VERSION "10.7.5"

NS_ :

BS_:

BU_: ADAS_Info AMP CPD DUMMY_DEBUG DUMMY_ECU EASC HUD MHU XGW_Info

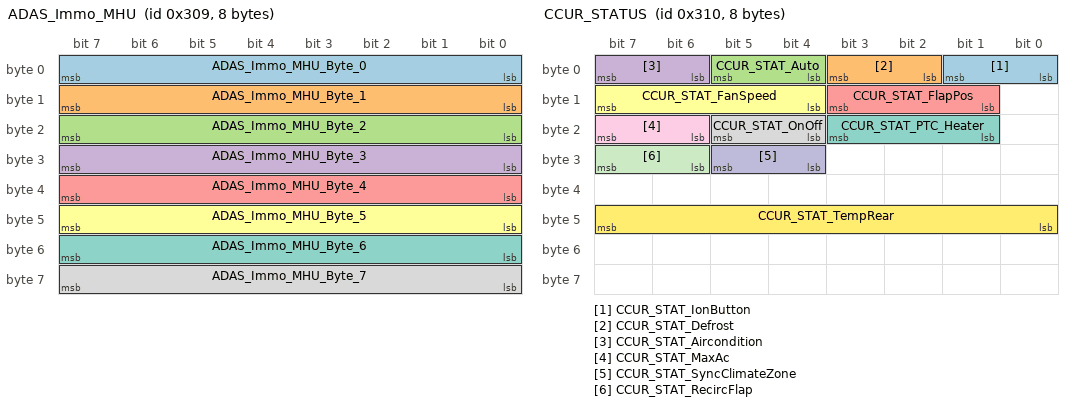
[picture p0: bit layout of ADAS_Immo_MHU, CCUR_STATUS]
BO_ 777 ADAS_Immo_MHU: 8 ADAS_Info
  SG_ ADAS_Immo_MHU_Byte_0 : 7|8@0+ (1,0) [0|255] "-" MHU
  SG_ ADAS_Immo_MHU_Byte_1 : 15|8@0+ (1,0) [0|255] "-" MHU
  SG_ ADAS_Immo_MHU_Byte_2 : 23|8@0+ (1,0) [0|255] "-" MHU
  SG_ ADAS_Immo_MHU_Byte_3 : 31|8@0+ (1,0) [0|255] "-" MHU
  SG_ ADAS_Immo_MHU_Byte_4 : 39|8@0+ (1,0) [0|255] "-" MHU
  SG_ ADAS_Immo_MHU_Byte_5 : 47|8@0+ (1,0) [0|255] "-" MHU
  SG_ ADAS_Immo_MHU_Byte_6 : 55|8@0+ (1,0) [0|255] "-" MHU
  SG_ ADAS_Immo_MHU_Byte_7 : 63|8@0+ (1,0) [0|255] "-" MHU

BO_ 784 CCUR_STATUS: 8 XGW_Info
  SG_ CCUR_STAT_IonButton : 1|2@0+ (1,0) [0|3] "-" MHU
  SG_ CCUR_STAT_Defrost : 3|2@0+ (1,0) [0|3] "" MHU
  SG_ CCUR_STAT_Auto : 5|2@0+ (1,0) [0|3] "" MHU
  SG_ CCUR_STAT_Aircondition : 7|2@0+ (1,0) [0|3] "-" MHU
  SG_ CCUR_STAT_FlapPos : 11|3@0+ (1,0) [0|7] "-" MHU
  SG_ CCUR_STAT_FanSpeed : 15|4@0+ (1,0) [0|15] "-" MHU
  SG_ CCUR_STAT_PTC_Heater : 19|3@0+ (1,0) [0|7] "" MHU
  SG_ CCUR_STAT_OnOff : 21|2@0+ (1,0) [0|3] "Bit" MHU
  SG_ CCUR_STAT_MaxAc : 23|2@0+ (1,0) [0|3] "" MHU
  SG_ CCUR_STAT_SyncClimateZone : 29|2@0+ (1,0) [0|3] "-" MHU
  SG_ CCUR_STAT_RecircFlap : 31|2@0+ (1,0) [0|3] "-" MHU
  SG_ CCUR_STAT_TempRear : 47|8@0+ (0.5,0) [16|32] "Degree C" MHU

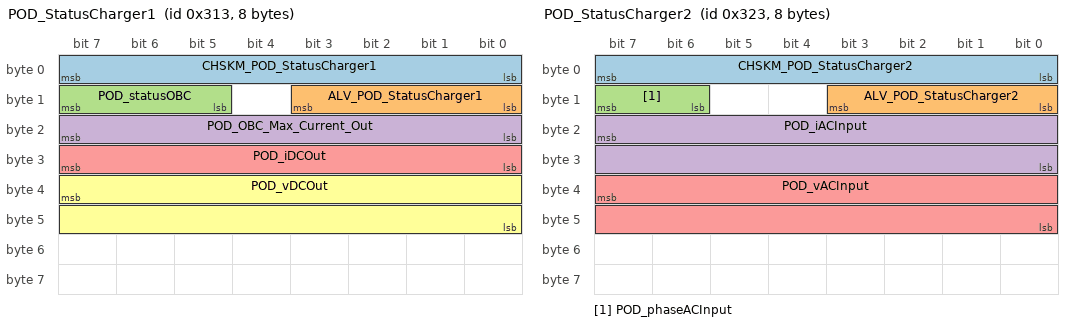
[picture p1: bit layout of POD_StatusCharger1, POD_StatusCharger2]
BO_ 787 POD_StatusCharger1: 8 XGW_Info
  SG_ CHSKM_POD_StatusCharger1 : 7|8@0+ (1,0) [0|255] "" MHU
  SG_ ALV_POD_StatusCharger1 : 11|4@0+ (1,0) [0|14] "" MHU
  SG_ POD_statusOBC : 15|3@0+ (1,0) [0|7] "" MHU
  SG_ POD_OBC_Max_Current_Out : 23|8@0+ (1,0) [0|64] "A" MHU
  SG_ POD_iDCOut : 31|8@0+ (1,0) [0|64] "A" MHU
  SG_ POD_vDCOut : 39|16@0+ (0.0625,0) [0|512] "V" MHU

BO_ 803 POD_StatusCharger2: 8 XGW_Info
  SG_ CHSKM_POD_StatusCharger2 : 7|8@0+ (1,0) [0|255] "" MHU
  SG_ ALV_POD_StatusCharger2 : 11|4@0+ (1,0) [0|14] "" MHU
  SG_ POD_phaseACInput : 15|2@0+ (1,0) [0|3] "" MHU
  SG_ POD_iACInput : 23|16@0+ (0.0625,0) [0|60] "A" MHU
  SG_ POD_vACInput : 39|16@0+ (0.0625,0) [0|512] "V" MHU

BO_ 804 HOD_Heating: 2 MHU
  SG_ Steering_HeatingControl : 7|2@0+ (1,0) [0|3] "" XGW_Info

BO_ 805 STWH_Feedback: 2 XGW_Info
  SG_ Steering_HeatingControlFdbk : 7|2@0+ (1,0) [0|3] "-" MHU

BO_ 806 POD_StatusDCDC1: 8 XGW_Info
  SG_ CHSKM_POD_StatusDCDC1 : 7|8@0+ (1,0) [0|255] "" MHU
  SG_ ALV_POD_StatusDCDC1 : 11|4@0+ (1,0) [0|14] "" MHU
  SG_ POD_statusDCDC : 14|3@0+ (1,0) [0|7] "" MHU
  SG_ POD_DCDC_Max_Current_Out : 23|8@0+ (1,0) [0|250] "A" MHU

BO_ 808 IC_RELATIVIME: 6 MHU
  SG_ T_SEC_COU_REL : 7|32@0+ (1,0) [0|4294967294] "s" XGW_Info
  SG_ T_DAY_COU_ABSL : 39|16@0+ (1,0) [0|65534] "Day" XGW_Info

BO_ 809 BCM_ODO: 8 XGW_Info
  SG_ CRC_BCM_ODO : 7|8@0+ (1,0) [0|255] "" MHU
  SG_ ALIV_BCM_ODO : 11|4@0+ (1,0) [0|14] "" MHU
  SG_ Odometer_BCM : 23|20@0+ (1,0) [0|999999] "km" MHU
  SG_ SECCAN_BCM_ODO : 63|8@0+ (1,0) [0|255] "" MHU

BO_ 816 IC_MILEAGE: 8 XGW_Info
  SG_ MILE_KM : 7|24@0+ (1,0) [0|999999] "km" ADAS_Info,AMP,CPD,EASC,HUD,MHU
  SG_ FLLV_FUTA : 31|8@0+ (1,0) [0|254] "l" ADAS_Info,AMP,CPD,EASC,HUD,MHU
  SG_ RNG : 51|12@0+ (1,0) [0|4094] "km" ADAS_Info,AMP,CPD,EASC,HUD,MHU
  SG_ ST_FLLV_FUTA_SPAR : 55|2@0+ (1,0) [0|3] "" ADAS_Info,AMP,CPD,EASC,HUD,MHU

BO_ 818 BMS_PackInfo: 8 XGW_Info
 SG_ Checksum_0x332 : 7|8@0+ (1,0) [0|255] "" MHU
 SG_ Rolling_Counter_0x332 : 11|4@0+ (1,0) [0|14] "" MHU
 SG_ BMS_PackCNom : 23|16@0+ (0.1,0) [0|6553.5] "kWh" MHU
 SG_ BMS_PackTemp_0x332 : 39|8@0+ (1,-40) [-40|215] "Degree C" MHU

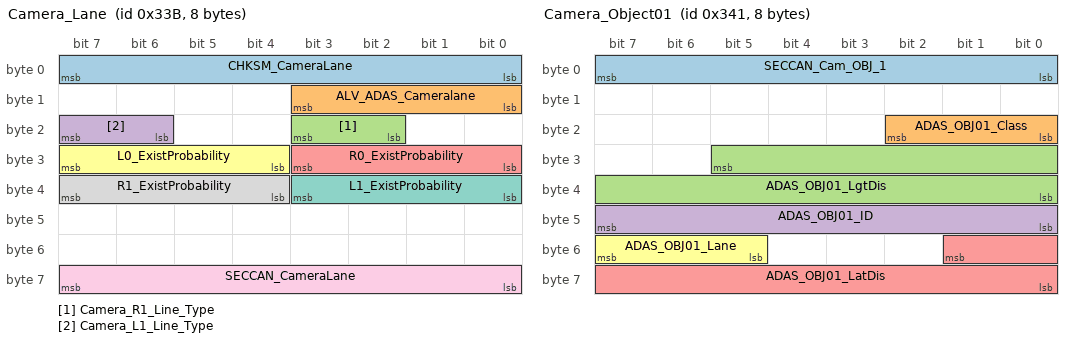
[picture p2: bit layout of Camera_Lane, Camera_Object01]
BO_ 827 Camera_Lane: 8 ADAS_Info
  SG_ CHKSM_CameraLane : 7|8@0+ (1,0) [0|255] "" MHU
  SG_ ALV_ADAS_Cameralane : 11|4@0+ (1,0) [0|14] "" MHU
  SG_ Camera_R1_Line_Type : 19|2@0+ (1,0) [0|3] "-" MHU
  SG_ Camera_L1_Line_Type : 23|2@0+ (1,0) [0|3] "-" MHU
  SG_ R0_ExistProbability : 27|4@0+ (0.1,0) [0|1] "-" MHU
  SG_ L0_ExistProbability : 31|4@0+ (0.1,0) [0|1] "-" MHU
  SG_ L1_ExistProbability : 35|4@0+ (0.1,0) [0|1] "-" MHU
  SG_ R1_ExistProbability : 39|4@0+ (0.1,0) [0|1] "-" MHU
  SG_ SECCAN_CameraLane : 63|8@0+ (1,0) [0|255] "" MHU

BO_ 833 Camera_Object01: 8 ADAS_Info
  SG_ SECCAN_Cam_OBJ_1 : 7|8@0+ (1,0) [0|255] "" MHU
  SG_ ADAS_OBJ01_Class : 18|3@0+ (1,0) [0|7] "-" MHU
  SG_ ADAS_OBJ01_LgtDis : 29|14@0+ (0.025,-10) [-10|399.575] "-" MHU
  SG_ ADAS_OBJ01_ID : 47|8@0+ (1,0) [0|255] "-" MHU
  SG_ ADAS_OBJ01_LatDis : 49|10@0+ (0.0293,-15.0146) [-15.0146|14.9593] "-" MHU
  SG_ ADAS_OBJ01_Lane : 55|3@0+ (1,0) [0|7] "-" MHU

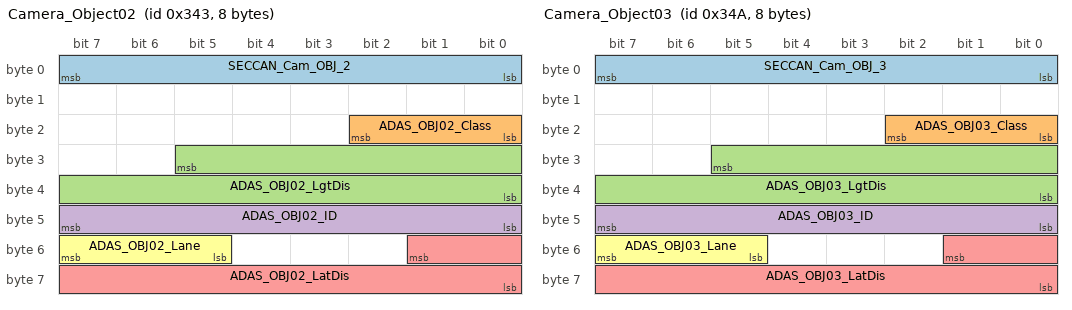
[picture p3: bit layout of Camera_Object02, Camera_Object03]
BO_ 835 Camera_Object02: 8 ADAS_Info
  SG_ SECCAN_Cam_OBJ_2 : 7|8@0+ (1,0) [0|255] "" MHU
  SG_ ADAS_OBJ02_Class : 18|3@0+ (1,0) [0|7] "-" MHU
  SG_ ADAS_OBJ02_LgtDis : 29|14@0+ (0.025,-10) [-10|399.575] "-" MHU
  SG_ ADAS_OBJ02_ID : 47|8@0+ (1,0) [0|255] "-" MHU
  SG_ ADAS_OBJ02_LatDis : 49|10@0+ (0.0293,-15.0146) [-15.0146|14.985] "-" MHU
  SG_ ADAS_OBJ02_Lane : 55|3@0+ (1,0) [0|7] "-" MHU

BO_ 838 POD_StatusDCDC2: 8 XGW_Info
  SG_ CHSKM_POD_StatusDCDC2 : 7|8@0+ (1,0) [0|255] "" MHU
  SG_ ALV_POD_StatusDCDC2 : 11|4@0+ (1,0) [0|14] "" MHU
  SG_ POD_vDCInput : 23|16@0+ (0.0625,0) [0|512] "V" MHU
  SG_ POD_iDCDCOutput : 39|16@0+ (0.0625,0) [0|300] "A" MHU
  SG_ POD_vDCDCOutput : 55|16@0+ (0.0625,0) [0|18] "V" MHU

BO_ 842 Camera_Object03: 8 ADAS_Info
  SG_ SECCAN_Cam_OBJ_3 : 7|8@0+ (1,0) [0|255] "" MHU
  SG_ ADAS_OBJ03_Class : 18|3@0+ (1,0) [0|7] "-" MHU
  SG_ ADAS_OBJ03_LgtDis : 29|14@0+ (0.025,-10) [-10|399.575] "-" MHU
  SG_ ADAS_OBJ03_ID : 47|8@0+ (1,0) [0|255] "-" MHU
  SG_ ADAS_OBJ03_LatDis : 49|10@0+ (0.0293,-15.0146) [-15.0146|14.985] "-" MHU
  SG_ ADAS_OBJ03_Lane : 55|3@0+ (1,0) [0|7] "-" MHU

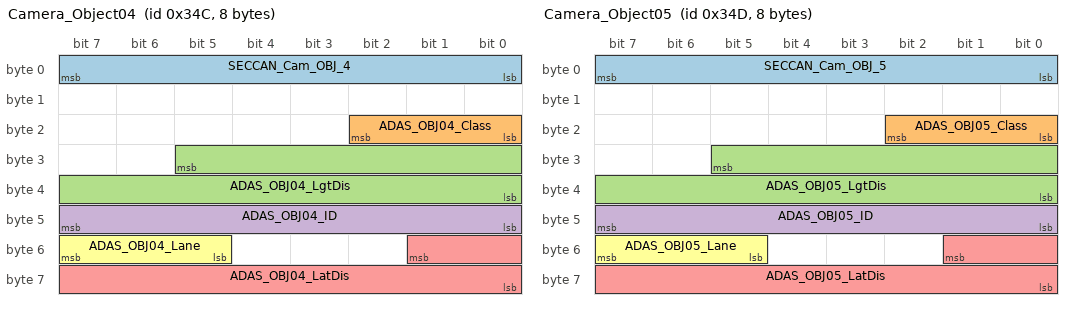
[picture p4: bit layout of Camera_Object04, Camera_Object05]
BO_ 844 Camera_Object04: 8 ADAS_Info
  SG_ SECCAN_Cam_OBJ_4 : 7|8@0+ (1,0) [0|255] "" MHU
  SG_ ADAS_OBJ04_Class : 18|3@0+ (1,0) [0|7] "-" MHU
  SG_ ADAS_OBJ04_LgtDis : 29|14@0+ (0.025,-10) [-10|399.575] "-" MHU
  SG_ ADAS_OBJ04_ID : 47|8@0+ (1,0) [0|255] "-" MHU
  SG_ ADAS_OBJ04_LatDis : 49|10@0+ (0.0293,-15.0146) [-15.0146|14.985] "-" MHU
  SG_ ADAS_OBJ04_Lane : 55|3@0+ (1,0) [0|7] "-" MHU

BO_ 845 Camera_Object05: 8 ADAS_Info
  SG_ SECCAN_Cam_OBJ_5 : 7|8@0+ (1,0) [0|255] "" MHU
  SG_ ADAS_OBJ05_Class : 18|3@0+ (1,0) [0|7] "-" MHU
  SG_ ADAS_OBJ05_LgtDis : 29|14@0+ (0.025,-10) [-10|399.575] "-" MHU
  SG_ ADAS_OBJ05_ID : 47|8@0+ (1,0) [0|255] "-" MHU
  SG_ ADAS_OBJ05_LatDis : 49|10@0+ (0.0293,-15.0146) [-15.0146|14.985] "-" MHU
  SG_ ADAS_OBJ05_Lane : 55|3@0+ (1,0) [0|7] "-" MHU

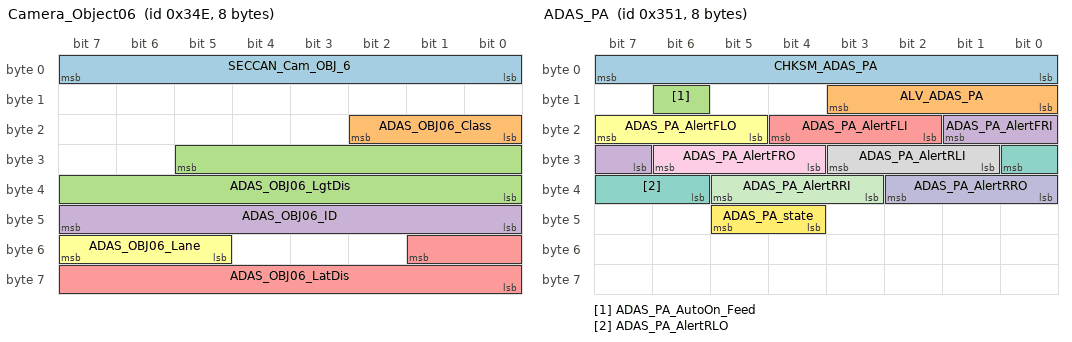
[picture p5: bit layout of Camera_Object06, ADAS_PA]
BO_ 846 Camera_Object06: 8 ADAS_Info
  SG_ SECCAN_Cam_OBJ_6 : 7|8@0+ (1,0) [0|255] "" MHU
  SG_ ADAS_OBJ06_Class : 18|3@0+ (1,0) [0|7] "-" MHU
  SG_ ADAS_OBJ06_LgtDis : 29|14@0+ (0.025,-10) [-10|399.575] "-" MHU
  SG_ ADAS_OBJ06_ID : 47|8@0+ (1,0) [0|255] "-" MHU
  SG_ ADAS_OBJ06_LatDis : 49|10@0+ (0.0293,-15.0146) [-15.0146|14.985] "-" MHU
  SG_ ADAS_OBJ06_Lane : 55|3@0+ (1,0) [0|7] "-" MHU

BO_ 849 ADAS_PA: 8 ADAS_Info
  SG_ CHKSM_ADAS_PA : 7|8@0+ (1,0) [0|255] "" HUD,MHU
  SG_ ALV_ADAS_PA : 11|4@0+ (1,0) [0|14] "" HUD,MHU
  SG_ ADAS_PA_AutoOn_Feed : 14|1@0+ (1,0) [0|1] "-" HUD,MHU
  SG_ ADAS_PA_AlertFRI : 17|3@0+ (1,0) [0|7] "-" HUD,MHU
  SG_ ADAS_PA_AlertFLI : 20|3@0+ (1,0) [0|7] "-" HUD,MHU
  SG_ ADAS_PA_AlertFLO : 23|3@0+ (1,0) [0|7] "-" HUD,MHU
  SG_ ADAS_PA_AlertRLO : 24|3@0+ (1,0) [0|7] "-" HUD,MHU
  SG_ ADAS_PA_AlertRLI : 27|3@0+ (1,0) [0|7] "-" HUD,MHU
  SG_ ADAS_PA_AlertFRO : 30|3@0+ (1,0) [0|7] "-" HUD,MHU
  SG_ ADAS_PA_AlertRRO : 34|3@0+ (1,0) [0|7] "-" HUD,MHU
  SG_ ADAS_PA_AlertRRI : 37|3@0+ (1,0) [0|7] "-" HUD,MHU
  SG_ ADAS_PA_state : 45|2@0+ (1,0) [0|3] "-" HUD,MHU

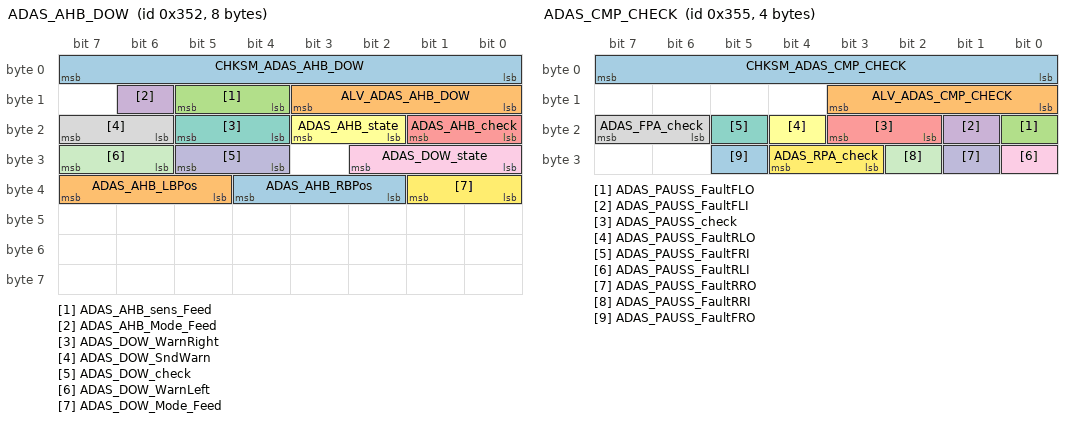
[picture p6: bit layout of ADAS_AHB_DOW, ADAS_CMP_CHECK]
BO_ 850 ADAS_AHB_DOW: 8 ADAS_Info
  SG_ CHKSM_ADAS_AHB_DOW : 7|8@0+ (1,0) [0|255] "" HUD,MHU
  SG_ ALV_ADAS_AHB_DOW : 11|4@0+ (1,0) [0|14] "" HUD,MHU
  SG_ ADAS_AHB_sens_Feed : 13|2@0+ (1,0) [0|3] "-" MHU
  SG_ ADAS_AHB_Mode_Feed : 14|1@0+ (1,0) [0|1] "-" MHU
  SG_ ADAS_AHB_check : 17|2@0+ (1,0) [0|3] "-" MHU
  SG_ ADAS_AHB_state : 19|2@0+ (1,0) [0|3] "-" MHU
  SG_ ADAS_DOW_WarnRight : 21|2@0+ (1,0) [0|3] "-" MHU
  SG_ ADAS_DOW_SndWarn : 23|2@0+ (1,0) [0|3] "-" MHU
  SG_ ADAS_DOW_state : 26|3@0+ (1,0) [0|7] "-" MHU
  SG_ ADAS_DOW_check : 29|2@0+ (1,0) [0|3] "-" MHU
  SG_ ADAS_DOW_WarnLeft : 31|2@0+ (1,0) [0|3] "-" MHU
  SG_ ADAS_DOW_Mode_Feed : 33|2@0+ (1,0) [0|3] "-" MHU
  SG_ ADAS_AHB_RBPos : 36|3@0+ (1,0) [0|7] "" MHU
  SG_ ADAS_AHB_LBPos : 39|3@0+ (1,0) [0|7] "-" MHU

BO_ 851 ADAS_CMP_ACC: 8 ADAS_Info
  SG_ CHKSM_ADAS_ACC : 7|8@0+ (1,0) [0|255] "" HUD,MHU
  SG_ ALV_ADAS_ACC : 11|4@0+ (1,0) [0|14] "" HUD,MHU
  SG_ ADAS_ACC_ObjDetec : 12|1@0+ (1,0) [0|1] "-" HUD,MHU
  SG_ ADAS_ISA_check : 14|2@0+ (1,0) [0|3] "-" HUD,MHU
  SG_ ADAS_ISA_Mode_SW_Feed : 15|1@0+ (1,0) [0|1] "-" HUD,MHU
  SG_ ADAS_TagSpeed_ICON_Feed : 18|3@0+ (1,0) [0|7] "-" HUD,MHU
  SG_ ADAS_ISA_PopUp_Feed : 23|4@0+ (1,0) [0|15] "-" HUD,MHU
  SG_ ADAS_ISA_Btn_Feed : 24|1@0+ (1,0) [0|1] "-" HUD,MHU
  SG_ ADAS_ACC_DistSet_upper_Feed : 25|1@0+ (1,0) [0|1] "-" HUD,MHU
  SG_ ADAS_ACC_TimeGapSet : 28|3@0+ (1,0) [0|7] "-" HUD,MHU
  SG_ ADAS_ACC_State : 31|3@0+ (1,0) [0|7] "-" HUD,MHU
  SG_ ADAS_ACC_TagSpeed : 39|8@0+ (1,0) [0|255] "km/h" HUD,MHU
  SG_ ADAS_ACC_PopUp_Feed : 43|4@0+ (1,0) [0|15] "-" HUD,MHU
  SG_ ADAS_ACC_check : 47|2@0+ (1,0) [0|3] "-" HUD,MHU
  SG_ ADAS_ISA_ICON_Feed : 50|3@0+ (1,0) [0|7] "-" HUD,MHU
  SG_ ADAS_ACC_DistSet_lower_Feed : 51|1@0+ (1,0) [0|1] "-" HUD,MHU
  SG_ ADAS_ACC_SpdSet_upper_Feed : 52|1@0+ (1,0) [0|1] "-" HUD,MHU
  SG_ ADAS_ACC_SpdSet_lower_Feed : 53|1@0+ (1,0) [0|1] "-" HUD,MHU
  SG_ ADAS_ACC_On_Feed : 54|1@0+ (1,0) [0|1] "-" HUD,MHU
  SG_ ADAS_ACC_Set_Feed : 55|1@0+ (1,0) [0|1] "-" HUD,MHU
  SG_ ADAS_ACC_CnlBtn_Feed : 56|1@0+ (1,0) [0|1] "-" HUD,MHU
  SG_ ADAS_ACC_Res_Feed : 57|1@0+ (1,0) [0|1] "-" HUD,MHU
  SG_ ADAS_ACC_ICON_Feed : 60|3@0+ (1,0) [0|7] "-" HUD,MHU
  SG_ ADAS_ISA_Status : 63|3@0+ (1,0) [0|7] "-" HUD,MHU

BO_ 852 MHU_ADAS_req: 8 MHU
  SG_ MHU_FCW_Mode : 1|2@0+ (1,0) [0|3] "-" ADAS_Info
  SG_ MHU_FCW_sens : 3|2@0+ (1,0) [0|3] "-" ADAS_Info
  SG_ MHU_AEB_Mode : 7|2@0+ (1,0) [0|3] "-" ADAS_Info
  SG_ MHU_RAEB_Mode : 9|2@0+ (1,0) [0|3] "-" ADAS_Info
  SG_ MHU_LA_sens : 11|2@0+ (1,0) [0|3] "-" ADAS_Info
  SG_ MHU_LA_AudWarning : 15|2@0+ (1,0) [0|3] "-" ADAS_Info
  SG_ MHU_BSD_On : 17|2@0+ (1,0) [0|3] "-" ADAS_Info
  SG_ MHU_ALC_ON : 19|2@0+ (1,0) [0|3] "-" ADAS_Info
  SG_ MHU_BSD_AudWarning : 21|2@0+ (1,0) [0|3] "-" ADAS_Info
  SG_ MHU_RCTA_On : 23|2@0+ (1,0) [0|3] "-" ADAS_Info
  SG_ MHU_RCTA_sens : 25|2@0+ (1,0) [0|3] "-" ADAS_Info
  SG_ MHU_PA_On : 27|2@0+ (1,0) [0|3] "-" ADAS_Info
  SG_ MHU_AHB_On : 29|2@0+ (1,0) [0|3] "-" ADAS_Info
  SG_ MHU_IA_Mode : 31|2@0+ (1,0) [0|3] "-" ADAS_Info
  SG_ MHU_TSR_Mode : 33|2@0+ (1,0) [0|3] "-" ADAS_Info
  SG_ MHU_DOW_Mode : 35|2@0+ (1,0) [0|3] "-" ADAS_Info
  SG_ MHU_AHB_sens : 37|2@0+ (1,0) [0|3] "-" ADAS_Info
  SG_ MHU_LA_Mode : 41|3@0+ (1,0) [0|7] "-" ADAS_Info
  SG_ MHU_SET_TSR_AudWarn : 45|2@0+ (1,0) [0|3] "-" ADAS_Info
  SG_ MHU_SET_TSR_SLAert : 47|2@0+ (1,0) [0|3] "-" ADAS_Info

BO_ 853 ADAS_CMP_CHECK: 4 ADAS_Info
  SG_ CHKSM_ADAS_CMP_CHECK : 7|8@0+ (1,0) [0|255] "" MHU
  SG_ ALV_ADAS_CMP_CHECK : 11|4@0+ (1,0) [0|14] "" MHU
  SG_ ADAS_PAUSS_FaultFLO : 16|1@0+ (1,0) [0|1] "-" MHU
  SG_ ADAS_PAUSS_FaultFLI : 17|1@0+ (1,0) [0|1] "-" MHU
  SG_ ADAS_PAUSS_check : 19|2@0+ (1,0) [0|3] "-" MHU
  SG_ ADAS_PAUSS_FaultRLO : 20|1@0+ (1,0) [0|1] "-" MHU
  SG_ ADAS_PAUSS_FaultFRI : 21|1@0+ (1,0) [0|1] "-" MHU
  SG_ ADAS_FPA_check : 23|2@0+ (1,0) [0|3] "-" MHU
  SG_ ADAS_PAUSS_FaultRLI : 24|1@0+ (1,0) [0|1] "-" MHU
  SG_ ADAS_PAUSS_FaultRRO : 25|1@0+ (1,0) [0|1] "-" MHU
  SG_ ADAS_PAUSS_FaultRRI : 26|1@0+ (1,0) [0|1] "-" MHU
  SG_ ADAS_RPA_check : 28|2@0+ (1,0) [0|3] "-" MHU
  SG_ ADAS_PAUSS_FaultFRO : 29|1@0+ (1,0) [0|1] "-" MHU

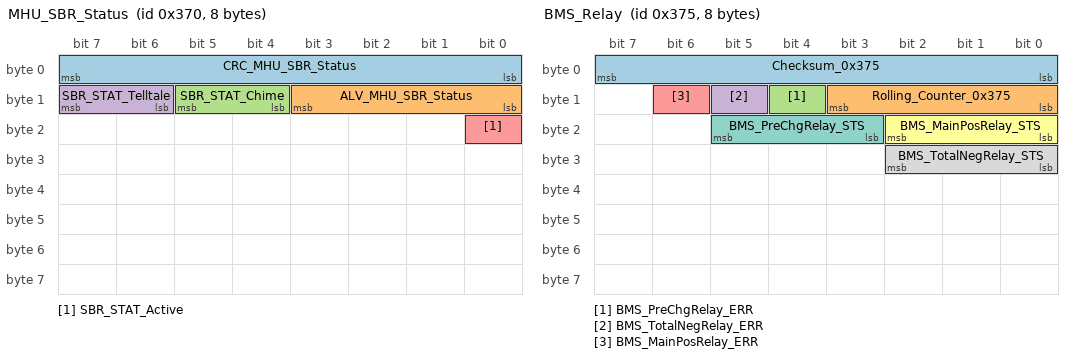
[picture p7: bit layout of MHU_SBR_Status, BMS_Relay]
BO_ 880 MHU_SBR_Status: 8 MHU
  SG_ CRC_MHU_SBR_Status : 7|8@0+ (1,0) [0|255] "" XGW_Info
  SG_ ALV_MHU_SBR_Status : 11|4@0+ (1,0) [0|14] "" XGW_Info
  SG_ SBR_STAT_Chime : 13|2@0+ (1,0) [0|3] "" XGW_Info
  SG_ SBR_STAT_Telltale : 15|2@0+ (1,0) [0|3] "" XGW_Info
  SG_ SBR_STAT_Active : 16|1@0+ (1,0) [0|1] "" XGW_Info

BO_ 885 BMS_Relay: 8 XGW_Info
  SG_ Checksum_0x375 : 7|8@0+ (1,0) [0|255] "" MHU
  SG_ Rolling_Counter_0x375 : 11|4@0+ (1,0) [0|14] "" MHU
  SG_ BMS_PreChgRelay_ERR : 12|1@0+ (1,0) [0|1] "" MHU
  SG_ BMS_TotalNegRelay_ERR : 13|1@0+ (1,0) [0|1] "" MHU
  SG_ BMS_MainPosRelay_ERR : 14|1@0+ (1,0) [0|1] "" MHU
  SG_ BMS_MainPosRelay_STS : 18|3@0+ (1,0) [0|7] "" MHU
  SG_ BMS_PreChgRelay_STS : 21|3@0+ (1,0) [0|7] "" MHU
  SG_ BMS_TotalNegRelay_STS : 26|3@0+ (1,0) [0|7] "" MHU

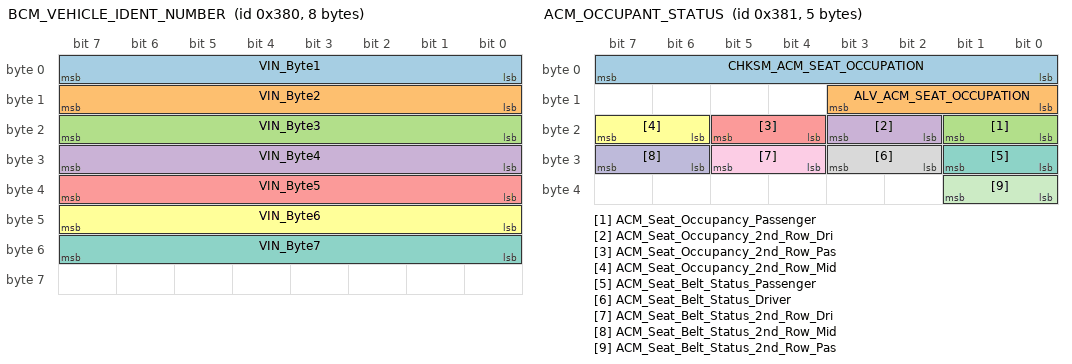
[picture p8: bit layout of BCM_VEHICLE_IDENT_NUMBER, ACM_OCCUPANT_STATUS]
BO_ 896 BCM_VEHICLE_IDENT_NUMBER: 8 XGW_Info
  SG_ VIN_Byte1 : 7|8@0+ (1,0) [0|255] "" ADAS_Info,AMP,CPD,EASC,HUD,MHU
  SG_ VIN_Byte2 : 15|8@0+ (1,0) [0|255] "" ADAS_Info,AMP,CPD,EASC,HUD,MHU
  SG_ VIN_Byte3 : 23|8@0+ (1,0) [0|255] "" ADAS_Info,AMP,CPD,EASC,HUD,MHU
  SG_ VIN_Byte4 : 31|8@0+ (1,0) [0|255] "" ADAS_Info,AMP,CPD,EASC,HUD,MHU
  SG_ VIN_Byte5 : 39|8@0+ (1,0) [0|255] "" ADAS_Info,AMP,CPD,EASC,HUD,MHU
  SG_ VIN_Byte6 : 47|8@0+ (1,0) [0|255] "" ADAS_Info,AMP,CPD,EASC,HUD,MHU
  SG_ VIN_Byte7 : 55|8@0+ (1,0) [0|255] "" ADAS_Info,AMP,CPD,EASC,HUD,MHU

BO_ 897 ACM_OCCUPANT_STATUS: 5 XGW_Info
  SG_ CHKSM_ACM_SEAT_OCCUPATION : 7|8@0+ (1,0) [0|255] "" MHU
  SG_ ALV_ACM_SEAT_OCCUPATION : 11|4@0+ (1,0) [0|14] "" MHU
  SG_ ACM_Seat_Occupancy_Passenger : 17|2@0+ (1,0) [0|3] "" MHU
  SG_ ACM_Seat_Occupancy_2nd_Row_Dri : 19|2@0+ (1,0) [0|3] "" MHU
  SG_ ACM_Seat_Occupancy_2nd_Row_Pas : 21|2@0+ (1,0) [0|3] "-" MHU
  SG_ ACM_Seat_Occupancy_2nd_Row_Mid : 23|2@0+ (1,0) [0|3] "-" MHU
  SG_ ACM_Seat_Belt_Status_Passenger : 25|2@0+ (1,0) [0|3] "" MHU
  SG_ ACM_Seat_Belt_Status_Driver : 27|2@0+ (1,0) [0|3] "" MHU
  SG_ ACM_Seat_Belt_Status_2nd_Row_Dri : 29|2@0+ (1,0) [0|3] "-" MHU
  SG_ ACM_Seat_Belt_Status_2nd_Row_Mid : 31|2@0+ (1,0) [0|3] "" MHU
  SG_ ACM_Seat_Belt_Status_2nd_Row_Pas : 33|2@0+ (1,0) [0|3] "-" MHU

BO_ 905 VCU_Sts3: 8 XGW_Info
  SG_ VCU_IMMO_Sts : 35|2@0+ (1,0) [0|3] "" MHU
  SG_ SECCAN_VCU_IMMO_Sts : 63|8@0+ (1,0) [0|255] "" Vector__XXX

BO_ 915 MHU_HudPositionSetting: 3 MHU
  SG_ MHU_SET_HudRotateLvl : 7|4@0+ (1,0) [0|15] "-" HUD
  SG_ MHU_SET_HudHeightLvl : 15|5@0+ (1,0) [0|31] "-" HUD

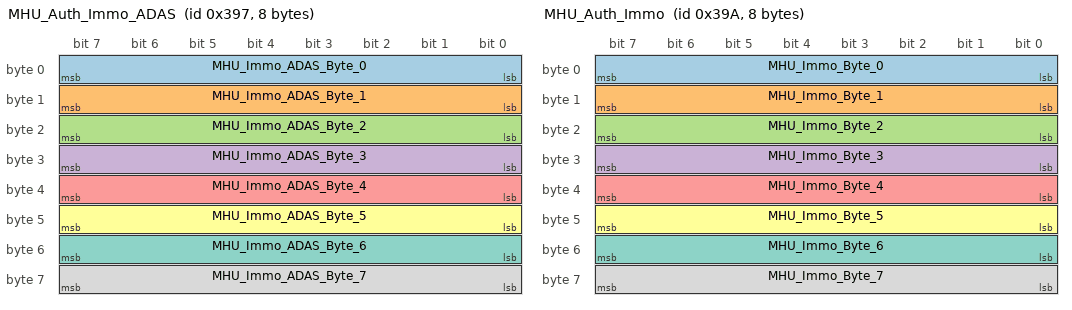
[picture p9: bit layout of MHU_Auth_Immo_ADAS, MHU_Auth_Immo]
BO_ 919 MHU_Auth_Immo_ADAS: 8 MHU
  SG_ MHU_Immo_ADAS_Byte_0 : 7|8@0+ (1,0) [0|255] "-" ADAS_Info
  SG_ MHU_Immo_ADAS_Byte_1 : 15|8@0+ (1,0) [0|255] "-" ADAS_Info
  SG_ MHU_Immo_ADAS_Byte_2 : 23|8@0+ (1,0) [0|255] "-" ADAS_Info
  SG_ MHU_Immo_ADAS_Byte_3 : 31|8@0+ (1,0) [0|255] "-" ADAS_Info
  SG_ MHU_Immo_ADAS_Byte_4 : 39|8@0+ (1,0) [0|255] "-" ADAS_Info
  SG_ MHU_Immo_ADAS_Byte_5 : 47|8@0+ (1,0) [0|255] "-" ADAS_Info
  SG_ MHU_Immo_ADAS_Byte_6 : 55|8@0+ (1,0) [0|255] "-" ADAS_Info
  SG_ MHU_Immo_ADAS_Byte_7 : 63|8@0+ (1,0) [0|255] "-" ADAS_Info

BO_ 922 MHU_Auth_Immo: 8 MHU
  SG_ MHU_Immo_Byte_0 : 7|8@0+ (1,0) [0|255] "-" XGW_Info
  SG_ MHU_Immo_Byte_1 : 15|8@0+ (1,0) [0|255] "-" XGW_Info
  SG_ MHU_Immo_Byte_2 : 23|8@0+ (1,0) [0|255] "" XGW_Info
  SG_ MHU_Immo_Byte_3 : 31|8@0+ (1,0) [0|255] "" XGW_Info
  SG_ MHU_Immo_Byte_4 : 39|8@0+ (1,0) [0|255] "" XGW_Info
  SG_ MHU_Immo_Byte_5 : 47|8@0+ (1,0) [0|255] "" XGW_Info
  SG_ MHU_Immo_Byte_6 : 55|8@0+ (1,0) [0|255] "" XGW_Info
  SG_ MHU_Immo_Byte_7 : 63|8@0+ (1,0) [0|255] "-" XGW_Info

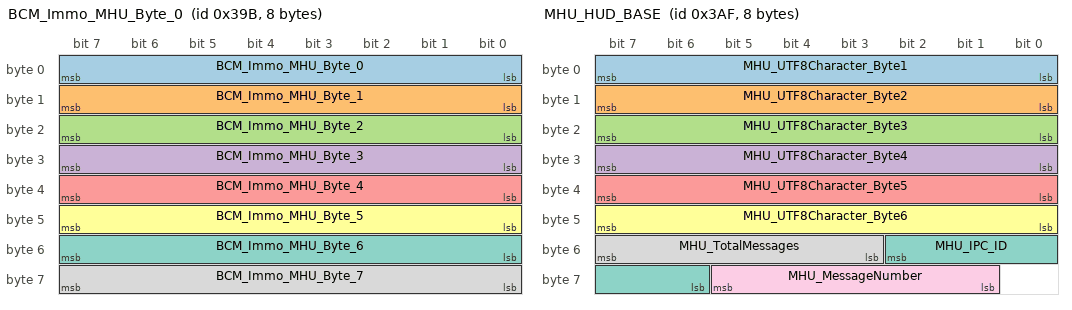
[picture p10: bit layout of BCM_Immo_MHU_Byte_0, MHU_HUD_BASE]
BO_ 923 BCM_Immo_MHU_Byte_0: 8 XGW_Info
  SG_ BCM_Immo_MHU_Byte_0 : 7|8@0+ (1,0) [0|255] "-" MHU
  SG_ BCM_Immo_MHU_Byte_1 : 15|8@0+ (1,0) [0|255] "-" MHU
  SG_ BCM_Immo_MHU_Byte_2 : 23|8@0+ (1,0) [0|255] "-" MHU
  SG_ BCM_Immo_MHU_Byte_3 : 31|8@0+ (1,0) [0|255] "-" MHU
  SG_ BCM_Immo_MHU_Byte_4 : 39|8@0+ (1,0) [0|255] "-" MHU
  SG_ BCM_Immo_MHU_Byte_5 : 47|8@0+ (1,0) [0|255] "" MHU
  SG_ BCM_Immo_MHU_Byte_6 : 55|8@0+ (1,0) [0|255] "-" MHU
  SG_ BCM_Immo_MHU_Byte_7 : 63|8@0+ (1,0) [0|255] "-" MHU

BO_ 925 BCM_HighBeam_PosReq: 4 XGW_Info
  SG_ BCM_AHB_Override : 17|2@0+ (1,0) [0|3] "" MHU

BO_ 943 MHU_HUD_BASE: 8 MHU
  SG_ MHU_UTF8Character_Byte1 : 7|8@0+ (1,0) [0|255] "-" HUD
  SG_ MHU_UTF8Character_Byte2 : 15|8@0+ (1,0) [0|255] "-" HUD
  SG_ MHU_UTF8Character_Byte3 : 23|8@0+ (1,0) [0|255] "-" HUD
  SG_ MHU_UTF8Character_Byte4 : 31|8@0+ (1,0) [0|255] "-" HUD
  SG_ MHU_UTF8Character_Byte5 : 39|8@0+ (1,0) [0|255] "-" HUD
  SG_ MHU_UTF8Character_Byte6 : 47|8@0+ (1,0) [0|255] "-" HUD
  SG_ MHU_IPC_ID : 50|5@0+ (1,0) [0|15] "Bit" HUD
  SG_ MHU_TotalMessages : 55|5@0+ (1,0) [0|31] "-" HUD
  SG_ MHU_MessageNumber : 61|5@0+ (1,0) [0|31] "-" HUD

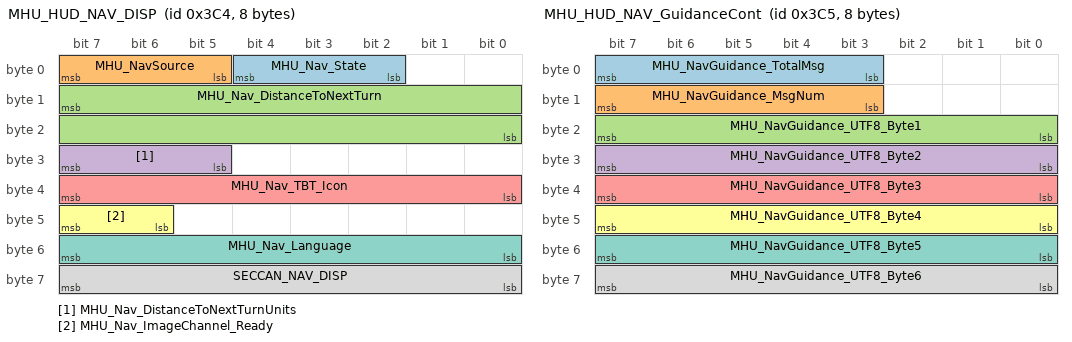
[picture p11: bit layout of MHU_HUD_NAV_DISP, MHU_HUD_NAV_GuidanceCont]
BO_ 964 MHU_HUD_NAV_DISP: 8 MHU
  SG_ MHU_Nav_State : 4|3@0+ (1,0) [0|7] "-" HUD
  SG_ MHU_NavSource : 7|3@0+ (1,0) [0|7] "-" HUD
  SG_ MHU_Nav_DistanceToNextTurn : 15|16@0+ (1,0) [0|65535] "-" HUD
  SG_ MHU_Nav_DistanceToNextTurnUnits : 31|3@0+ (1,0) [0|7] "-" HUD
  SG_ MHU_Nav_TBT_Icon : 39|8@0+ (1,0) [0|255] "-" HUD
  SG_ MHU_Nav_ImageChannel_Ready : 47|2@0+ (1,0) [0|3] "-" HUD
  SG_ MHU_Nav_Language : 55|8@0+ (1,0) [0|255] "" HUD
  SG_ SECCAN_NAV_DISP : 63|8@0+ (1,0) [0|255] "" HUD

BO_ 965 MHU_HUD_NAV_GuidanceCont: 8 MHU
  SG_ MHU_NavGuidance_TotalMsg : 7|5@0+ (1,0) [0|31] "-" HUD
  SG_ MHU_NavGuidance_MsgNum : 15|5@0+ (1,0) [0|31] "-" HUD
  SG_ MHU_NavGuidance_UTF8_Byte1 : 23|8@0+ (1,0) [0|255] "" HUD
  SG_ MHU_NavGuidance_UTF8_Byte2 : 31|8@0+ (1,0) [0|255] "" HUD
  SG_ MHU_NavGuidance_UTF8_Byte3 : 39|8@0+ (1,0) [0|255] "" HUD
  SG_ MHU_NavGuidance_UTF8_Byte4 : 47|8@0+ (1,0) [0|255] "" HUD
  SG_ MHU_NavGuidance_UTF8_Byte5 : 55|8@0+ (1,0) [0|255] "" HUD
  SG_ MHU_NavGuidance_UTF8_Byte6 : 63|8@0+ (1,0) [0|255] "" HUD

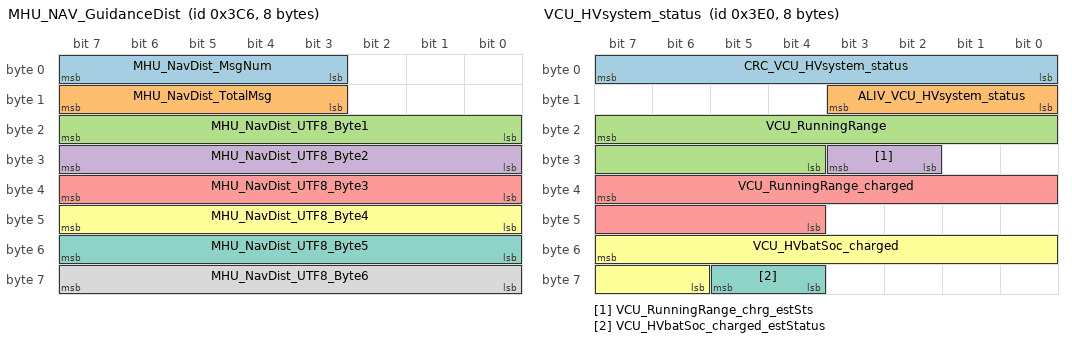
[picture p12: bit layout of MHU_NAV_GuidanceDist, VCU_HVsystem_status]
BO_ 966 MHU_NAV_GuidanceDist: 8 MHU
  SG_ MHU_NavDist_MsgNum : 7|5@0+ (1,0) [0|31] "" HUD
  SG_ MHU_NavDist_TotalMsg : 15|5@0+ (1,0) [0|31] "" HUD
  SG_ MHU_NavDist_UTF8_Byte1 : 23|8@0+ (1,0) [0|255] "" HUD
  SG_ MHU_NavDist_UTF8_Byte2 : 31|8@0+ (1,0) [0|255] "" HUD
  SG_ MHU_NavDist_UTF8_Byte3 : 39|8@0+ (1,0) [0|255] "" HUD
  SG_ MHU_NavDist_UTF8_Byte4 : 47|8@0+ (1,0) [0|255] "" HUD
  SG_ MHU_NavDist_UTF8_Byte5 : 55|8@0+ (1,0) [0|255] "" HUD
  SG_ MHU_NavDist_UTF8_Byte6 : 63|8@0+ (1,0) [0|255] "" HUD

BO_ 992 VCU_HVsystem_status: 8 XGW_Info
  SG_ CRC_VCU_HVsystem_status : 7|8@0+ (1,0) [0|255] "" HUD,MHU
  SG_ ALIV_VCU_HVsystem_status : 11|4@0+ (1,0) [0|14] "" HUD,MHU
  SG_ VCU_RunningRange : 23|12@0+ (0.5,0) [0|2047] "km" HUD,MHU
  SG_ VCU_RunningRange_chrg_estSts : 27|2@0+ (1,0) [0|3] "-" HUD,MHU
  SG_ VCU_RunningRange_charged : 39|12@0+ (0.5,0) [0|2047] "km" HUD,MHU
  SG_ VCU_HVbatSoc_charged : 55|10@0+ (0.1,0) [0|100] "%" HUD,MHU
  SG_ VCU_HVbatSoc_charged_estStatus : 61|2@0+ (1,0) [0|3] "-" HUD,MHU

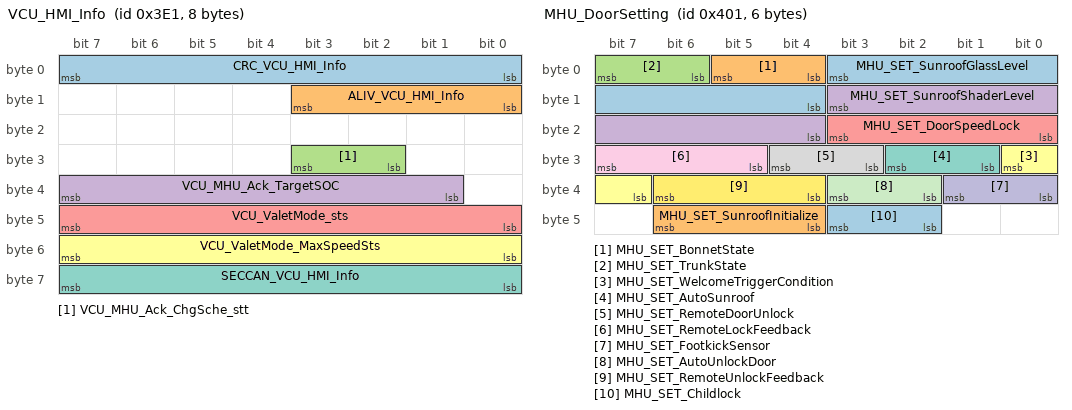
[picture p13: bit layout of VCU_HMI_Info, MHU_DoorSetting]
BO_ 993 VCU_HMI_Info: 8 XGW_Info
  SG_ CRC_VCU_HMI_Info : 7|8@0+ (1,0) [0|255] "" MHU
  SG_ ALIV_VCU_HMI_Info : 11|4@0+ (1,0) [0|14] "" MHU
  SG_ VCU_MHU_Ack_ChgSche_stt : 27|2@0+ (1,0) [0|3] "" MHU
  SG_ VCU_MHU_Ack_TargetSOC : 39|7@0+ (1,0) [10|100] "%" MHU
  SG_ VCU_ValetMode_sts : 47|8@0+ (1,0) [0|255] "" MHU
  SG_ VCU_ValetMode_MaxSpeedSts : 55|8@0+ (1,0) [0|255] "km/h" MHU
  SG_ SECCAN_VCU_HMI_Info : 63|8@0+ (1,0) [0|255] "" MHU

BO_ 1015 MFS_Control_Button: 8 XGW_Info
  SG_ CHSKM_MFS_Control_Button : 7|8@0+ (1,0) [0|255] "" ADAS_Info,HUD,MHU
  SG_ ALV_MFS_Control_Button : 11|4@0+ (1,0) [0|14] "" ADAS_Info,HUD,MHU
  SG_ MFS_VoiceRecognitionOn_Off : 15|3@0+ (1,0) [0|4] "Bit" HUD,MHU
  SG_ MFS_ISAControl : 17|2@0+ (1,0) [0|3] "Bit" ADAS_Info,HUD,MHU
  SG_ MFS_CruiseSpeedIncrease : 20|3@0+ (1,0) [0|4] "Bit" ADAS_Info,HUD,MHU
  SG_ MFS_TelephoneCall_EndCall : 23|3@0+ (1,0) [0|4] "Bit" HUD,MHU
  SG_ MFS_LKAControl : 25|2@0+ (1,0) [0|3] "Bit" ADAS_Info,HUD,MHU
  SG_ MFS_CruiseGapIncrease : 28|3@0+ (1,0) [0|4] "Bit" ADAS_Info,HUD,MHU
  SG_ MFS_CruiseOn_Off : 31|3@0+ (1,0) [0|4] "Bit" ADAS_Info,HUD,MHU
  SG_ MFS_CruiseGapDecrease : 34|3@0+ (1,0) [0|4] "Bit" ADAS_Info,HUD,MHU
  SG_ MFS_CAN_RESControl : 36|2@0+ (1,0) [0|3] "-" ADAS_Info,HUD
  SG_ MFS_CruiseSpeedDecrease : 39|3@0+ (1,0) [0|4] "Bit" ADAS_Info,HUD,MHU
  SG_ MFS_M2Control : 41|2@0+ (1,0) [0|3] "Bit" ADAS_Info,HUD
  SG_ MFS_SourseControl : 44|3@0+ (1,0) [0|4] "Bit" HUD,MHU
  SG_ MFS_UpControl : 47|3@0+ (1,0) [0|4] "Bit" EASC,HUD,MHU
  SG_ MFS_DownControl : 52|3@0+ (1,0) [0|4] "Bit" EASC,HUD,MHU
  SG_ MFS_LeftControl : 55|3@0+ (1,0) [0|4] "Bit" EASC,HUD,MHU
  SG_ MFS_Failure : 57|1@0+ (1,0) [0|1] "Bit" ADAS_Info,HUD,MHU
  SG_ MFS_RightControl : 60|3@0+ (1,0) [0|4] "Bit" EASC,HUD,MHU
  SG_ MFS_OK_Control : 63|3@0+ (1,0) [0|4] "Bit" HUD,MHU

BO_ 1020 XGW_FOTA_StsConfirm: 4 XGW_Info
  SG_ CRC_XGW_FOTA_StsConfirm : 7|8@0+ (1,0) [0|255] "" MHU
  SG_ ALIV_XGW_FOTA_StsConfirm : 11|4@0+ (1,0) [0|14] "" MHU
  SG_ XGW_FOTA_StateConfirm : 15|4@0+ (1,0) [0|14] "-" MHU
  SG_ XGW_FOTA_Error_Code : 23|8@0+ (1,0) [0|255] "-" MHU

BO_ 1025 MHU_DoorSetting: 6 MHU
  SG_ MHU_SET_SunroofGlassLevel : 3|8@0+ (1,0) [0|255] "%" XGW_Info
  SG_ MHU_SET_BonnetState : 5|2@0+ (1,0) [0|3] "-" XGW_Info
  SG_ MHU_SET_TrunkState : 7|2@0+ (1,0) [0|3] "-" XGW_Info
  SG_ MHU_SET_SunroofShaderLevel : 11|8@0+ (1,0) [0|255] "%" XGW_Info
  SG_ MHU_SET_DoorSpeedLock : 19|4@0+ (1,0) [0|7] "" XGW_Info
  SG_ MHU_SET_WelcomeTriggerCondition : 24|2@0+ (1,0) [0|3] "" XGW_Info
  SG_ MHU_SET_AutoSunroof : 26|2@0+ (1,0) [0|3] "" XGW_Info
  SG_ MHU_SET_RemoteDoorUnlock : 28|2@0+ (1,0) [0|3] "-" XGW_Info
  SG_ MHU_SET_RemoteLockFeedback : 31|3@0+ (1,0) [0|7] "-" XGW_Info
  SG_ MHU_SET_FootkickSensor : 33|2@0+ (1,0) [0|3] "-" XGW_Info
  SG_ MHU_SET_AutoUnlockDoor : 35|2@0+ (1,0) [0|3] "" XGW_Info
  SG_ MHU_SET_RemoteUnlockFeedback : 38|3@0+ (1,0) [0|7] "" XGW_Info
  SG_ MHU_SET_Childlock : 43|2@0+ (1,0) [0|3] "" XGW_Info
  SG_ MHU_SET_SunroofInitialize : 46|3@0+ (1,0) [0|7] "" XGW_Info

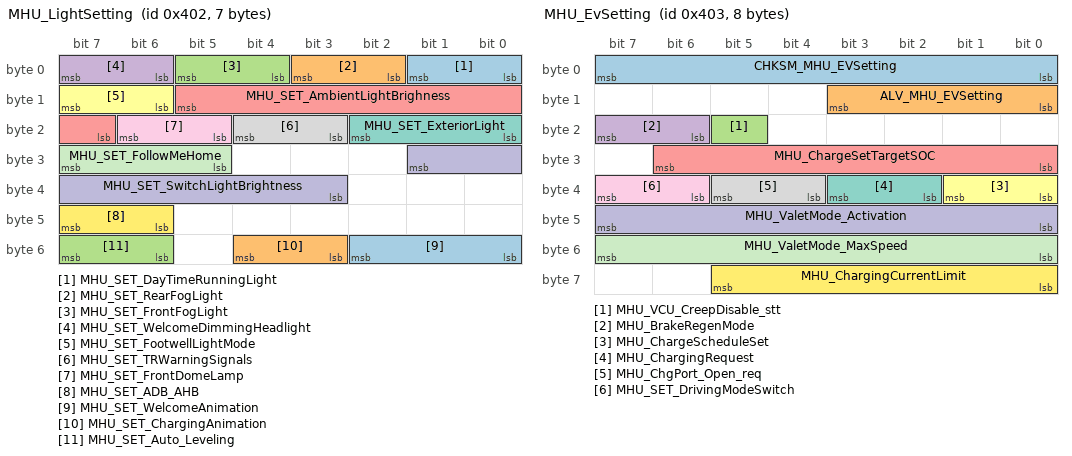
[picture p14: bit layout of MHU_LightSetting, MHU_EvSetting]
BO_ 1026 MHU_LightSetting: 7 MHU
  SG_ MHU_SET_DayTimeRunningLight : 1|2@0+ (1,0) [0|3] "-" XGW_Info
  SG_ MHU_SET_RearFogLight : 3|2@0+ (1,0) [0|3] "" XGW_Info
  SG_ MHU_SET_FrontFogLight : 5|2@0+ (1,0) [0|3] "" XGW_Info
  SG_ MHU_SET_WelcomeDimmingHeadlight : 7|2@0+ (1,0) [0|3] "" XGW_Info
  SG_ MHU_SET_AmbientLightBrighness : 13|7@0+ (1,0) [0|100] "%" XGW_Info
  SG_ MHU_SET_FootwellLightMode : 15|2@0+ (1,0) [0|3] "-" XGW_Info
  SG_ MHU_SET_ExteriorLight : 18|3@0+ (1,0) [0|7] "" XGW_Info
  SG_ MHU_SET_TRWarningSignals : 20|2@0+ (1,0) [0|3] "" XGW_Info
  SG_ MHU_SET_FrontDomeLamp : 22|2@0+ (1,0) [0|3] "" XGW_Info
  SG_ MHU_SET_SwitchLightBrightness : 25|7@0+ (1,0) [0|100] "%" XGW_Info
  SG_ MHU_SET_FollowMeHome : 31|3@0+ (1,0) [0|7] "" XGW_Info
  SG_ MHU_SET_ADB_AHB : 47|2@0+ (1,0) [0|3] "" XGW_Info
  SG_ MHU_SET_WelcomeAnimation : 50|3@0+ (1,0) [0|5] "" XGW_Info
  SG_ MHU_SET_ChargingAnimation : 52|2@0+ (1,0) [0|3] "" XGW_Info
  SG_ MHU_SET_Auto_Leveling : 55|2@0+ (1,0) [0|3] "-" XGW_Info

BO_ 1027 MHU_EvSetting: 8 MHU
  SG_ CHKSM_MHU_EVSetting : 7|8@0+ (1,0) [0|255] "" XGW_Info
  SG_ ALV_MHU_EVSetting : 11|4@0+ (1,0) [0|14] "" XGW_Info
  SG_ MHU_VCU_CreepDisable_stt : 21|1@0+ (1,0) [0|1] "" XGW_Info
  SG_ MHU_BrakeRegenMode : 23|2@0+ (1,0) [0|3] "" XGW_Info
  SG_ MHU_ChargeSetTargetSOC : 30|7@0+ (1,0) [10|100] "%" XGW_Info
  SG_ MHU_ChargeScheduleSet : 33|2@0+ (1,0) [0|3] "" XGW_Info
  SG_ MHU_ChargingRequest : 35|2@0+ (1,0) [0|3] "-" XGW_Info
  SG_ MHU_ChgPort_Open_req : 37|2@0+ (1,0) [0|3] "-" XGW_Info
  SG_ MHU_SET_DrivingModeSwitch : 39|2@0+ (1,0) [0|3] "-" XGW_Info
  SG_ MHU_ValetMode_Activation : 47|8@0+ (1,0) [0|255] "" ADAS_Info,XGW_Info
  SG_ MHU_ValetMode_MaxSpeed : 55|8@0+ (1,0) [0|255] "km/h" XGW_Info
  SG_ MHU_ChargingCurrentLimit : 61|6@0+ (1,0) [0|62] "A" XGW_Info

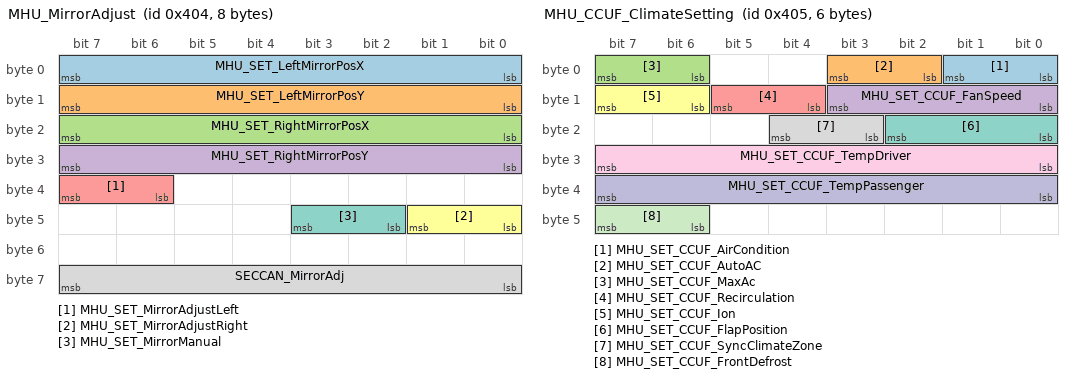
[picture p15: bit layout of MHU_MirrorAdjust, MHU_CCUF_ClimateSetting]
BO_ 1028 MHU_MirrorAdjust: 8 MHU
  SG_ MHU_SET_LeftMirrorPosX : 7|8@0+ (1,-15) [-15|15] "deg" XGW_Info
  SG_ MHU_SET_LeftMirrorPosY : 15|8@0+ (1,-15) [-15|15] "deg" XGW_Info
  SG_ MHU_SET_RightMirrorPosX : 23|8@0+ (1,-15) [-15|15] "deg" XGW_Info
  SG_ MHU_SET_RightMirrorPosY : 31|8@0+ (1,-15) [-15|15] "deg" XGW_Info
  SG_ MHU_SET_MirrorAdjustLeft : 39|2@0+ (1,0) [0|3] "-" XGW_Info
  SG_ MHU_SET_MirrorAdjustRight : 41|2@0+ (1,0) [0|3] "-" XGW_Info
  SG_ MHU_SET_MirrorManual : 43|2@0+ (1,0) [0|3] "" XGW_Info
  SG_ SECCAN_MirrorAdj : 63|8@0+ (1,0) [0|255] "" XGW_Info

BO_ 1029 MHU_CCUF_ClimateSetting: 6 MHU
  SG_ MHU_SET_CCUF_AirCondition : 1|2@0+ (1,0) [0|3] "" XGW_Info
  SG_ MHU_SET_CCUF_AutoAC : 3|2@0+ (1,0) [0|3] "" XGW_Info
  SG_ MHU_SET_CCUF_MaxAc : 7|2@0+ (1,0) [0|3] "" XGW_Info
  SG_ MHU_SET_CCUF_FanSpeed : 11|4@0+ (1,0) [0|7] "-" XGW_Info
  SG_ MHU_SET_CCUF_Recirculation : 13|2@0+ (1,0) [0|3] "" XGW_Info
  SG_ MHU_SET_CCUF_Ion : 15|2@0+ (1,0) [0|3] "-" XGW_Info
  SG_ MHU_SET_CCUF_FlapPosition : 18|3@0+ (1,0) [0|7] "-" XGW_Info
  SG_ MHU_SET_CCUF_SyncClimateZone : 20|2@0+ (1,0) [0|3] "-" XGW_Info
  SG_ MHU_SET_CCUF_TempDriver : 31|8@0+ (0.5,0) [16|32] "Degree C" XGW_Info
  SG_ MHU_SET_CCUF_TempPassenger : 39|8@0+ (0.5,0) [16|32] "Degree C" XGW_Info
  SG_ MHU_SET_CCUF_FrontDefrost : 47|2@0+ (1,0) [0|3] "" XGW_Info

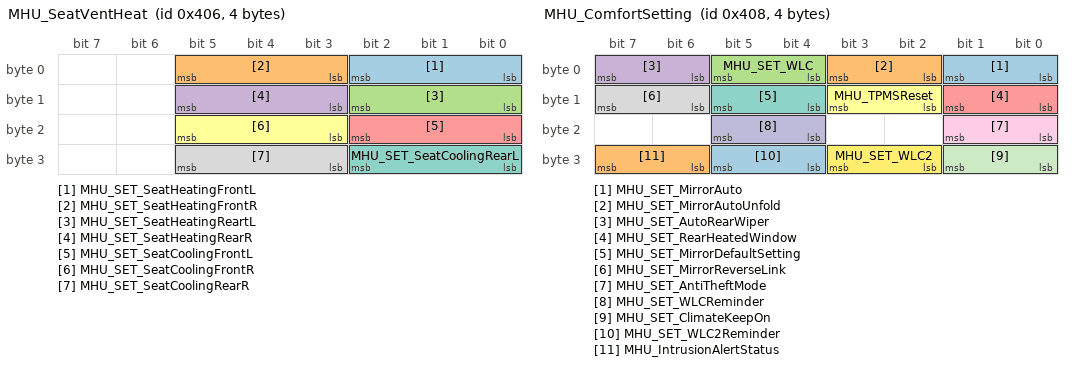
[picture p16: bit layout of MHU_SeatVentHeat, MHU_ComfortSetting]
BO_ 1030 MHU_SeatVentHeat: 4 MHU
  SG_ MHU_SET_SeatHeatingFrontL : 2|3@0+ (1,0) [0|7] "-" XGW_Info
  SG_ MHU_SET_SeatHeatingFrontR : 5|3@0+ (1,0) [0|7] "-" XGW_Info
  SG_ MHU_SET_SeatHeatingReartL : 10|3@0+ (1,0) [0|7] "-" XGW_Info
  SG_ MHU_SET_SeatHeatingRearR : 13|3@0+ (1,0) [0|7] "-" XGW_Info
  SG_ MHU_SET_SeatCoolingFrontL : 18|3@0+ (1,0) [0|7] "-" XGW_Info
  SG_ MHU_SET_SeatCoolingFrontR : 21|3@0+ (1,0) [0|7] "" XGW_Info
  SG_ MHU_SET_SeatCoolingRearL : 26|3@0+ (1,0) [0|7] "" XGW_Info
  SG_ MHU_SET_SeatCoolingRearR : 29|3@0+ (1,0) [0|7] "-" XGW_Info

BO_ 1032 MHU_ComfortSetting: 4 MHU
  SG_ MHU_SET_MirrorAuto : 1|2@0+ (1,0) [0|3] "" XGW_Info
  SG_ MHU_SET_MirrorAutoUnfold : 3|2@0+ (1,0) [0|3] "" XGW_Info
  SG_ MHU_SET_WLC : 5|2@0+ (1,0) [0|3] "-" XGW_Info
  SG_ MHU_SET_AutoRearWiper : 7|2@0+ (1,0) [0|3] "-" XGW_Info
  SG_ MHU_SET_RearHeatedWindow : 9|2@0+ (1,0) [0|3] "" XGW_Info
  SG_ MHU_TPMSReset : 11|2@0+ (1,0) [0|3] "" XGW_Info
  SG_ MHU_SET_MirrorDefaultSetting : 13|2@0+ (1,0) [0|3] "" XGW_Info
  SG_ MHU_SET_MirrorReverseLink : 15|2@0+ (1,0) [0|3] "-" XGW_Info
  SG_ MHU_SET_AntiTheftMode : 17|2@0+ (1,0) [0|3] "" XGW_Info
  SG_ MHU_SET_WLCReminder : 21|2@0+ (1,0) [0|3] "" XGW_Info
  SG_ MHU_SET_ClimateKeepOn : 25|2@0+ (1,0) [0|3] "" XGW_Info
  SG_ MHU_SET_WLC2 : 27|2@0+ (1,0) [0|3] "-" XGW_Info
  SG_ MHU_SET_WLC2Reminder : 29|2@0+ (1,0) [0|3] "-" XGW_Info
  SG_ MHU_IntrusionAlertStatus : 31|2@0+ (1,0) [0|3] "-" XGW_Info

BO_ 1033 ADAS_WarnMsg: 8 ADAS_Info
  SG_ CHSKM_ADAS_WarnMsg : 7|8@0+ (1,0) [0|255] "" MHU
  SG_ ALV_ADAS_WarnMsg : 11|4@0+ (1,0) [0|14] "" MHU
  SG_ ADAS_Warning_Flag_1 : 12|1@0+ (1,0) [0|1] "" MHU
  SG_ ADAS_Warning_Flag_2 : 13|1@0+ (1,0) [0|1] "" MHU
  SG_ ADAS_Warning_Flag_3 : 14|1@0+ (1,0) [0|1] "" MHU
  SG_ ADAS_Warning_Flag_4 : 15|1@0+ (1,0) [0|1] "" MHU
  SG_ ADAS_Warning_Flag_5 : 16|1@0+ (1,0) [0|1] "" MHU
  SG_ ADAS_Warning_Flag_6 : 17|1@0+ (1,0) [0|1] "" MHU
  SG_ ADAS_Warning_Flag_7 : 18|1@0+ (1,0) [0|1] "" MHU
  SG_ ADAS_Warning_Flag_8 : 19|1@0+ (1,0) [0|1] "" MHU
  SG_ ADAS_Warning_Flag_9 : 20|1@0+ (1,0) [0|1] "" MHU
  SG_ ADAS_Warning_Flag_10 : 21|1@0+ (1,0) [0|1] "" MHU
  SG_ ADAS_Warning_Flag_11 : 22|1@0+ (1,0) [0|1] "" MHU
  SG_ ADAS_Warning_Flag_12 : 23|1@0+ (1,0) [0|1] "" MHU
  SG_ ADAS_Warning_Flag_13 : 24|1@0+ (1,0) [0|1] "" MHU
  SG_ ADAS_Warning_Flag_14 : 25|1@0+ (1,0) [0|1] "" MHU
  SG_ ADAS_Warning_Flag_15 : 26|1@0+ (1,0) [0|1] "" MHU
  SG_ ADAS_Warning_Flag_16 : 27|1@0+ (1,0) [0|1] "" MHU
  SG_ ADAS_Warning_Flag_17 : 28|1@0+ (1,0) [0|1] "" MHU
  SG_ ADAS_Warning_Flag_18 : 29|1@0+ (1,0) [0|1] "" MHU
  SG_ ADAS_Warning_Flag_19 : 30|1@0+ (1,0) [0|1] "" MHU
  SG_ ADAS_Warning_Flag_20 : 31|1@0+ (1,0) [0|1] "" MHU
  SG_ ADAS_Warning_Flag_21 : 32|1@0+ (1,0) [0|1] "" MHU
  SG_ ADAS_Warning_Flag_22 : 33|1@0+ (1,0) [0|1] "" MHU
  SG_ ADAS_Warning_Flag_23 : 34|1@0+ (1,0) [0|1] "" MHU
  SG_ ADAS_Warning_Flag_24 : 35|1@0+ (1,0) [0|1] "" MHU
  SG_ ADAS_Warning_Flag_25 : 36|1@0+ (1,0) [0|1] "" MHU
  SG_ ADAS_Warning_Flag_26 : 37|1@0+ (1,0) [0|1] "" MHU
  SG_ ADAS_Warning_Flag_27 : 38|1@0+ (1,0) [0|1] "" MHU
  SG_ ADAS_Warning_Flag_28 : 39|1@0+ (1,0) [0|1] "" MHU
  SG_ ADAS_Warning_Flag_29 : 40|1@0+ (1,0) [0|1] "" MHU
  SG_ ADAS_Warning_Flag_30 : 41|1@0+ (1,0) [0|1] "" MHU
  SG_ ADAS_Warning_Flag_31 : 42|1@0+ (1,0) [0|1] "" MHU
  SG_ ADAS_Warning_Flag_32 : 43|1@0+ (1,0) [0|1] "" MHU
  SG_ ADAS_Warning_Flag_33 : 44|1@0+ (1,0) [0|1] "" MHU
  SG_ ADAS_Warning_Flag_34 : 45|1@0+ (1,0) [0|1] "" MHU
  SG_ ADAS_Warning_Flag_35 : 46|1@0+ (1,0) [0|1] "" MHU
  SG_ ADAS_Warning_Flag_36 : 47|1@0+ (1,0) [0|1] "" MHU
  SG_ ADAS_Warning_Flag_37 : 48|1@0+ (1,0) [0|1] "" MHU
  SG_ ADAS_Warning_Flag_38 : 49|1@0+ (1,0) [0|1] "" MHU
  SG_ ADAS_Warning_Flag_39 : 50|1@0+ (1,0) [0|1] "" MHU
  SG_ ADAS_Warning_Flag_40 : 51|1@0+ (1,0) [0|1] "" MHU
  SG_ ADAS_Warning_Flag_41 : 52|1@0+ (1,0) [0|1] "" MHU
  SG_ ADAS_Warning_Flag_42 : 53|1@0+ (1,0) [0|1] "" MHU
  SG_ ADAS_Warning_Flag_43 : 54|1@0+ (1,0) [0|1] "" MHU
  SG_ ADAS_Warning_Flag_44 : 55|1@0+ (1,0) [0|1] "" MHU
  SG_ ADAS_Warning_Flag_45 : 56|1@0+ (1,0) [0|1] "" MHU
  SG_ ADAS_Warning_Flag_46 : 57|1@0+ (1,0) [0|1] "" MHU
  SG_ ADAS_Warning_Flag_47 : 58|1@0+ (1,0) [0|1] "" MHU
  SG_ ADAS_Warning_Flag_48 : 59|1@0+ (1,0) [0|1] "" MHU
  SG_ ADAS_Warning_Flag_49 : 60|1@0+ (1,0) [0|1] "" MHU
  SG_ ADAS_Warning_Flag_50 : 61|1@0+ (1,0) [0|1] "" MHU
  SG_ ADAS_Warning_Flag_51 : 62|1@0+ (1,0) [0|1] "" MHU
  SG_ ADAS_Warning_Flag_52 : 63|1@0+ (1,0) [0|1] "" MHU

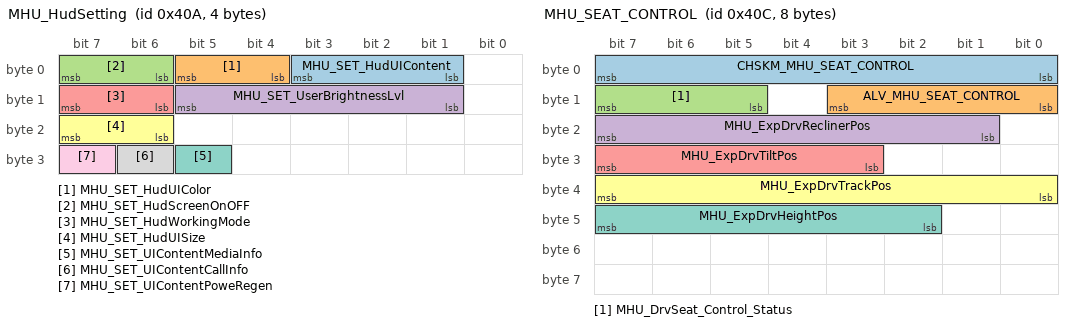
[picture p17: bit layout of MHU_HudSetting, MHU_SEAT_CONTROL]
BO_ 1034 MHU_HudSetting: 4 MHU
  SG_ MHU_SET_HudUIContent : 3|3@0+ (1,0) [0|7] "-" HUD
  SG_ MHU_SET_HudUIColor : 5|2@0+ (1,0) [0|3] "-" HUD
  SG_ MHU_SET_HudScreenOnOFF : 7|2@0+ (1,0) [0|3] "-" HUD
  SG_ MHU_SET_UserBrightnessLvl : 13|5@0+ (1,0) [0|31] "-" HUD
  SG_ MHU_SET_HudWorkingMode : 15|2@0+ (1,0) [0|3] "-" HUD
  SG_ MHU_SET_HudUISize : 23|2@0+ (1,0) [0|3] "-" HUD
  SG_ MHU_SET_UIContentMediaInfo : 29|1@0+ (1,0) [0|1] "" HUD
  SG_ MHU_SET_UIContentCallInfo : 30|1@0+ (1,0) [0|1] "" HUD
  SG_ MHU_SET_UIContentPoweRegen : 31|1@0+ (1,0) [0|1] "" HUD

BO_ 1035 MHU_Avas_Setting: 1 MHU
  SG_ MHU_SET_AvasSound : 1|2@0+ (1,0) [0|3] "-" XGW_Info

BO_ 1036 MHU_SEAT_CONTROL: 8 MHU
  SG_ CHSKM_MHU_SEAT_CONTROL : 7|8@0+ (1,0) [0|255] "" XGW_Info
  SG_ ALV_MHU_SEAT_CONTROL : 11|4@0+ (1,0) [0|14] "" XGW_Info
  SG_ MHU_DrvSeat_Control_Status : 15|3@0+ (1,0) [0|7] "-" XGW_Info
  SG_ MHU_ExpDrvReclinerPos : 23|7@0+ (1,0) [0|127] "degree" XGW_Info
  SG_ MHU_ExpDrvTiltPos : 31|5@0+ (1,0) [0|31] "mm" XGW_Info
  SG_ MHU_ExpDrvTrackPos : 39|8@0+ (1,0) [0|255] "mm" XGW_Info
  SG_ MHU_ExpDrvHeightPos : 47|6@0+ (1,0) [0|63] "mm" XGW_Info

BO_ 1037 MHU_DIGIT_SPEED: 5 MHU
  SG_ CHKSM_MHU_DIGIT_SPEED : 7|8@0+ (1,0) [0|255] "" ADAS_Info,HUD,XGW_Info
  SG_ ALV_MHU_DIGIT_SPEED : 11|4@0+ (1,0) [0|14] "" ADAS_Info,HUD,XGW_Info
  SG_ MHU_DigitSpeed : 23|9@0+ (1,0) [0|300] "km/h" ADAS_Info,HUD,XGW_Info

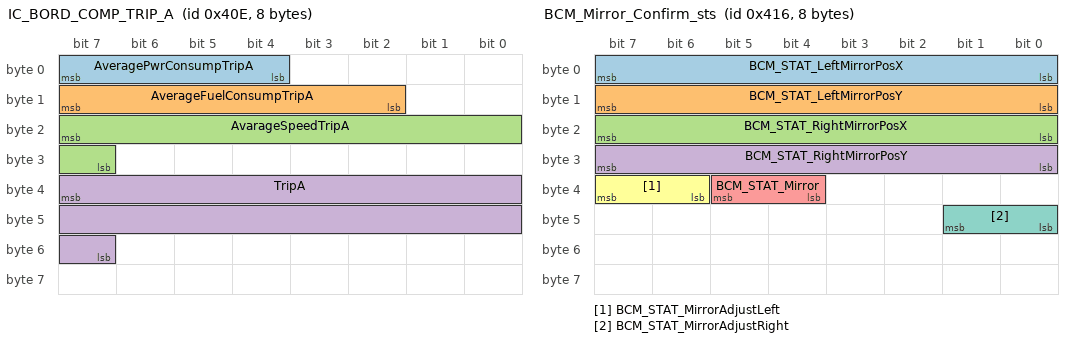
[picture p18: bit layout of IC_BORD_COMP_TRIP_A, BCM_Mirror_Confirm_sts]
BO_ 1038 IC_BORD_COMP_TRIP_A: 8 MHU
  SG_ AveragePwrConsumpTripA : 7|4@0+ (1,0) [0|10] "km/kWh" DUMMY_DEBUG,XGW_Info
  SG_ AverageFuelConsumpTripA : 15|6@0+ (1,0) [0|51] "l/100Km" DUMMY_DEBUG,XGW_Info
  SG_ AvarageSpeedTripA : 23|9@0+ (1,0) [0|300] "kmh" DUMMY_DEBUG,XGW_Info
  SG_ TripA : 39|17@0+ (0.1,0) [0|9999.9] "km" DUMMY_DEBUG,XGW_Info

BO_ 1039 IC_BORD_COMP_TRIP_B: 8 MHU
  SG_ AveragePwrConsumpTripB : 7|4@0+ (1,0) [0|10] "km/kWh" DUMMY_DEBUG,XGW_Info
  SG_ AverageFuelConsumpTripB : 15|6@0+ (1,0) [0|51] "l/100Km" DUMMY_DEBUG,XGW_Info
  SG_ AvarageSpeedTripB : 23|9@0+ (1,0) [0|300] "kmh" DUMMY_DEBUG,XGW_Info
  SG_ TripB : 39|17@0+ (0.1,0) [0|9999.9] "km" DUMMY_DEBUG,XGW_Info

BO_ 1040 IC_BORD_COMP_TRIP_Auto: 8 MHU
  SG_ AveragePwrConsumpTripAuto : 7|4@0+ (1,0) [0|10] "km/kWh" DUMMY_DEBUG,XGW_Info
  SG_ AverageFuelConsumpTripAuto : 15|6@0+ (1,0) [0|51] "l/100Km" DUMMY_DEBUG,XGW_Info
  SG_ AvarageSpeedTripAuto : 23|9@0+ (1,0) [0|300] "kmh" DUMMY_DEBUG,XGW_Info
  SG_ TripAuto : 39|17@0+ (0.1,0) [0|9999.9] "km" DUMMY_DEBUG,XGW_Info

BO_ 1046 BCM_Mirror_Confirm_sts: 8 XGW_Info
  SG_ BCM_STAT_LeftMirrorPosX : 7|8@0+ (1,-15) [-15|15] "deg" MHU
  SG_ BCM_STAT_LeftMirrorPosY : 15|8@0+ (1,-15) [-15|15] "deg" MHU
  SG_ BCM_STAT_RightMirrorPosX : 23|8@0+ (1,-15) [-15|15] "deg" MHU
  SG_ BCM_STAT_RightMirrorPosY : 31|8@0+ (1,-15) [-15|15] "deg" MHU
  SG_ BCM_STAT_Mirror : 37|2@0+ (1,0) [0|3] "" MHU
  SG_ BCM_STAT_MirrorAdjustLeft : 39|2@0+ (1,0) [0|3] "-" MHU
  SG_ BCM_STAT_MirrorAdjustRight : 41|2@0+ (1,0) [0|3] "" MHU

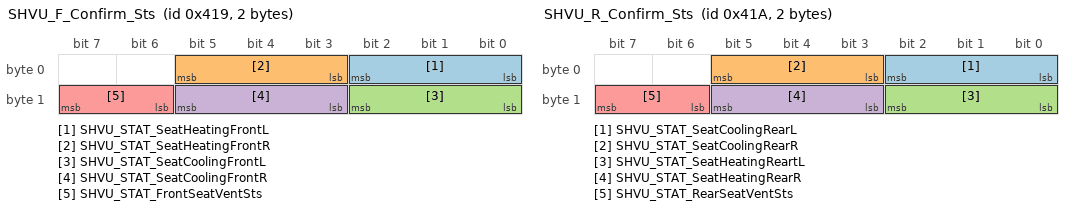
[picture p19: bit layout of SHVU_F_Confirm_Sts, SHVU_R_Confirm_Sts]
BO_ 1049 SHVU_F_Confirm_Sts: 2 XGW_Info
  SG_ SHVU_STAT_SeatHeatingFrontL : 2|3@0+ (1,0) [0|7] "-" MHU
  SG_ SHVU_STAT_SeatHeatingFrontR : 5|3@0+ (1,0) [0|7] "-" MHU
  SG_ SHVU_STAT_SeatCoolingFrontL : 10|3@0+ (1,0) [0|7] "-" MHU
  SG_ SHVU_STAT_SeatCoolingFrontR : 13|3@0+ (1,0) [0|7] "" MHU
  SG_ SHVU_STAT_FrontSeatVentSts : 15|2@0+ (1,0) [0|3] "" MHU

BO_ 1050 SHVU_R_Confirm_Sts: 2 XGW_Info
  SG_ SHVU_STAT_SeatCoolingRearL : 2|3@0+ (1,0) [0|7] "-" MHU
  SG_ SHVU_STAT_SeatCoolingRearR : 5|3@0+ (1,0) [0|7] "" MHU
  SG_ SHVU_STAT_SeatHeatingReartL : 10|3@0+ (1,0) [0|7] "" MHU
  SG_ SHVU_STAT_SeatHeatingRearR : 13|3@0+ (1,0) [0|7] "" MHU
  SG_ SHVU_STAT_RearSeatVentSts : 15|2@0+ (1,0) [0|3] "" MHU

BO_ 1052 PSM_SEAT_POSITION: 3 XGW_Info
  SG_ CHKSM_PSM_SEAT_POSITION : 7|8@0+ (1,0) [0|255] "" MHU
  SG_ AVL_PSM_SEAT_POSITION : 11|4@0+ (1,0) [0|14] "-" MHU
  SG_ PSM_Seat_track_pos_Dri : 19|2@0+ (1,0) [0|3] "" MHU
  SG_ PSM_Seat_track_posPas : 21|2@0+ (1,0) [0|3] "" MHU

BO_ 1053 BCM_Comfort_Confirm_sts: 8 XGW_Info
  SG_ BCM_STAT_AutoRearWiper : 1|2@0+ (1,0) [0|3] "-" MHU
  SG_ BCM_STAT_MirrorFoldSetting : 3|2@0+ (1,0) [0|3] "" MHU
  SG_ BCM_STAT_IMMO_KeyfobID2 : 7|3@0+ (1,0) [0|7] "" MHU
  SG_ BCM_STAT_MirrorAutoUnfold : 9|2@0+ (1,0) [0|3] "-" MHU
  SG_ BCM_STAT_MirrorReverseLink : 11|2@0+ (1,0) [0|3] "" MHU
  SG_ BCM_STAT_MirrorDefaultSTATting : 13|2@0+ (1,0) [0|3] "-" MHU
  SG_ BCM_STAT_WelcomeTriggerCondition : 15|2@0+ (1,0) [0|3] "" MHU
  SG_ BCM_STAT_FrontDomeLamp : 17|2@0+ (1,0) [0|3] "-" MHU
  SG_ BCM_STAT_FollowMeHome : 20|3@0+ (1,0) [0|7] "-" MHU
  SG_ BCM_STAT_ExteriorLight : 23|3@0+ (1,0) [0|7] "-" MHU
  SG_ BCM_STAT_RemoteLockFeedback : 26|3@0+ (1,0) [0|7] "-" MHU
  SG_ BCM_STAT_RemoteDoorUnlock : 28|2@0+ (1,0) [0|3] "" MHU
  SG_ BCM_STAT_AutoDoorUnlock : 30|2@0+ (1,0) [0|3] "" MHU
  SG_ BCM_STAT_AmbientLightBrighness : 39|7@0+ (1,0) [0|100] "%" MHU
  SG_ BCM_STAT_WiperServiceMode : 42|2@0+ (1,0) [0|3] "" MHU
  SG_ BCM_STAT_IMMO_KeyfobID : 45|2@0+ (1,0) [0|3] "" MHU
  SG_ BCM_STAT_RearHeatedWindowMirror : 47|2@0+ (1,0) [0|3] "" MHU
  SG_ BCM_STAT_AntiTheftMode : 50|3@0+ (1,0) [0|7] "-" MHU
  SG_ BCM_STAT_ClimateKeepOnSts : 53|2@0+ (1,0) [0|3] "" MHU
  SG_ BCM_STAT_FKSfeedback : 55|2@0+ (1,0) [0|3] "" MHU
  SG_ SECCAN_CmftCnfrm : 63|8@0+ (1,0) [0|255] "" MHU

CM_ BO_ 777 "ADAS IMMO Data to MHU";
CM_ BO_ 784 "CCU_R_Status";
CM_ BO_ 787 "POD StatusCharger1";
CM_ BO_ 803 "POD StatusCharger2";
CM_ BO_ 804 "HOD Heating Control";
CM_ BO_ 805 "Heating Control- Feedback";
CM_ BO_ 806 "POD StatusDCDC1";
CM_ BO_ 808 "IC RELATIVIME";
CM_ BO_ 809 "BCM_ODO";
CM_ BO_ 816 "IC_MILEAGE
";
CM_ BO_ 818  "BMS Pack information ";
CM_ SG_ 818 Checksum_0x332 "Checksum";
CM_ SG_ 818 Rolling_Counter_0x332 "Rolling Counter";
CM_ SG_ 818 BMS_PackCNom "Nominal capacity of the battery pack";
CM_ SG_ 818 BMS_PackTemp_0x332 "Pack Temperature ";
CM_ BO_ 827 "Camera Left/right lane type signals";
CM_ BO_ 833 "Camera Object 1 signals";
CM_ BO_ 835 "Camera Object 2 signals";
CM_ BO_ 838 "POD Status2";
CM_ BO_ 842 "Camera Object 3 signals";
CM_ BO_ 844 "Camera Object 4 signals";
CM_ BO_ 845 "Camera Object 5 signals";
CM_ BO_ 846 "Camera Object 6 signals";
CM_ BO_ 849 "ADAS Parking Assist";
CM_ BO_ 850 "ADAS Auto headlight high beam control and Door Open Warning";
CM_ BO_ 851 "ADAS Adaptive Cruise Control";
CM_ BO_ 852 "MHU ADAS request";
CM_ BO_ 853 "ADAS component check";
CM_ BO_ 885 "BMS Relay";
CM_ BO_ 896 "BCM vehicle identifier number";
CM_ BO_ 897 "ACM seatbelt and buckle status for seatbelt reminder";
CM_ BO_ 905 "VCU_status";
CM_ BO_ 915 "MHU_HudPositionSetting";
CM_ BO_ 919 "MHU Authentication signal";
CM_ BO_ 922 "MHU_Authentication information";
CM_ BO_ 923 "GW_BCM_Immo_MHU_Byte";
CM_ BO_ 925 "BCM hight beam position request";
CM_ BO_ 943 "MHU_HUD_BASE";
CM_ BO_ 964 "MHU HUD NAV DISP";
CM_ BO_ 965 "MHU_HUD_NAV_GuidanceCont";
CM_ BO_ 966 "MHU NAV GuidanceDist";
CM_ BO_ 992 "VCU High Voltage System Status";
CM_ BO_ 993 "VCU_HMI_Info.";
CM_ BO_ 1015 "MFS Control Button";
CM_ BO_ 1020 "XGW FOTA confirm status";
CM_ BO_ 1025 "MHU Door Setting";
CM_ BO_ 1026 "MHU Light Setting";
CM_ BO_ 1027 "MHU Driving Mode Setting";
CM_ BO_ 1028 "MHU Mirror Adjust";
CM_ BO_ 1029 "MHU Climate Setting";
CM_ BO_ 1030 "MHU Seat Vent Heat";
CM_ BO_ 1032 "MHU Comfort Setting";
CM_ BO_ 1033 "ADAS WarnMsg";
CM_ BO_ 1034 "MHU HudSetting";
CM_ BO_ 1035 "MHU Avas Setting";
CM_ BO_ 1036 "MHU_SEAT_CONTROL";
CM_ BO_ 1037 "Display Vehicle speed CAN Signal sent by MHU";
CM_ BO_ 1038 "IC BORD COMP TRIP B";
CM_ BO_ 1039 "IC BORD COMP TRIP B";
CM_ BO_ 1040 "IC_BORD_COMP_TRIP_Auto";
CM_ BO_ 1046 "BCM Mirror Confirm Sts";
CM_ BO_ 1049 "SHVU F Confirm Sts";
CM_ BO_ 1050 "SHVU R Confirm Sts";
CM_ BO_ 1052 "PSM seat position";
CM_ BO_ 1053 "BCM Comfortable Confirm status";
CM_ SG_ 777 ADAS_Immo_MHU_Byte_0 "ADAS Authentication signal byte 0 with MHU";
CM_ SG_ 777 ADAS_Immo_MHU_Byte_1 "ADAS Authentication signal byte 1 with MHU";
CM_ SG_ 777 ADAS_Immo_MHU_Byte_2 "ADAS Authentication signal byte 2 with MHU";
CM_ SG_ 777 ADAS_Immo_MHU_Byte_3 "ADAS Authentication signal byte 3 with MHU";
CM_ SG_ 777 ADAS_Immo_MHU_Byte_4 "ADAS Authentication signal byte 4 with MHU";
CM_ SG_ 777 ADAS_Immo_MHU_Byte_5 "ADAS Authentication signal byte 5 with MHU";
CM_ SG_ 777 ADAS_Immo_MHU_Byte_6 "ADAS Authentication signal byte 6 with MHU";
CM_ SG_ 777 ADAS_Immo_MHU_Byte_7 "ADAS Authentication signal byte 7 with MHU";
CM_ SG_ 784 CCUR_STAT_IonButton "Status if the ionisator is active";
CM_ SG_ 784 CCUR_STAT_Defrost "Status activation of Defrost mode";
CM_ SG_ 784 CCUR_STAT_Auto "Status activation of auto mode";
CM_ SG_ 784 CCUR_STAT_Aircondition "Aircondition status";
CM_ SG_ 784 CCUR_STAT_FlapPos "Request for flap position";
CM_ SG_ 784 CCUR_STAT_FanSpeed "Blower settings Fan Speed for climate system";
CM_ SG_ 784 CCUR_STAT_PTC_Heater "CCU status for PTC heater";
CM_ SG_ 784 CCUR_STAT_OnOff "Status On  Off button for clima";
CM_ SG_ 784 CCUR_STAT_MaxAc "Status activation of MAX AC mode";
CM_ SG_ 784 CCUR_STAT_SyncClimateZone "Status dual clima automatic";
CM_ SG_ 784 CCUR_STAT_RecircFlap "Recirculation flap status, 100% fresh air, 0% recirculation mode";
CM_ SG_ 784 CCUR_STAT_TempRear "
CCU status for temperature regulationr driver (Display Temperature)";
CM_ SG_ 787 CHSKM_POD_StatusCharger1 "Check sum";
CM_ SG_ 787 ALV_POD_StatusCharger1 "Alive counter";
CM_ SG_ 787 POD_statusOBC "OBC status";
CM_ SG_ 787 POD_OBC_Max_Current_Out "Max DC current OBC able to output";
CM_ SG_ 787 POD_iDCOut "POD measured output current on OBC output";
CM_ SG_ 787 POD_vDCOut "POD measured bus voltage at OBC output";
CM_ SG_ 803 CHSKM_POD_StatusCharger2 "Check sum";
CM_ SG_ 803 ALV_POD_StatusCharger2 "Alive counter";
CM_ SG_ 803 POD_iACInput "POD measured current on AC input";
CM_ SG_ 803 POD_vACInput "POD measured voltage on AC input";
CM_ SG_ 804 Steering_HeatingControl "Steering Heating Control";
CM_ SG_ 805 Steering_HeatingControlFdbk "Steering Heating Control Feedback";
CM_ SG_ 806 CHSKM_POD_StatusDCDC1 "Check sum";
CM_ SG_ 806 ALV_POD_StatusDCDC1 "Alive counter";
CM_ SG_ 806 POD_statusDCDC "DCDC status";
CM_ SG_ 806 POD_DCDC_Max_Current_Out "Max LV current DCDC able to output";
CM_ SG_ 808 T_SEC_COU_REL "This counter counts the seconds synchronously to the system clock.";
CM_ SG_ 808 T_DAY_COU_ABSL "Relative time
";
CM_ SG_ 809 CRC_BCM_ODO "Checksum";
CM_ SG_ 809 ALIV_BCM_ODO "Alive counter";
CM_ SG_ 809 Odometer_BCM "Odometer infomation for IPC.";
CM_ SG_ 809 SECCAN_BCM_ODO "Seed generated from Secure CAN algorithm";
CM_ SG_ 816 MILE_KM "Mileage information
";
CM_ SG_ 816 FLLV_FUTA "The fuel level of  tank. 255 value invalid";
CM_ SG_ 816 RNG "Calculated range of IPC";
CM_ SG_ 816 ST_FLLV_FUTA_SPAR "State of the tank reserve indicator 

";
CM_ SG_ 827 CHKSM_CameraLane "Checksum";
CM_ SG_ 827 ALV_ADAS_Cameralane "Alive Counter";
CM_ SG_ 827 Camera_R1_Line_Type "L1 right line type";
CM_ SG_ 827 Camera_L1_Line_Type "ICON Feedback Request for LKA/ELK function";
CM_ SG_ 827 R0_ExistProbability "Host Lane right line exist probability ";
CM_ SG_ 827 L0_ExistProbability "Host Lane left line exist probability";
CM_ SG_ 827 L1_ExistProbability "far right line exist probability";
CM_ SG_ 827 R1_ExistProbability "far right line exist probability ";
CM_ SG_ 827 SECCAN_CameraLane "Secret portion from Secure CAN algorithm";
CM_ SG_ 833 SECCAN_Cam_OBJ_1 "Secret portion from Secure CAN algorithm";
CM_ SG_ 833 ADAS_OBJ01_Class "The class of object 01";
CM_ SG_ 833 ADAS_OBJ01_LgtDis "Longitudinal distance of object 01";
CM_ SG_ 833 ADAS_OBJ01_ID "The ID of object 01";
CM_ SG_ 833 ADAS_OBJ01_LatDis "Lateral distance of object 01(left minus right positive)";
CM_ SG_ 833 ADAS_OBJ01_Lane "Road information of Object 01";
CM_ SG_ 835 SECCAN_Cam_OBJ_2 "Secret portion from Secure CAN algorithm";
CM_ SG_ 835 ADAS_OBJ02_Class "The class of object 02";
CM_ SG_ 835 ADAS_OBJ02_LgtDis "Longitudinal distance of object 02";
CM_ SG_ 835 ADAS_OBJ02_ID "The ID of object 02";
CM_ SG_ 835 ADAS_OBJ02_LatDis "Lateral distance of object 02(left minus right positive)";
CM_ SG_ 835 ADAS_OBJ02_Lane "Road information of Object 02";
CM_ SG_ 838 CHSKM_POD_StatusDCDC2 "Check sum";
CM_ SG_ 838 ALV_POD_StatusDCDC2 "Alive counter";
CM_ SG_ 838 POD_vDCInput "POD measured DC bus voltage at DCDC input";
CM_ SG_ 838 POD_iDCDCOutput "POD reported 12V current";
CM_ SG_ 838 POD_vDCDCOutput "POD reported 12V voltage";
CM_ SG_ 842 SECCAN_Cam_OBJ_3 "Secret portion from Secure CAN algorithm";
CM_ SG_ 842 ADAS_OBJ03_Class "The class of object 03";
CM_ SG_ 842 ADAS_OBJ03_LgtDis "Longitudinal distance of object 03";
CM_ SG_ 842 ADAS_OBJ03_ID "The ID of object 03";
CM_ SG_ 842 ADAS_OBJ03_LatDis "Lateral distance of object 03(left minus right positive)";
CM_ SG_ 842 ADAS_OBJ03_Lane "Road information of Object 03";
CM_ SG_ 844 SECCAN_Cam_OBJ_4 "Secret portion from Secure CAN algorithm";
CM_ SG_ 844 ADAS_OBJ04_Class "The class of object 04";
CM_ SG_ 844 ADAS_OBJ04_LgtDis "Longitudinal distance of object 04";
CM_ SG_ 844 ADAS_OBJ04_ID "The ID of object 04";
CM_ SG_ 844 ADAS_OBJ04_LatDis "Lateral distance of object 04(left minus right positive)";
CM_ SG_ 844 ADAS_OBJ04_Lane "Road information of Object 04";
CM_ SG_ 845 SECCAN_Cam_OBJ_5 "Secret portion from Secure CAN algorithm";
CM_ SG_ 845 ADAS_OBJ05_Class "The class of object 05";
CM_ SG_ 845 ADAS_OBJ05_LgtDis "Longitudinal distance of object 05";
CM_ SG_ 845 ADAS_OBJ05_ID "The ID of object 05";
CM_ SG_ 845 ADAS_OBJ05_LatDis "Lateral distance of object 05(left minus right positive)";
CM_ SG_ 845 ADAS_OBJ05_Lane "Road information of Object 05";
CM_ SG_ 846 SECCAN_Cam_OBJ_6 "Secret portion from Secure CAN algorithm";
CM_ SG_ 846 ADAS_OBJ06_Class "The class of object 06";
CM_ SG_ 846 ADAS_OBJ06_LgtDis "Longitudinal distance of object 06";
CM_ SG_ 846 ADAS_OBJ06_ID "The ID of object 06";
CM_ SG_ 846 ADAS_OBJ06_LatDis "Lateral distance of object 06(left minus right positive)";
CM_ SG_ 846 ADAS_OBJ06_Lane "Road information of Object 06";
CM_ SG_ 849 CHKSM_ADAS_PA "Checksum";
CM_ SG_ 849 ALV_ADAS_PA "Alive Counter";
CM_ SG_ 849 ADAS_PA_AutoOn_Feed "Parking assist On Off Feedback";
CM_ SG_ 849 ADAS_PA_AlertFRI "Front-Right-Inner Parking Sensors Warnning Display";
CM_ SG_ 849 ADAS_PA_AlertFLI "Front-Left-Inner Parking Sensors Warnning Display";
CM_ SG_ 849 ADAS_PA_AlertFLO "Front-Left-Outer Parking Sensors Warnning Display";
CM_ SG_ 849 ADAS_PA_AlertRLO "Rear-Left-Outer Parking Sensors Warnning Display";
CM_ SG_ 849 ADAS_PA_AlertRLI "Rear-Left-Inner Parking Sensors Warnning Display";
CM_ SG_ 849 ADAS_PA_AlertFRO "Front-Right-Outer Parking Sensors Warnning Display";
CM_ SG_ 849 ADAS_PA_AlertRRO "Rear-Right-Outer Parking Sensors Warnning Display";
CM_ SG_ 849 ADAS_PA_AlertRRI "Rear-Right-Inner Parking Sensors Warnning Display";
CM_ SG_ 849 ADAS_PA_state "ADAS Parking assist State (Include. On Off Feedback signal)";
CM_ SG_ 850 CHKSM_ADAS_AHB_DOW "Checksum";
CM_ SG_ 850 ALV_ADAS_AHB_DOW "Alive Counter";
CM_ SG_ 850 ADAS_AHB_sens_Feed "Auto headlight high beam sensitivity Feedback";
CM_ SG_ 850 ADAS_AHB_Mode_Feed "Auto headlight high beam On off Feedback";
CM_ SG_ 850 ADAS_AHB_check "Auto headlight high beam control Check";
CM_ SG_ 850 ADAS_AHB_state "Auto headlight high beam control State";
CM_ SG_ 850 ADAS_DOW_WarnRight "Right Door Open Warning";
CM_ SG_ 850 ADAS_DOW_SndWarn "Door Open Sound Warning en disable";
CM_ SG_ 850 ADAS_DOW_state "Door Open Warning State";
CM_ SG_ 850 ADAS_DOW_check "Door Opening Warning Check";
CM_ SG_ 850 ADAS_DOW_WarnLeft "Left Door Open Warning";
CM_ SG_ 850 ADAS_DOW_Mode_Feed "Door Open Warning Mode select Feedback";
CM_ SG_ 850 ADAS_AHB_RBPos "Right High Beam Position Request Signal";
CM_ SG_ 850 ADAS_AHB_LBPos "Left High Beam Position Request Signal";
CM_ SG_ 851 CHKSM_ADAS_ACC "Checksum";
CM_ SG_ 851 ALV_ADAS_ACC "Alive Counter";
CM_ SG_ 851 ADAS_ACC_ObjDetec "Lead Object Detected or not";
CM_ SG_ 851 ADAS_ISA_check "Inteligent Speed adaptation Check";
CM_ SG_ 851 ADAS_ISA_Mode_SW_Feed "Feedback of ISA On off(From Steering wheel button)";
CM_ SG_ 851 ADAS_TagSpeed_ICON_Feed "ICON Feedback Request for Target Speed Feedback Display";
CM_ SG_ 851 ADAS_ISA_PopUp_Feed "PopUP Messaging for ISA function";
CM_ SG_ 851 ADAS_ISA_Btn_Feed "Feedback of ISA On Off Button";
CM_ SG_ 851 ADAS_ACC_DistSet_upper_Feed "Feedback of Object Vehicle Gap Distance Adjustment (Increase Button)";
CM_ SG_ 851 ADAS_ACC_TimeGapSet "Adaptive Cruise Control time gap setting";
CM_ SG_ 851 ADAS_ACC_State "The signal indicates the status of the Adaptive Cruise Control function";
CM_ SG_ 851 ADAS_ACC_TagSpeed "Adaptive Cruise Control speed setting";
CM_ SG_ 851 ADAS_ACC_PopUp_Feed "PopUP Messaging for ACC function";
CM_ SG_ 851 ADAS_ACC_check "Adaptive Cruise Control Check";
CM_ SG_ 851 ADAS_ISA_ICON_Feed "ICON Feedback Request for ISA function";
CM_ SG_ 851 ADAS_ACC_DistSet_lower_Feed "Feedback of Object Vehicle Gap Distance Adjustment ( Reduction Button)";
CM_ SG_ 851 ADAS_ACC_SpdSet_upper_Feed "Feedback of Subject Vehicle Speed Setting (Increase Button)";
CM_ SG_ 851 ADAS_ACC_SpdSet_lower_Feed "Feedback of Subject Vehicle Speed Setting ( Reduction Button)";
CM_ SG_ 851 ADAS_ACC_On_Feed "Feedback of ACC On Off Button";
CM_ SG_ 851 ADAS_ACC_Set_Feed "Feedback of ACC Set Button";
CM_ SG_ 851 ADAS_ACC_CnlBtn_Feed "Feedback of ACC Cancel Button";
CM_ SG_ 851 ADAS_ACC_Res_Feed "Feedback of ACC Resume Button";
CM_ SG_ 851 ADAS_ACC_ICON_Feed "ICON Feedback Request for ACC function";
CM_ SG_ 851 ADAS_ISA_Status "The signal indicates the status of the ISA function";
CM_ SG_ 852 MHU_FCW_Mode "FCW ABE mode select";
CM_ SG_ 852 MHU_FCW_sens "FCW Sensitivity";
CM_ SG_ 852 MHU_AEB_Mode "AEB Confirmation";
CM_ SG_ 852 MHU_RAEB_Mode "RAEB mode select";
CM_ SG_ 852 MHU_LA_sens "LA Sensitivity (Early   Normal   Late)";
CM_ SG_ 852 MHU_LA_AudWarning "Setting Audible warning for LA On off";
CM_ SG_ 852 MHU_BSD_On "BSD On off";
CM_ SG_ 852 MHU_ALC_ON "Turn ALCA on/off";
CM_ SG_ 852 MHU_BSD_AudWarning "Setting Audible warning for BSD On off";
CM_ SG_ 852 MHU_RCTA_On "RCTA On off";
CM_ SG_ 852 MHU_RCTA_sens "RCTA Sensitivity (Early   Normal   Late)";
CM_ SG_ 852 MHU_PA_On "PA On off";
CM_ SG_ 852 MHU_AHB_On "AHB On off";
CM_ SG_ 852 MHU_IA_Mode "IA mode select";
CM_ SG_ 852 MHU_TSR_Mode "TSR Mode selection";
CM_ SG_ 852 MHU_DOW_Mode "Door Open Warning Mode select";
CM_ SG_ 852 MHU_AHB_sens "AHB Sensitivity (Early   Normal   Late)";
CM_ SG_ 852 MHU_LA_Mode "Lane Assistance Mode select";
CM_ SG_ 852 MHU_SET_TSR_AudWarn "TSR Audible Warning On Off";
CM_ SG_ 852 MHU_SET_TSR_SLAert "TSR Speed Limit Alert select";
CM_ SG_ 853 CHKSM_ADAS_CMP_CHECK "Checksum";
CM_ SG_ 853 ALV_ADAS_CMP_CHECK "Alive Counter";
CM_ SG_ 853 ADAS_PAUSS_FaultFLO "This signal shows the position of Fault Ultrasonic sensor for Parking Assist";
CM_ SG_ 853 ADAS_PAUSS_FaultFLI "This signal shows the position of Fault Ultrasonic sensor for Parking Assist";
CM_ SG_ 853 ADAS_PAUSS_check "Ultrasonic sensor for Parking Assist check";
CM_ SG_ 853 ADAS_PAUSS_FaultRLO "This signal shows the position of Fault Ultrasonic sensor for Parking Assist";
CM_ SG_ 853 ADAS_PAUSS_FaultFRI "This signal shows the position of Fault Ultrasonic sensor for Parking Assist";
CM_ SG_ 853 ADAS_FPA_check "Front Parking Assist Check";
CM_ SG_ 853 ADAS_PAUSS_FaultRLI "This signal shows the position of Fault Ultrasonic sensor for Parking Assist";
CM_ SG_ 853 ADAS_PAUSS_FaultRRO "This signal shows the position of Fault Ultrasonic sensor for Parking Assist";
CM_ SG_ 853 ADAS_PAUSS_FaultRRI "This signal shows the position of Fault Ultrasonic sensor for Parking Assist";
CM_ SG_ 853 ADAS_RPA_check "Rear Parking Assist Check";
CM_ SG_ 853 ADAS_PAUSS_FaultFRO "This signal shows the position of Fault Ultrasonic sensor for Parking Assist";
CM_ SG_ 880 CRC_MHU_SBR_Status "Checksum";
CM_ SG_ 880 ALV_MHU_SBR_Status "Alive Counter";
CM_ SG_ 880 SBR_STAT_Chime "Status of SBR Chime";
CM_ SG_ 880 SBR_STAT_Telltale "Status of SBR telltale";
CM_ SG_ 880 SBR_STAT_Active "Status of Seatbelt reminder";
CM_ SG_ 885 Checksum_0x375 "Checksum";
CM_ SG_ 885 Rolling_Counter_0x375 "Rolling Counter";
CM_ SG_ 885 BMS_PreChgRelay_ERR "Precahrge relay is not working properly ";
CM_ SG_ 885 BMS_TotalNegRelay_ERR "Main Negative Relay Error ";
CM_ SG_ 885 BMS_MainPosRelay_ERR "Main Position Relay Error ";
CM_ SG_ 885 BMS_MainPosRelay_STS "Main Positive Relay Status ";
CM_ SG_ 885 BMS_PreChgRelay_STS "PreCharge Relay Status ";
CM_ SG_ 885 BMS_TotalNegRelay_STS "Main Negative Relay Status ";
CM_ SG_ 896 VIN_Byte1 "This signal contains the seventh last digit of the chassis number. (The individual digits are encoded in ASCII characters.)
Bit 0: LSB, Bit 7: MSB";
CM_ SG_ 896 VIN_Byte2 "This signal contains the sixth last digit of the chassis number. (The individual digits are encoded in ASCII characters.)
Bit 0: LSB, Bit 7: MSB";
CM_ SG_ 896 VIN_Byte3 "This signal contains the fifth last digit of the chassis number. (The individual digits are encoded in ASCII characters.)
Bit 0: LSB, Bit 7: MSB";
CM_ SG_ 896 VIN_Byte4 "This signal contains the fourth last digit of the chassis number. (The individual digits are encoded in ASCII characters.)
Bit 0: LSB, Bit 7: MSB";
CM_ SG_ 896 VIN_Byte5 "This signal contains the third last digit of the chassis number. (The individual digits are encoded in ASCII characters.)
Bit 0: LSB, Bit 7: MSB";
CM_ SG_ 896 VIN_Byte6 "This signal contains the penultimate digit of the chassis number. (The individual digits are encoded in ASCII characters.)
Bit 0: LSB, Bit 7: MSB";
CM_ SG_ 896 VIN_Byte7 "This signal contains the last digit of the chassis number. (The individual digits are encoded in ASCII characters.)
Bit 0: LSB, Bit 7: MSB";
CM_ SG_ 897 CHKSM_ACM_SEAT_OCCUPATION "Checksum";
CM_ SG_ 897 ALV_ACM_SEAT_OCCUPATION "Alive Counter";
CM_ SG_ 897 ACM_Seat_Occupancy_Passenger "Signal to indicate status of occupancy";
CM_ SG_ 897 ACM_Seat_Occupancy_2nd_Row_Dri "Signal to indicate status of occupancy";
CM_ SG_ 897 ACM_Seat_Occupancy_2nd_Row_Pas "Signal to indicate status of occupancy";
CM_ SG_ 897 ACM_Seat_Occupancy_2nd_Row_Mid "Signal to indicate status of occupancy";
CM_ SG_ 897 ACM_Seat_Belt_Status_Passenger "Seatbelt status for seatbelt reminder function";
CM_ SG_ 897 ACM_Seat_Belt_Status_Driver "Seatbelt status for seatbelt reminder function";
CM_ SG_ 897 ACM_Seat_Belt_Status_2nd_Row_Dri "Seatbelt status for seatbelt reminder function";
CM_ SG_ 897 ACM_Seat_Belt_Status_2nd_Row_Mid "Seatbelt status for seatbelt reminder function";
CM_ SG_ 897 ACM_Seat_Belt_Status_2nd_Row_Pas "Seatbelt status for seatbelt reminder function";
CM_ SG_ 905 VCU_IMMO_Sts "IMMO status";
CM_ SG_ 905 SECCAN_VCU_IMMO_Sts "Seed generated from Secure CAN algorithm
";
CM_ SG_ 915 MHU_SET_HudRotateLvl "Set Rotate angle";
CM_ SG_ 915 MHU_SET_HudHeightLvl "Set height position of HUD Image in Windshield";
CM_ SG_ 919 MHU_Immo_ADAS_Byte_0 "MHU Authentication signal byte 0";
CM_ SG_ 919 MHU_Immo_ADAS_Byte_1 "MHU Authentication signal byte 1";
CM_ SG_ 919 MHU_Immo_ADAS_Byte_2 "MHU Authentication signal byte 2";
CM_ SG_ 919 MHU_Immo_ADAS_Byte_3 "MHU Authentication signal byte 3";
CM_ SG_ 919 MHU_Immo_ADAS_Byte_4 "MHU Authentication signal byte 4";
CM_ SG_ 919 MHU_Immo_ADAS_Byte_5 "MHU Authentication signal byte 5";
CM_ SG_ 919 MHU_Immo_ADAS_Byte_6 "MHU Authentication signal byte 6";
CM_ SG_ 919 MHU_Immo_ADAS_Byte_7 "MHU Authentication signal byte 7";
CM_ SG_ 922 MHU_Immo_Byte_0 "MHU Authentication signal byte 0";
CM_ SG_ 922 MHU_Immo_Byte_1 "MHU Authentication signal byte 1";
CM_ SG_ 922 MHU_Immo_Byte_2 "MHU Authentication signal byte 2";
CM_ SG_ 922 MHU_Immo_Byte_3 "MHU Authentication signal byte 3";
CM_ SG_ 922 MHU_Immo_Byte_4 "MHU Authentication signal byte 4";
CM_ SG_ 922 MHU_Immo_Byte_5 "MHU Authentication signal byte 5";
CM_ SG_ 922 MHU_Immo_Byte_6 "MHU Authentication signal byte 6";
CM_ SG_ 922 MHU_Immo_Byte_7 "MHU Authentication signal byte 7";
CM_ SG_ 923 BCM_Immo_MHU_Byte_0 "BCM Authentication signal byte 0 with MHU";
CM_ SG_ 923 BCM_Immo_MHU_Byte_1 "BCM Authentication signal byte 1 with MHU";
CM_ SG_ 923 BCM_Immo_MHU_Byte_2 "BCM Authentication signal byte 2 with MHU";
CM_ SG_ 923 BCM_Immo_MHU_Byte_3 "BCM Authentication signal byte 3 with MHU";
CM_ SG_ 923 BCM_Immo_MHU_Byte_4 "BCM Authentication signal byte 4 with MHU";
CM_ SG_ 923 BCM_Immo_MHU_Byte_5 "BCM Authentication signal byte 5 with MHU";
CM_ SG_ 923 BCM_Immo_MHU_Byte_6 "BCM Authentication signal byte 6 with MHU";
CM_ SG_ 923 BCM_Immo_MHU_Byte_7 "BCM Authentication signal byte 7 with MHU";
CM_ SG_ 925 BCM_AHB_Override "Automatic High Beam Override by Driver using Stalk lever";
CM_ SG_ 943 MHU_UTF8Character_Byte1 "UTF8 Character byte 1";
CM_ SG_ 943 MHU_UTF8Character_Byte2 "UTF8 Character byte 2";
CM_ SG_ 943 MHU_UTF8Character_Byte3 "UTF8 Character byte 3";
CM_ SG_ 943 MHU_UTF8Character_Byte4 "UTF8 Character byte 4";
CM_ SG_ 943 MHU_UTF8Character_Byte5 "UTF8 Character byte 5";
CM_ SG_ 943 MHU_UTF8Character_Byte6 "UTF8 Character byte 6";
CM_ SG_ 943 MHU_IPC_ID "dIDBribe which message will be send; 0x4 0x5 in Unicode logical value; If value 4 is used there shall be songname Album and artist send from MHU divide value 1 3 with: 0x03(hex)";
CM_ SG_ 943 MHU_TotalMessages "Total number of messages.";
CM_ SG_ 943 MHU_MessageNumber "Current number of Messages; start with 1";
CM_ SG_ 964 MHU_Nav_State "Navigation state";
CM_ SG_ 964 MHU_NavSource "the actived Source provide Navigation for vehicle";
CM_ SG_ 964 MHU_Nav_DistanceToNextTurn "Value of Distance to next Turn";
CM_ SG_ 964 MHU_Nav_DistanceToNextTurnUnits "Units for Distance to next Turn";
CM_ SG_ 964 MHU_Nav_TBT_Icon "Turn by Turn Icon";
CM_ SG_ 964 MHU_Nav_ImageChannel_Ready "Image channel is ready to start streaming Nav image from MHU side";
CM_ SG_ 964 MHU_Nav_Language "The navigation engine langue";
CM_ SG_ 964 SECCAN_NAV_DISP "Seed generated from Secure CAN algorithm";
CM_ SG_ 965 MHU_NavGuidance_TotalMsg "Total message package, set value as 0 if want to clear Navigation text";
CM_ SG_ 965 MHU_NavGuidance_MsgNum "Message order, start from 1";
CM_ SG_ 965 MHU_NavGuidance_UTF8_Byte1 "Navigation content by UTF-8 byte 1";
CM_ SG_ 965 MHU_NavGuidance_UTF8_Byte2 "Navigation content by UTF-8 byte 2";
CM_ SG_ 965 MHU_NavGuidance_UTF8_Byte3 "Navigation content by UTF-8 byte 3";
CM_ SG_ 965 MHU_NavGuidance_UTF8_Byte4 "Navigation content by UTF-8 byte 4";
CM_ SG_ 965 MHU_NavGuidance_UTF8_Byte5 "Navigation content by UTF-8 byte 5";
CM_ SG_ 965 MHU_NavGuidance_UTF8_Byte6 "Navigation content by UTF-8 byte 6";
CM_ SG_ 966 MHU_NavDist_MsgNum "Message order, start from 1";
CM_ SG_ 966 MHU_NavDist_TotalMsg "Total message package, set value as 0 if want to clear Navigation text";
CM_ SG_ 966 MHU_NavDist_UTF8_Byte1 "Navigation content by UTF-8 byte 1";
CM_ SG_ 966 MHU_NavDist_UTF8_Byte2 "Navigation content by UTF-8 byte 2";
CM_ SG_ 966 MHU_NavDist_UTF8_Byte3 "Navigation content by UTF-8 byte 3";
CM_ SG_ 966 MHU_NavDist_UTF8_Byte4 "Navigation content by UTF-8 byte 4";
CM_ SG_ 966 MHU_NavDist_UTF8_Byte5 "Navigation content by UTF-8 byte 5";
CM_ SG_ 966 MHU_NavDist_UTF8_Byte6 "Navigation content by UTF-8 byte 6";
CM_ SG_ 992 CRC_VCU_HVsystem_status "Checksum";
CM_ SG_ 992 ALIV_VCU_HVsystem_status "Alive counter";
CM_ SG_ 992 VCU_RunningRange "Estimated running range ( at present )";
CM_ SG_ 992 VCU_RunningRange_chrg_estSts "Status of estimation running range after charged by current charging condition ( max chg.current, chg.time, ?)";
CM_ SG_ 992 VCU_RunningRange_charged "Estimated running range after charged by current charging condition ( max chg.current, chg.time, ?)";
CM_ SG_ 992 VCU_HVbatSoc_charged "Estimated HVBattery SOC by current charging condition ( max chg.current, chg.time, ?)";
CM_ SG_ 992 VCU_HVbatSoc_charged_estStatus "Status of SOC Estimation by current charging condition ( max chg.current, chg.time, ?)";
CM_ SG_ 993 CRC_VCU_HMI_Info "Checksum";
CM_ SG_ 993 ALIV_VCU_HMI_Info "Alive counter";
CM_ SG_ 993 VCU_MHU_Ack_ChgSche_stt "Status Enabled/ Disabled of Schedule Charging acknowledged by VCU base on request from MHU 0x403 MHU_ChargeScheduleSet.";
CM_ SG_ 993 VCU_MHU_Ack_TargetSOC "Target SOC acknowledged by VCU base on request from MHU
";
CM_ SG_ 993 VCU_ValetMode_sts "Status indicate valet mode is effected to VCU";
CM_ SG_ 993 VCU_ValetMode_MaxSpeedSts "Max speed setting of Valet mode";
CM_ SG_ 993 SECCAN_VCU_HMI_Info "Seed generated from Secure CAN algorithm";
CM_ SG_ 1015 CHSKM_MFS_Control_Button "Checksum";
CM_ SG_ 1015 ALV_MFS_Control_Button "Alive Counter";
CM_ SG_ 1015 MFS_VoiceRecognitionOn_Off "VoiceRecognition control";
CM_ SG_ 1015 MFS_ISAControl "ISA Control";
CM_ SG_ 1015 MFS_CruiseSpeedIncrease "Cruise Speed Increase";
CM_ SG_ 1015 MFS_TelephoneCall_EndCall "Telephone Call functionality control  ";
CM_ SG_ 1015 MFS_LKAControl "Line Keep Assistance/Line Departure warning Control";
CM_ SG_ 1015 MFS_CruiseGapIncrease "Cruise Gap Increase";
CM_ SG_ 1015 MFS_CruiseOn_Off "Cruise control On/Off";
CM_ SG_ 1015 MFS_CruiseGapDecrease "Cruise Gap Decrease";
CM_ SG_ 1015 MFS_CAN_RESControl "From standy, M1 and M2 to be cancelled
From being cancelled, M1 or M2 to be resume to it previous state
";
CM_ SG_ 1015 MFS_CruiseSpeedDecrease "Cruise Speed Decrease";
CM_ SG_ 1015 MFS_M2Control "Auto Steering and Speed Activation";
CM_ SG_ 1015 MFS_SourseControl "Resourse Control";
CM_ SG_ 1015 MFS_UpControl "Up Control";
CM_ SG_ 1015 MFS_DownControl "Down Control";
CM_ SG_ 1015 MFS_LeftControl "Left Control";
CM_ SG_ 1015 MFS_Failure "Multi-Funtion Switch Failure";
CM_ SG_ 1015 MFS_RightControl "Right Control";
CM_ SG_ 1015 MFS_OK_Control "OK Control";
CM_ SG_ 1020 CRC_XGW_FOTA_StsConfirm "FOTA global status message checksum";
CM_ SG_ 1020 ALIV_XGW_FOTA_StsConfirm "FOTA global status message alive counter";
CM_ SG_ 1020 XGW_FOTA_StateConfirm "XGW FOTA global status confirmation";
CM_ SG_ 1020 XGW_FOTA_Error_Code " FOTA Error Code
Bit 5 : IgnState error = 1
Bit 4 : OBD port in active = 1
Bit 3 : Request state error = 1
Bit 2 : 0
Bit 1 : SysVoltage error = 1
Bit 0 : VehSpd error = 1
";
CM_ SG_ 1025 MHU_SET_SunroofGlassLevel "Adjust opening level of sunroof glass";
CM_ SG_ 1025 MHU_SET_BonnetState "Open Bonet latch";
CM_ SG_ 1025 MHU_SET_TrunkState "Open and close trunk tailgate";
CM_ SG_ 1025 MHU_SET_SunroofShaderLevel "Adjust opening level of sunroof shader";
CM_ SG_ 1025 MHU_SET_DoorSpeedLock "Setting Door speed lock mode";
CM_ SG_ 1025 MHU_SET_WelcomeTriggerCondition "Setting Welcome trigger condition";
CM_ SG_ 1025 MHU_SET_AutoSunroof "Setting Auto sunroof mode ON OFF follow Rain sensor";
CM_ SG_ 1025 MHU_SET_RemoteDoorUnlock "Setting which door will be unlocked when car unlock";
CM_ SG_ 1025 MHU_SET_RemoteLockFeedback "Setting remote car lock feedback mechanism";
CM_ SG_ 1025 MHU_SET_FootkickSensor "On Off Footkick sensor to open Trunk latch";
CM_ SG_ 1025 MHU_SET_AutoUnlockDoor "Setting auto unlock door mode Park Engine off Manual";
CM_ SG_ 1025 MHU_SET_RemoteUnlockFeedback "Setting remote car unlock feedback mechanism";
CM_ SG_ 1025 MHU_SET_Childlock "Softbutton for ON/OFF of childlock";
CM_ SG_ 1025 MHU_SET_SunroofInitialize "Initialise command to sunroof to manual open close when face antipinch";
CM_ SG_ 1026 MHU_SET_DayTimeRunningLight "On Off Day Time Running Light";
CM_ SG_ 1026 MHU_SET_RearFogLight "On/Off Rear Fog Light";
CM_ SG_ 1026 MHU_SET_FrontFogLight "On/Off Front Fog Light";
CM_ SG_ 1026 MHU_SET_WelcomeDimmingHeadlight "On/Off Welcome headlight dimming";
CM_ SG_ 1026 MHU_SET_AmbientLightBrighness "Change Ambient light brighness percent";
CM_ SG_ 1026 MHU_SET_FootwellLightMode "Change Footwell Light mode";
CM_ SG_ 1026 MHU_SET_ExteriorLight "Change Exterior light mode";
CM_ SG_ 1026 MHU_SET_TRWarningSignals "Turn on/off BCM Thermal runaway warning signals";
CM_ SG_ 1026 MHU_SET_FrontDomeLamp "Setting On/Off/Auto Front Dome Lamp";
CM_ SG_ 1026 MHU_SET_SwitchLightBrightness "Change Brighness level of Switch illumination";
CM_ SG_ 1026 MHU_SET_FollowMeHome "Change follow me home headlamp mode and delay";
CM_ SG_ 1026 MHU_SET_ADB_AHB "On/off ADB/AHB function, ADB in ECE version, AHB in SAE version
";
CM_ SG_ 1026 MHU_SET_WelcomeAnimation "selection of different welcome/goodbye animations";
CM_ SG_ 1026 MHU_SET_ChargingAnimation "De-/Activation of charging animation";
CM_ SG_ 1026 MHU_SET_Auto_Leveling "On/Off Auto-Leveling function";
CM_ SG_ 1027 CHKSM_MHU_EVSetting "Checksum for EV setting";
CM_ SG_ 1027 ALV_MHU_EVSetting "Alive Counter for EV Setting";
CM_ SG_ 1027 MHU_VCU_CreepDisable_stt "Request for VCU to disable creep function";
CM_ SG_ 1027 MHU_BrakeRegenMode "Brake Regen Style";
CM_ SG_ 1027 MHU_ChargeSetTargetSOC "Request for VCU to set target HV SOC";
CM_ SG_ 1027 MHU_ChargeScheduleSet "Request for VCU to enable/disable Charging Scheduling";
CM_ SG_ 1027 MHU_ChargingRequest "Request for VCU to ON/OFF Charging when schedule is reached";
CM_ SG_ 1027 MHU_ChgPort_Open_req "Request to open charging port(release latch)";
CM_ SG_ 1027 MHU_SET_DrivingModeSwitch "Change vehicle driving mode";
CM_ SG_ 1027 MHU_ValetMode_Activation "Activate Valet mode from MHU";
CM_ SG_ 1027 MHU_ValetMode_MaxSpeed "Setting of maximum allowable in valet mode";
CM_ SG_ 1027 MHU_ChargingCurrentLimit "Request VCU the max charging current at the rush hour - Apply for AC charging only at home";
CM_ SG_ 1028 MHU_SET_LeftMirrorPosX "Set left mirror left right position";
CM_ SG_ 1028 MHU_SET_LeftMirrorPosY "Set left mirror up down position";
CM_ SG_ 1028 MHU_SET_RightMirrorPosX "Set right mirror left/right position";
CM_ SG_ 1028 MHU_SET_RightMirrorPosY "Set right mirror up/down position";
CM_ SG_ 1028 MHU_SET_MirrorAdjustLeft "Enter setting Mirror position mode";
CM_ SG_ 1028 MHU_SET_MirrorAdjustRight "Enter setting Mirror position mode";
CM_ SG_ 1028 MHU_SET_MirrorManual "Manual Fold/Unfold";
CM_ SG_ 1028 SECCAN_MirrorAdj "Seed generated from Secure CAN algorithm";
CM_ SG_ 1029 MHU_SET_CCUF_AirCondition "On Off Air Condition";
CM_ SG_ 1029 MHU_SET_CCUF_AutoAC "On Off Auto Air Condition";
CM_ SG_ 1029 MHU_SET_CCUF_MaxAc "On Off Max Air Condition for 2 zone";
CM_ SG_ 1029 MHU_SET_CCUF_FanSpeed "Adjust Fan speed with 6 level";
CM_ SG_ 1029 MHU_SET_CCUF_Recirculation "Change recirculation mode inside, ouside, auto";
CM_ SG_ 1029 MHU_SET_CCUF_Ion "On Off Air ionizer";
CM_ SG_ 1029 MHU_SET_CCUF_FlapPosition "Change Flap position Face, Feet, Front defrost";
CM_ SG_ 1029 MHU_SET_CCUF_SyncClimateZone "On Off sync temperature between zone";
CM_ SG_ 1029 MHU_SET_CCUF_TempDriver "Change Driver zone temperature";
CM_ SG_ 1029 MHU_SET_CCUF_TempPassenger "Change Passenger zone temperature";
CM_ SG_ 1029 MHU_SET_CCUF_FrontDefrost "Change Flap poition to Front Defrost";
CM_ SG_ 1030 MHU_SET_SeatHeatingFrontL "Change seat heating with 3 level";
CM_ SG_ 1030 MHU_SET_SeatHeatingFrontR "Change seat heating with 3 level";
CM_ SG_ 1030 MHU_SET_SeatHeatingReartL "Change seat heating with 3 level";
CM_ SG_ 1030 MHU_SET_SeatHeatingRearR "Change seat heating with 3 level";
CM_ SG_ 1030 MHU_SET_SeatCoolingFrontL "Change seat cooling with 3 level";
CM_ SG_ 1030 MHU_SET_SeatCoolingFrontR "Change seat cooling with 3 level";
CM_ SG_ 1030 MHU_SET_SeatCoolingRearL "Change seat cooling with 3 level";
CM_ SG_ 1030 MHU_SET_SeatCoolingRearR "Change seat cooling with 3 level";
CM_ SG_ 1032 MHU_SET_MirrorAuto "Change mirror auto mode";
CM_ SG_ 1032 MHU_SET_MirrorAutoUnfold "setting Mirror Auto unfold mode";
CM_ SG_ 1032 MHU_SET_WLC "On Off wireless charger";
CM_ SG_ 1032 MHU_SET_AutoRearWiper "On Off Auto rear wiper";
CM_ SG_ 1032 MHU_SET_RearHeatedWindow "On Off Rear window heating";
CM_ SG_ 1032 MHU_TPMSReset "Request reset the TPMS";
CM_ SG_ 1032 MHU_SET_MirrorDefaultSetting "Trigger the default Mirror setting";
CM_ SG_ 1032 MHU_SET_MirrorReverseLink "On Off Mirror Auto Tilt on Reverse Gear ON OFF";
CM_ SG_ 1032 MHU_SET_AntiTheftMode "setting Anti-theft mode ";
CM_ SG_ 1032 MHU_SET_WLCReminder "On Off WLC reminder";
CM_ SG_ 1032 MHU_SET_ClimateKeepOn "Keep power for climate PET/CAMP mode";
CM_ SG_ 1032 MHU_SET_WLC2 "On Off wireless charger rear";
CM_ SG_ 1032 MHU_SET_WLC2Reminder "On Off WLC rear reminder";
CM_ SG_ 1032 MHU_IntrusionAlertStatus "Detection of Intrusion Alert in the MHU";
CM_ SG_ 1033 CHSKM_ADAS_WarnMsg "Checksum";
CM_ SG_ 1033 ALV_ADAS_WarnMsg "Alive Counter";
CM_ SG_ 1033 ADAS_Warning_Flag_1 "Warning Message Flag, Component owner, Supplier align and define for this signal";
CM_ SG_ 1033 ADAS_Warning_Flag_2 "Warning Message Flag, Component owner, Supplier align and define for this signal";
CM_ SG_ 1033 ADAS_Warning_Flag_3 "Warning Message Flag, Component owner, Supplier align and define for this signal";
CM_ SG_ 1033 ADAS_Warning_Flag_4 "Warning Message Flag, Component owner, Supplier align and define for this signal";
CM_ SG_ 1033 ADAS_Warning_Flag_5 "Warning Message Flag, Component owner, Supplier align and define for this signal";
CM_ SG_ 1033 ADAS_Warning_Flag_6 "Warning Message Flag, Component owner, Supplier align and define for this signal";
CM_ SG_ 1033 ADAS_Warning_Flag_7 "Warning Message Flag, Component owner, Supplier align and define for this signal";
CM_ SG_ 1033 ADAS_Warning_Flag_8 "Warning Message Flag, Component owner, Supplier align and define for this signal";
CM_ SG_ 1033 ADAS_Warning_Flag_9 "Warning Message Flag, Component owner, Supplier align and define for this signal";
CM_ SG_ 1033 ADAS_Warning_Flag_10 "Warning Message Flag, Component owner, Supplier align and define for this signal";
CM_ SG_ 1033 ADAS_Warning_Flag_11 "Warning Message Flag, Component owner, Supplier align and define for this signal";
CM_ SG_ 1033 ADAS_Warning_Flag_12 "Warning Message Flag, Component owner, Supplier align and define for this signal";
CM_ SG_ 1033 ADAS_Warning_Flag_13 "Warning Message Flag, Component owner, Supplier align and define for this signal";
CM_ SG_ 1033 ADAS_Warning_Flag_14 "Warning Message Flag, Component owner, Supplier align and define for this signal";
CM_ SG_ 1033 ADAS_Warning_Flag_15 "Warning Message Flag, Component owner, Supplier align and define for this signal";
CM_ SG_ 1033 ADAS_Warning_Flag_16 "Warning Message Flag, Component owner, Supplier align and define for this signal";
CM_ SG_ 1033 ADAS_Warning_Flag_17 "Warning Message Flag, Component owner, Supplier align and define for this signal";
CM_ SG_ 1033 ADAS_Warning_Flag_18 "Warning Message Flag, Component owner, Supplier align and define for this signal";
CM_ SG_ 1033 ADAS_Warning_Flag_19 "Warning Message Flag, Component owner, Supplier align and define for this signal";
CM_ SG_ 1033 ADAS_Warning_Flag_20 "Warning Message Flag, Component owner, Supplier align and define for this signal";
CM_ SG_ 1033 ADAS_Warning_Flag_21 "Warning Message Flag, Component owner, Supplier align and define for this signal";
CM_ SG_ 1033 ADAS_Warning_Flag_22 "Warning Message Flag, Component owner, Supplier align and define for this signal";
CM_ SG_ 1033 ADAS_Warning_Flag_23 "Warning Message Flag, Component owner, Supplier align and define for this signal";
CM_ SG_ 1033 ADAS_Warning_Flag_24 "Warning Message Flag, Component owner, Supplier align and define for this signal";
CM_ SG_ 1033 ADAS_Warning_Flag_25 "Warning Message Flag, Component owner, Supplier align and define for this signal";
CM_ SG_ 1033 ADAS_Warning_Flag_26 "Warning Message Flag, Component owner, Supplier align and define for this signal";
CM_ SG_ 1033 ADAS_Warning_Flag_27 "Warning Message Flag, Component owner, Supplier align and define for this signal";
CM_ SG_ 1033 ADAS_Warning_Flag_28 "Warning Message Flag, Component owner, Supplier align and define for this signal";
CM_ SG_ 1033 ADAS_Warning_Flag_29 "Warning Message Flag, Component owner, Supplier align and define for this signal";
CM_ SG_ 1033 ADAS_Warning_Flag_30 "Warning Message Flag, Component owner, Supplier align and define for this signal";
CM_ SG_ 1033 ADAS_Warning_Flag_31 "Warning Message Flag, Component owner, Supplier align and define for this signal";
CM_ SG_ 1033 ADAS_Warning_Flag_32 "Warning Message Flag, Component owner, Supplier align and define for this signal";
CM_ SG_ 1033 ADAS_Warning_Flag_33 "Warning Message Flag, Component owner, Supplier align and define for this signal";
CM_ SG_ 1033 ADAS_Warning_Flag_34 "Warning Message Flag, Component owner, Supplier align and define for this signal";
CM_ SG_ 1033 ADAS_Warning_Flag_35 "Warning Message Flag, Component owner, Supplier align and define for this signal";
CM_ SG_ 1033 ADAS_Warning_Flag_36 "Warning Message Flag, Component owner, Supplier align and define for this signal";
CM_ SG_ 1033 ADAS_Warning_Flag_37 "Warning Message Flag, Component owner, Supplier align and define for this signal";
CM_ SG_ 1033 ADAS_Warning_Flag_38 "Warning Message Flag, Component owner, Supplier align and define for this signal";
CM_ SG_ 1033 ADAS_Warning_Flag_39 "Warning Message Flag, Component owner, Supplier align and define for this signal";
CM_ SG_ 1033 ADAS_Warning_Flag_40 "Warning Message Flag, Component owner, Supplier align and define for this signal";
CM_ SG_ 1033 ADAS_Warning_Flag_41 "Warning Message Flag, Component owner, Supplier align and define for this signal";
CM_ SG_ 1033 ADAS_Warning_Flag_42 "Warning Message Flag, Component owner, Supplier align and define for this signal";
CM_ SG_ 1033 ADAS_Warning_Flag_43 "Warning Message Flag, Component owner, Supplier align and define for this signal";
CM_ SG_ 1033 ADAS_Warning_Flag_44 "Warning Message Flag, Component owner, Supplier align and define for this signal";
CM_ SG_ 1033 ADAS_Warning_Flag_45 "Warning Message Flag, Component owner, Supplier align and define for this signal";
CM_ SG_ 1033 ADAS_Warning_Flag_46 "Warning Message Flag, Component owner, Supplier align and define for this signal";
CM_ SG_ 1033 ADAS_Warning_Flag_47 "Warning Message Flag, Component owner, Supplier align and define for this signal";
CM_ SG_ 1033 ADAS_Warning_Flag_48 "Warning Message Flag, Component owner, Supplier align and define for this signal";
CM_ SG_ 1033 ADAS_Warning_Flag_49 "Warning Message Flag, Component owner, Supplier align and define for this signal";
CM_ SG_ 1033 ADAS_Warning_Flag_50 "Warning Message Flag, Component owner, Supplier align and define for this signal";
CM_ SG_ 1033 ADAS_Warning_Flag_51 "Warning Message Flag, Component owner, Supplier align and define for this signal";
CM_ SG_ 1033 ADAS_Warning_Flag_52 "Warning Message Flag, Component owner, Supplier align and define for this signal";
CM_ SG_ 1034 MHU_SET_HudUIContent "Set HUD content";
CM_ SG_ 1034 MHU_SET_HudUIColor "Set the HUD UI Color";
CM_ SG_ 1034 MHU_SET_HudScreenOnOFF "On Off HUD screen";
CM_ SG_ 1034 MHU_SET_UserBrightnessLvl "Set the HUD brightness";
CM_ SG_ 1034 MHU_SET_HudWorkingMode "Set HUD working mode: Normal mode or Position adjustment mode";
CM_ SG_ 1034 MHU_SET_HudUISize "Set the HUD UI Size";
CM_ SG_ 1034 MHU_SET_UIContentMediaInfo "Set ON/OFF HUD UI content for Radio/Media information";
CM_ SG_ 1034 MHU_SET_UIContentCallInfo "Set ON/OFF HUD UI Content for Incomming call information";
CM_ SG_ 1034 MHU_SET_UIContentPoweRegen "Set ON/OFF HUD UI Content for Power Regen gauge";
CM_ SG_ 1035 MHU_SET_AvasSound "Change the Engine Sound Volume";
CM_ SG_ 1036 CHSKM_MHU_SEAT_CONTROL "Checksum";
CM_ SG_ 1036 ALV_MHU_SEAT_CONTROL "Alive Counter";
CM_ SG_ 1036 MHU_DrvSeat_Control_Status "MHU driver seat control status";
CM_ SG_ 1036 MHU_ExpDrvReclinerPos "Expected recliner position of driver seat requested by MHU";
CM_ SG_ 1036 MHU_ExpDrvTiltPos "Expected tilt position of driver seat requested by MHU";
CM_ SG_ 1036 MHU_ExpDrvTrackPos "Expected track position of driver seat requested by MHU";
CM_ SG_ 1036 MHU_ExpDrvHeightPos "Expected height position of driver seat requested by MHU";
CM_ SG_ 1037 CHKSM_MHU_DIGIT_SPEED "Checksum";
CM_ SG_ 1037 ALV_MHU_DIGIT_SPEED "Alive Counter";
CM_ SG_ 1037 MHU_DigitSpeed "This signal represents the digital speed and is displayed; values between 301 and 511 are invalid.";
CM_ SG_ 1038 AveragePwrConsumpTripA "Average Power consumption for trip A, Max value ";
CM_ SG_ 1038 AverageFuelConsumpTripA "Average Fuel consumption for Trip A, Max value 51";
CM_ SG_ 1038 AvarageSpeedTripA "Average speed information for trip A; values between 301 and 511 are invalid.";
CM_ SG_ 1038 TripA "Information for trip A; values between 10001 and 13107.1 are invalid";
CM_ SG_ 1039 AveragePwrConsumpTripB "Average Power consumption for trip B, Max value ";
CM_ SG_ 1039 AverageFuelConsumpTripB "Average Fuel consumption for Trip B, Max value 51";
CM_ SG_ 1039 AvarageSpeedTripB "Average speed information for trip B; values between 301 and 511 are invalid.";
CM_ SG_ 1039 TripB "Information for trip B; values between 10001 and 13107.1 are invalid";
CM_ SG_ 1040 AveragePwrConsumpTripAuto "Average Power consumption for trip Auto, Max value ";
CM_ SG_ 1040 AverageFuelConsumpTripAuto "Average Fuel consumption for Trip Auto, Max value 51";
CM_ SG_ 1040 AvarageSpeedTripAuto "Average speed information for trip Auto; values between 301 and 511 are invalid.";
CM_ SG_ 1040 TripAuto "Information for trip Auto; values between 10001 and 13107.1 are invalid";
CM_ SG_ 1046 BCM_STAT_LeftMirrorPosX "Set left mirror left right position";
CM_ SG_ 1046 BCM_STAT_LeftMirrorPosY "Set left mirror up/down position";
CM_ SG_ 1046 BCM_STAT_RightMirrorPosX "Set right mirror left right position";
CM_ SG_ 1046 BCM_STAT_RightMirrorPosY "Set right mirror up down position";
CM_ SG_ 1046 BCM_STAT_Mirror "Represent the status of Mirror Fold/Unfold
";
CM_ SG_ 1046 BCM_STAT_MirrorAdjustLeft "Enter setting Mirror position mode";
CM_ SG_ 1046 BCM_STAT_MirrorAdjustRight "Enter setting Mirror position mode";
CM_ SG_ 1049 SHVU_STAT_SeatHeatingFrontL "Change Seat heating with 3 level";
CM_ SG_ 1049 SHVU_STAT_SeatHeatingFrontR "Change Seat heating with 3 level";
CM_ SG_ 1049 SHVU_STAT_SeatCoolingFrontL "Change Seat cooling with 3 level";
CM_ SG_ 1049 SHVU_STAT_SeatCoolingFrontR "Change Seat cooling with 3 level";
CM_ SG_ 1049 SHVU_STAT_FrontSeatVentSts "Indicate current status of front seat ventilation system";
CM_ SG_ 1050 SHVU_STAT_SeatCoolingRearL "Change Seat cooling with 3 level";
CM_ SG_ 1050 SHVU_STAT_SeatCoolingRearR "Change Seat cooling with 3 level";
CM_ SG_ 1050 SHVU_STAT_SeatHeatingReartL "Change Seat heating with 3 level";
CM_ SG_ 1050 SHVU_STAT_SeatHeatingRearR "Change Seat heating with 3 level";
CM_ SG_ 1050 SHVU_STAT_RearSeatVentSts "Indicate current status of rear seat ventilation system";
CM_ SG_ 1052 CHKSM_PSM_SEAT_POSITION "Checksum";
CM_ SG_ 1052 AVL_PSM_SEAT_POSITION "Alive Counter";
CM_ SG_ 1052 PSM_Seat_track_pos_Dri "PSM Seat track position driver";
CM_ SG_ 1052 PSM_Seat_track_posPas "PSM Seat track position front passenger";
CM_ SG_ 1053 BCM_STAT_AutoRearWiper "On/Off Auto rear wiper";
CM_ SG_ 1053 BCM_STAT_MirrorFoldSetting "Status MirrorFold Default value =  0x1 Auto Fold ON/Invalid value = 3";
CM_ SG_ 1053 BCM_STAT_IMMO_KeyfobID2 "console as per request of a MHU to link keyfob to a profile - improvement signal";
CM_ SG_ 1053 BCM_STAT_MirrorAutoUnfold "Change Mirror Auto unfold mode";
CM_ SG_ 1053 BCM_STAT_MirrorReverseLink "On/Off Mirror Auto Tilt on Reverse Gear ON/OFF";
CM_ SG_ 1053 BCM_STAT_MirrorDefaultSTATting "Trigger the default Mirror setting";
CM_ SG_ 1053 BCM_STAT_WelcomeTriggerCondition "Confirm Welcome trigger condition";
CM_ SG_ 1053 BCM_STAT_FrontDomeLamp "Confirm setting On/Off/Auto Front Dome Lamp";
CM_ SG_ 1053 BCM_STAT_FollowMeHome "Change follow me home headlamp mode and delay";
CM_ SG_ 1053 BCM_STAT_ExteriorLight "Change Exterior light mode";
CM_ SG_ 1053 BCM_STAT_RemoteLockFeedback "Remote Lock dback: customer can choose light feedback when lock the door with remote key";
CM_ SG_ 1053 BCM_STAT_RemoteDoorUnlock "Settings for Door lock unlock conditions";
CM_ SG_ 1053 BCM_STAT_AutoDoorUnlock "Auto door unlock: When the car is stopped and the shift lever is in ?P? position, selected doors will be unlocked automatically";
CM_ SG_ 1053 BCM_STAT_AmbientLightBrighness "Change Ambient light brighness percent";
CM_ SG_ 1053 BCM_STAT_WiperServiceMode "console as per request of a MHU to link keybof to a";
CM_ SG_ 1053 BCM_STAT_IMMO_KeyfobID "console as per request of a MHU to link keybof to a";
CM_ SG_ 1053 BCM_STAT_RearHeatedWindowMirror "This signal is necessary for the activation or deactivation of the rear screen heating for the rear window and the mirrors.Invalid value = 3";
CM_ SG_ 1053 BCM_STAT_AntiTheftMode "Confirm of setting Anti-theft mode ";
CM_ SG_ 1053 BCM_STAT_ClimateKeepOnSts "Climate keep ON feedback status
";
CM_ SG_ 1053 BCM_STAT_FKSfeedback "BCM_STAT_FKSfeedback";
CM_ SG_ 1053 SECCAN_CmftCnfrm "Secret portion from Secure CAN algorithm";

BA_DEF_ BO_  "GenMsgSendType" ENUM "Cyclic","NotUsed","NotUsed","NotUsed","NotUsed","NotUsed","NotUsed","IfActive","NoMsgSendType","NotUsed";
BA_DEF_ BO_  "GenMsgILSupport" ENUM "No","Yes";
BA_DEF_ BO_  "DiagResponse" ENUM "No","Yes";
BA_DEF_ BO_  "DiagRequest" ENUM "No","Yes";
BA_DEF_ BO_  "NmAsrMessage" ENUM "No","Yes";
BA_DEF_ BO_  "DiagState" ENUM "No","Yes";
BA_DEF_ BO_  "DiagUudtResponse" ENUM "False","True";
BA_DEF_ BO_  "GenMsgStartDelayTime" INT 0 65535;
BA_DEF_ BO_  "GenMsgDelayTime" INT 0 0;
BA_DEF_ BO_  "GenMsgNrOfRepetition" INT 0 0;
BA_DEF_ BO_  "GenMsgCycleTimeFast" INT 0 0;
BA_DEF_ BO_  "GenMsgCycleTime" INT 0 0;
BA_DEF_ SG_  "GenSigSendType" ENUM "Cyclic","OnWrite","OnWriteWithRepetition","OnChange","OnChangeWithRepetition","IfActive","IfActiveWithRepetition","NoSigSendType","NotUsed","NotUsed","NotUsed","NotUsed","NotUsed";
BA_DEF_ SG_  "InvalidValue" STRING;
BA_DEF_ SG_  "GenSigStartValue" INT 0 0;
BA_DEF_ SG_  "GenSigTimeoutTime_ALL" INT 0 65535;
BA_DEF_DEF_  "DiagRequest" "No";
BA_DEF_DEF_  "DiagResponse" "No";
BA_DEF_DEF_  "DiagState" "No";
BA_DEF_DEF_  "DiagUudtResponse" "False";
BA_DEF_DEF_  "GenMsgCycleTime" 0;
BA_DEF_DEF_  "GenMsgCycleTimeFast" 0;
BA_DEF_DEF_  "GenMsgDelayTime" 0;
BA_DEF_DEF_  "GenMsgILSupport" "Yes";
BA_DEF_DEF_  "GenMsgNrOfRepetition" 0;
BA_DEF_DEF_  "GenMsgSendType" "NoMsgSendType";
BA_DEF_DEF_  "GenMsgStartDelayTime" 0;
BA_DEF_DEF_  "GenSigSendType" "Cyclic";
BA_DEF_DEF_  "GenSigStartValue" 0;
BA_DEF_DEF_  "GenSigTimeoutTime_ALL" 0;
BA_DEF_DEF_  "NmAsrMessage" "No";
BA_ "GenMsgCycleTimeFast" BO_ 784 20;
BA_ "GenMsgNrOfRepetition" BO_ 784 2;
BA_ "GenMsgCycleTime" BO_ 787 100;
BA_ "GenMsgSendType" BO_ 787 0;
BA_ "GenMsgCycleTime" BO_ 803 100;
BA_ "GenMsgSendType" BO_ 803 0;
BA_ "GenMsgCycleTime" BO_ 804 100;
BA_ "GenMsgSendType" BO_ 804 0;
BA_ "GenMsgCycleTime" BO_ 805 100;
BA_ "GenMsgSendType" BO_ 805 0;
BA_ "GenMsgCycleTime" BO_ 806 100;
BA_ "GenMsgSendType" BO_ 806 0;
BA_ "GenMsgCycleTime" BO_ 808 1000;
BA_ "GenMsgSendType" BO_ 808 0;
BA_ "GenMsgCycleTime" BO_ 809 1000;
BA_ "GenMsgSendType" BO_ 809 0;
BA_ "GenMsgCycleTime" BO_ 816 100;
BA_ "GenMsgSendType" BO_ 816 0;
BA_ "GenMsgSendType" BO_ 818 0;
BA_ "GenMsgCycleTime" BO_ 818 100;
BA_ "GenMsgCycleTime" BO_ 827 100;
BA_ "GenMsgSendType" BO_ 827 0;
BA_ "GenMsgCycleTime" BO_ 833 100;
BA_ "GenMsgSendType" BO_ 833 0;
BA_ "GenMsgCycleTime" BO_ 835 100;
BA_ "GenMsgSendType" BO_ 835 0;
BA_ "GenMsgCycleTime" BO_ 838 100;
BA_ "GenMsgSendType" BO_ 838 0;
BA_ "GenMsgCycleTime" BO_ 842 100;
BA_ "GenMsgSendType" BO_ 842 0;
BA_ "GenMsgCycleTime" BO_ 844 100;
BA_ "GenMsgSendType" BO_ 844 0;
BA_ "GenMsgCycleTime" BO_ 845 100;
BA_ "GenMsgSendType" BO_ 845 0;
BA_ "GenMsgCycleTime" BO_ 846 100;
BA_ "GenMsgSendType" BO_ 846 0;
BA_ "GenMsgCycleTime" BO_ 849 50;
BA_ "GenMsgSendType" BO_ 849 0;
BA_ "GenMsgCycleTime" BO_ 850 50;
BA_ "GenMsgSendType" BO_ 850 0;
BA_ "GenMsgCycleTime" BO_ 851 50;
BA_ "GenMsgSendType" BO_ 851 0;
BA_ "GenMsgCycleTimeFast" BO_ 852 50;
BA_ "GenMsgNrOfRepetition" BO_ 852 2;
BA_ "GenMsgCycleTime" BO_ 853 50;
BA_ "GenMsgSendType" BO_ 853 0;
BA_ "GenMsgCycleTime" BO_ 880 300;
BA_ "GenMsgSendType" BO_ 880 0;
BA_ "GenMsgCycleTime" BO_ 885 50;
BA_ "GenMsgILSupport" BO_ 885 0;
BA_ "GenMsgSendType" BO_ 885 0;
BA_ "GenMsgCycleTime" BO_ 896 1000;
BA_ "GenMsgSendType" BO_ 896 0;
BA_ "GenMsgCycleTime" BO_ 897 200;
BA_ "GenMsgSendType" BO_ 897 0;
BA_ "GenMsgDelayTime" BO_ 905 10;
BA_ "GenMsgCycleTimeFast" BO_ 915 50;
BA_ "GenMsgNrOfRepetition" BO_ 915 2;
BA_ "GenMsgCycleTimeFast" BO_ 919 100;
BA_ "GenMsgNrOfRepetition" BO_ 919 3;
BA_ "GenMsgCycleTimeFast" BO_ 922 100;
BA_ "GenMsgNrOfRepetition" BO_ 922 3;
BA_ "GenMsgCycleTimeFast" BO_ 923 100;
BA_ "GenMsgNrOfRepetition" BO_ 923 3;
BA_ "GenMsgCycleTime" BO_ 925 50;
BA_ "GenMsgSendType" BO_ 925 0;
BA_ "GenMsgCycleTime" BO_ 992 150;
BA_ "GenMsgSendType" BO_ 992 0;
BA_ "GenMsgCycleTime" BO_ 993 100;
BA_ "GenMsgSendType" BO_ 993 0;
BA_ "GenMsgCycleTime" BO_ 1015 1000;
BA_ "GenMsgCycleTimeFast" BO_ 1015 50;
BA_ "GenMsgNrOfRepetition" BO_ 1015 3;
BA_ "GenMsgSendType" BO_ 1015 0;
BA_ "GenMsgCycleTime" BO_ 1020 500;
BA_ "GenMsgSendType" BO_ 1020 0;
BA_ "GenMsgCycleTimeFast" BO_ 1025 100;
BA_ "GenMsgNrOfRepetition" BO_ 1025 3;
BA_ "GenMsgCycleTime" BO_ 1026 100;
BA_ "GenMsgCycleTimeFast" BO_ 1026 100;
BA_ "GenMsgNrOfRepetition" BO_ 1026 3;
BA_ "GenMsgSendType" BO_ 1026 0;
BA_ "GenMsgCycleTime" BO_ 1027 100;
BA_ "GenMsgSendType" BO_ 1027 0;
BA_ "GenMsgCycleTimeFast" BO_ 1028 100;
BA_ "GenMsgNrOfRepetition" BO_ 1028 3;
BA_ "GenMsgCycleTimeFast" BO_ 1029 50;
BA_ "GenMsgNrOfRepetition" BO_ 1029 3;
BA_ "GenMsgCycleTimeFast" BO_ 1030 100;
BA_ "GenMsgNrOfRepetition" BO_ 1030 3;
BA_ "GenMsgCycleTimeFast" BO_ 1032 100;
BA_ "GenMsgNrOfRepetition" BO_ 1032 3;
BA_ "GenMsgCycleTime" BO_ 1033 1000;
BA_ "GenMsgSendType" BO_ 1033 0;
BA_ "GenMsgCycleTimeFast" BO_ 1034 50;
BA_ "GenMsgNrOfRepetition" BO_ 1034 2;
BA_ "GenMsgCycleTimeFast" BO_ 1035 100;
BA_ "GenMsgNrOfRepetition" BO_ 1035 3;
BA_ "GenMsgCycleTime" BO_ 1036 200;
BA_ "GenMsgSendType" BO_ 1036 0;
BA_ "GenMsgCycleTime" BO_ 1037 120;
BA_ "GenMsgSendType" BO_ 1037 0;
BA_ "GenMsgCycleTime" BO_ 1038 1000;
BA_ "GenMsgSendType" BO_ 1038 0;
BA_ "GenMsgCycleTime" BO_ 1039 1000;
BA_ "GenMsgSendType" BO_ 1039 0;
BA_ "GenMsgCycleTime" BO_ 1040 1000;
BA_ "GenMsgSendType" BO_ 1040 0;
BA_ "GenMsgCycleTime" BO_ 1046 100;
BA_ "GenMsgSendType" BO_ 1046 0;
BA_ "GenMsgCycleTime" BO_ 1052 1000;
BA_ "GenMsgSendType" BO_ 1052 0;
BA_ "GenMsgCycleTime" BO_ 1053 100;
BA_ "GenMsgSendType" BO_ 1053 0;
BA_ "GenSigSendType" SG_ 777 ADAS_Immo_MHU_Byte_0 1;
BA_ "GenSigSendType" SG_ 777 ADAS_Immo_MHU_Byte_1 1;
BA_ "GenSigSendType" SG_ 777 ADAS_Immo_MHU_Byte_2 1;
BA_ "GenSigSendType" SG_ 777 ADAS_Immo_MHU_Byte_3 1;
BA_ "GenSigSendType" SG_ 777 ADAS_Immo_MHU_Byte_4 1;
BA_ "GenSigSendType" SG_ 777 ADAS_Immo_MHU_Byte_5 1;
BA_ "GenSigSendType" SG_ 777 ADAS_Immo_MHU_Byte_6 1;
BA_ "GenSigSendType" SG_ 777 ADAS_Immo_MHU_Byte_7 1;
BA_ "GenSigSendType" SG_ 784 CCUR_STAT_IonButton 4;
BA_ "InvalidValue" SG_ 784 CCUR_STAT_IonButton "3h";
BA_ "GenSigSendType" SG_ 784 CCUR_STAT_Defrost 4;
BA_ "InvalidValue" SG_ 784 CCUR_STAT_Defrost "3h";
BA_ "GenSigSendType" SG_ 784 CCUR_STAT_Auto 4;
BA_ "InvalidValue" SG_ 784 CCUR_STAT_Auto "3h";
BA_ "GenSigSendType" SG_ 784 CCUR_STAT_Aircondition 4;
BA_ "InvalidValue" SG_ 784 CCUR_STAT_Aircondition "3h";
BA_ "GenSigSendType" SG_ 784 CCUR_STAT_FlapPos 4;
BA_ "InvalidValue" SG_ 784 CCUR_STAT_FlapPos "Fh";
BA_ "GenSigSendType" SG_ 784 CCUR_STAT_FanSpeed 4;
BA_ "InvalidValue" SG_ 784 CCUR_STAT_FanSpeed "Fh";
BA_ "GenSigSendType" SG_ 784 CCUR_STAT_PTC_Heater 4;
BA_ "InvalidValue" SG_ 784 CCUR_STAT_PTC_Heater "7h";
BA_ "GenSigSendType" SG_ 784 CCUR_STAT_OnOff 4;
BA_ "GenSigStartValue" SG_ 784 CCUR_STAT_OnOff 3;
BA_ "InvalidValue" SG_ 784 CCUR_STAT_OnOff "3h";
BA_ "GenSigSendType" SG_ 784 CCUR_STAT_MaxAc 4;
BA_ "InvalidValue" SG_ 784 CCUR_STAT_MaxAc "3h";
BA_ "GenSigSendType" SG_ 784 CCUR_STAT_SyncClimateZone 4;
BA_ "InvalidValue" SG_ 784 CCUR_STAT_SyncClimateZone "3h";
BA_ "GenSigSendType" SG_ 784 CCUR_STAT_RecircFlap 4;
BA_ "GenSigStartValue" SG_ 784 CCUR_STAT_RecircFlap 1;
BA_ "InvalidValue" SG_ 784 CCUR_STAT_RecircFlap "3h";
BA_ "GenSigSendType" SG_ 784 CCUR_STAT_TempRear 4;
BA_ "GenSigStartValue" SG_ 784 CCUR_STAT_TempRear 40;
BA_ "InvalidValue" SG_ 784 CCUR_STAT_TempRear "null";
BA_ "InvalidValue" SG_ 784 CCUR_STAT_TempRear "null";
BA_ "GenSigTimeoutTime_ALL" SG_ 787 CHSKM_POD_StatusCharger1 500;
BA_ "InvalidValue" SG_ 787 CHSKM_POD_StatusCharger1 "null";
BA_ "GenSigTimeoutTime_ALL" SG_ 787 ALV_POD_StatusCharger1 500;
BA_ "InvalidValue" SG_ 787 ALV_POD_StatusCharger1 "Fh";
BA_ "GenSigTimeoutTime_ALL" SG_ 787 POD_statusOBC 500;
BA_ "InvalidValue" SG_ 787 POD_statusOBC "null";
BA_ "GenSigTimeoutTime_ALL" SG_ 787 POD_OBC_Max_Current_Out 500;
BA_ "InvalidValue" SG_ 787 POD_OBC_Max_Current_Out "null";
BA_ "GenSigTimeoutTime_ALL" SG_ 787 POD_iDCOut 500;
BA_ "InvalidValue" SG_ 787 POD_iDCOut "FFh";
BA_ "GenSigTimeoutTime_ALL" SG_ 787 POD_vDCOut 500;
BA_ "InvalidValue" SG_ 787 POD_vDCOut "FFFFh";
BA_ "GenSigTimeoutTime_ALL" SG_ 803 CHSKM_POD_StatusCharger2 500;
BA_ "InvalidValue" SG_ 803 CHSKM_POD_StatusCharger2 "null";
BA_ "GenSigTimeoutTime_ALL" SG_ 803 ALV_POD_StatusCharger2 500;
BA_ "InvalidValue" SG_ 803 ALV_POD_StatusCharger2 "Fh";
BA_ "GenSigStartValue" SG_ 803 POD_phaseACInput 1;
BA_ "GenSigTimeoutTime_ALL" SG_ 803 POD_phaseACInput 500;
BA_ "InvalidValue" SG_ 803 POD_phaseACInput "0";
BA_ "GenSigTimeoutTime_ALL" SG_ 803 POD_iACInput 500;
BA_ "InvalidValue" SG_ 803 POD_iACInput "null";
BA_ "GenSigTimeoutTime_ALL" SG_ 803 POD_vACInput 500;
BA_ "InvalidValue" SG_ 803 POD_vACInput "null";
BA_ "GenSigTimeoutTime_ALL" SG_ 804 Steering_HeatingControl 500;
BA_ "InvalidValue" SG_ 804 Steering_HeatingControl "7h";
BA_ "GenSigTimeoutTime_ALL" SG_ 805 Steering_HeatingControlFdbk 500;
BA_ "InvalidValue" SG_ 805 Steering_HeatingControlFdbk "3h";
BA_ "GenSigTimeoutTime_ALL" SG_ 806 CHSKM_POD_StatusDCDC1 500;
BA_ "InvalidValue" SG_ 806 CHSKM_POD_StatusDCDC1 "null";
BA_ "GenSigSendType" SG_ 806 ALV_POD_StatusDCDC1 3;
BA_ "GenSigTimeoutTime_ALL" SG_ 806 ALV_POD_StatusDCDC1 500;
BA_ "InvalidValue" SG_ 806 ALV_POD_StatusDCDC1 "Fh";
BA_ "GenSigTimeoutTime_ALL" SG_ 806 POD_statusDCDC 500;
BA_ "InvalidValue" SG_ 806 POD_statusDCDC "7h";
BA_ "GenSigTimeoutTime_ALL" SG_ 806 POD_DCDC_Max_Current_Out 500;
BA_ "InvalidValue" SG_ 806 POD_DCDC_Max_Current_Out "FFh";
BA_ "GenSigTimeoutTime_ALL" SG_ 808 T_SEC_COU_REL 5000;
BA_ "InvalidValue" SG_ 808 T_SEC_COU_REL "FFFFFFFFh";
BA_ "GenSigTimeoutTime_ALL" SG_ 808 T_DAY_COU_ABSL 5000;
BA_ "InvalidValue" SG_ 808 T_DAY_COU_ABSL "FFFFh";
BA_ "GenSigTimeoutTime_ALL" SG_ 809 CRC_BCM_ODO 5000;
BA_ "InvalidValue" SG_ 809 CRC_BCM_ODO "null";
BA_ "GenSigTimeoutTime_ALL" SG_ 809 ALIV_BCM_ODO 5000;
BA_ "InvalidValue" SG_ 809 ALIV_BCM_ODO "Fh";
BA_ "GenSigTimeoutTime_ALL" SG_ 809 Odometer_BCM 5000;
BA_ "InvalidValue" SG_ 809 Odometer_BCM "FFFFFFh";
BA_ "GenSigTimeoutTime_ALL" SG_ 809 SECCAN_BCM_ODO 5000;
BA_ "GenSigTimeoutTime_ALL" SG_ 809 SECCAN_BCM_ODO 5000;
BA_ "InvalidValue" SG_ 809 SECCAN_BCM_ODO "null";
BA_ "GenSigTimeoutTime_ALL" SG_ 816 MILE_KM 500;
BA_ "InvalidValue" SG_ 816 MILE_KM "FFFFFFh";
BA_ "GenSigTimeoutTime_ALL" SG_ 816 FLLV_FUTA 500;
BA_ "InvalidValue" SG_ 816 FLLV_FUTA "FFh";
BA_ "GenSigTimeoutTime_ALL" SG_ 816 RNG 500;
BA_ "InvalidValue" SG_ 816 RNG "FFFh";
BA_ "GenSigTimeoutTime_ALL" SG_ 816 ST_FLLV_FUTA_SPAR 500;
BA_ "InvalidValue" SG_ 816 ST_FLLV_FUTA_SPAR "3h";
BA_ "GenSigTimeoutTime_ALL" SG_ 818 Checksum_0x332 500;
BA_ "InvalidValue" SG_ 818 Checksum_0x332 "null";
BA_ "GenSigTimeoutTime_ALL" SG_ 818 Rolling_Counter_0x332 500;
BA_ "InvalidValue" SG_ 818 Rolling_Counter_0x332 "Fh";
BA_ "GenSigTimeoutTime_ALL" SG_ 818 BMS_PackCNom 500;
BA_ "InvalidValue" SG_ 818 BMS_PackCNom "FFFFh";
BA_ "GenSigStartValue" SG_ 818 BMS_PackTemp_0x332 80;
BA_ "GenSigTimeoutTime_ALL" SG_ 818 BMS_PackTemp_0x332 500;
BA_ "InvalidValue" SG_ 818 BMS_PackTemp_0x332 "FFh";
BA_ "GenSigTimeoutTime_ALL" SG_ 827 CHKSM_CameraLane 500;
BA_ "GenSigTimeoutTime_ALL" SG_ 827 ALV_ADAS_Cameralane 500;
BA_ "InvalidValue" SG_ 827 ALV_ADAS_Cameralane "Fh";
BA_ "GenSigTimeoutTime_ALL" SG_ 827 Camera_R1_Line_Type 500;
BA_ "InvalidValue" SG_ 827 Camera_R1_Line_Type "Fh";
BA_ "GenSigTimeoutTime_ALL" SG_ 827 Camera_L1_Line_Type 500;
BA_ "InvalidValue" SG_ 827 Camera_L1_Line_Type "Fh";
BA_ "GenSigTimeoutTime_ALL" SG_ 827 R0_ExistProbability 500;
BA_ "InvalidValue" SG_ 827 R0_ExistProbability "Fh";
BA_ "GenSigTimeoutTime_ALL" SG_ 827 L0_ExistProbability 500;
BA_ "InvalidValue" SG_ 827 L0_ExistProbability "Fh";
BA_ "GenSigTimeoutTime_ALL" SG_ 827 L1_ExistProbability 500;
BA_ "InvalidValue" SG_ 827 L1_ExistProbability "Fh";
BA_ "GenSigTimeoutTime_ALL" SG_ 827 R1_ExistProbability 500;
BA_ "InvalidValue" SG_ 827 R1_ExistProbability "Fh";
BA_ "GenSigTimeoutTime_ALL" SG_ 827 SECCAN_CameraLane 500;
BA_ "GenSigTimeoutTime_ALL" SG_ 833 SECCAN_Cam_OBJ_1 500;
BA_ "GenSigTimeoutTime_ALL" SG_ 833 ADAS_OBJ01_Class 500;
BA_ "InvalidValue" SG_ 833 ADAS_OBJ01_Class "7";
BA_ "GenSigStartValue" SG_ 833 ADAS_OBJ01_LgtDis 400;
BA_ "GenSigTimeoutTime_ALL" SG_ 833 ADAS_OBJ01_LgtDis 500;
BA_ "InvalidValue" SG_ 833 ADAS_OBJ01_LgtDis "3FFF";
BA_ "GenSigTimeoutTime_ALL" SG_ 833 ADAS_OBJ01_ID 500;
BA_ "InvalidValue" SG_ 833 ADAS_OBJ01_ID "FF";
BA_ "GenSigTimeoutTime_ALL" SG_ 833 ADAS_OBJ01_LatDis 500;
BA_ "GenSigTimeoutTime_ALL" SG_ 833 ADAS_OBJ01_Lane 500;
BA_ "InvalidValue" SG_ 833 ADAS_OBJ01_Lane "7";
BA_ "GenSigTimeoutTime_ALL" SG_ 835 SECCAN_Cam_OBJ_2 500;
BA_ "GenSigTimeoutTime_ALL" SG_ 835 ADAS_OBJ02_Class 500;
BA_ "InvalidValue" SG_ 835 ADAS_OBJ02_Class "7";
BA_ "GenSigStartValue" SG_ 835 ADAS_OBJ02_LgtDis 400;
BA_ "GenSigTimeoutTime_ALL" SG_ 835 ADAS_OBJ02_LgtDis 500;
BA_ "InvalidValue" SG_ 835 ADAS_OBJ02_LgtDis "3FF";
BA_ "GenSigTimeoutTime_ALL" SG_ 835 ADAS_OBJ02_ID 500;
BA_ "InvalidValue" SG_ 835 ADAS_OBJ02_ID "FF";
BA_ "GenSigTimeoutTime_ALL" SG_ 835 ADAS_OBJ02_LatDis 500;
BA_ "InvalidValue" SG_ 835 ADAS_OBJ02_LatDis "3FF";
BA_ "GenSigTimeoutTime_ALL" SG_ 835 ADAS_OBJ02_Lane 500;
BA_ "InvalidValue" SG_ 835 ADAS_OBJ02_Lane "7";
BA_ "GenSigTimeoutTime_ALL" SG_ 838 CHSKM_POD_StatusDCDC2 500;
BA_ "InvalidValue" SG_ 838 CHSKM_POD_StatusDCDC2 "null";
BA_ "GenSigTimeoutTime_ALL" SG_ 838 ALV_POD_StatusDCDC2 500;
BA_ "InvalidValue" SG_ 838 ALV_POD_StatusDCDC2 "Fh";
BA_ "GenSigTimeoutTime_ALL" SG_ 838 POD_vDCInput 500;
BA_ "InvalidValue" SG_ 838 POD_vDCInput "FFFFh";
BA_ "GenSigTimeoutTime_ALL" SG_ 838 POD_iDCDCOutput 500;
BA_ "InvalidValue" SG_ 838 POD_iDCDCOutput "FFFFh";
BA_ "GenSigTimeoutTime_ALL" SG_ 838 POD_vDCDCOutput 500;
BA_ "InvalidValue" SG_ 838 POD_vDCDCOutput "FFFFh";
BA_ "GenSigTimeoutTime_ALL" SG_ 842 SECCAN_Cam_OBJ_3 500;
BA_ "GenSigTimeoutTime_ALL" SG_ 842 ADAS_OBJ03_Class 500;
BA_ "InvalidValue" SG_ 842 ADAS_OBJ03_Class "7";
BA_ "GenSigStartValue" SG_ 842 ADAS_OBJ03_LgtDis 400;
BA_ "GenSigTimeoutTime_ALL" SG_ 842 ADAS_OBJ03_LgtDis 500;
BA_ "InvalidValue" SG_ 842 ADAS_OBJ03_LgtDis "3FF";
BA_ "GenSigTimeoutTime_ALL" SG_ 842 ADAS_OBJ03_ID 500;
BA_ "InvalidValue" SG_ 842 ADAS_OBJ03_ID "FF";
BA_ "GenSigTimeoutTime_ALL" SG_ 842 ADAS_OBJ03_LatDis 500;
BA_ "InvalidValue" SG_ 842 ADAS_OBJ03_LatDis "3FF";
BA_ "GenSigTimeoutTime_ALL" SG_ 842 ADAS_OBJ03_Lane 500;
BA_ "InvalidValue" SG_ 842 ADAS_OBJ03_Lane "7";
BA_ "GenSigTimeoutTime_ALL" SG_ 844 SECCAN_Cam_OBJ_4 500;
BA_ "GenSigTimeoutTime_ALL" SG_ 844 ADAS_OBJ04_Class 500;
BA_ "InvalidValue" SG_ 844 ADAS_OBJ04_Class "7";
BA_ "GenSigStartValue" SG_ 844 ADAS_OBJ04_LgtDis 400;
BA_ "GenSigTimeoutTime_ALL" SG_ 844 ADAS_OBJ04_LgtDis 500;
BA_ "InvalidValue" SG_ 844 ADAS_OBJ04_LgtDis "3FFF";
BA_ "GenSigTimeoutTime_ALL" SG_ 844 ADAS_OBJ04_ID 500;
BA_ "InvalidValue" SG_ 844 ADAS_OBJ04_ID "FF";
BA_ "GenSigTimeoutTime_ALL" SG_ 844 ADAS_OBJ04_LatDis 500;
BA_ "GenSigTimeoutTime_ALL" SG_ 844 ADAS_OBJ04_Lane 500;
BA_ "InvalidValue" SG_ 844 ADAS_OBJ04_Lane "7";
BA_ "GenSigTimeoutTime_ALL" SG_ 845 SECCAN_Cam_OBJ_5 500;
BA_ "GenSigTimeoutTime_ALL" SG_ 845 ADAS_OBJ05_Class 500;
BA_ "InvalidValue" SG_ 845 ADAS_OBJ05_Class "7";
BA_ "GenSigStartValue" SG_ 845 ADAS_OBJ05_LgtDis 400;
BA_ "GenSigTimeoutTime_ALL" SG_ 845 ADAS_OBJ05_LgtDis 500;
BA_ "InvalidValue" SG_ 845 ADAS_OBJ05_LgtDis "3FFF";
BA_ "GenSigTimeoutTime_ALL" SG_ 845 ADAS_OBJ05_ID 500;
BA_ "InvalidValue" SG_ 845 ADAS_OBJ05_ID "FF";
BA_ "GenSigTimeoutTime_ALL" SG_ 845 ADAS_OBJ05_LatDis 500;
BA_ "GenSigTimeoutTime_ALL" SG_ 845 ADAS_OBJ05_Lane 500;
BA_ "InvalidValue" SG_ 845 ADAS_OBJ05_Lane "7";
BA_ "GenSigTimeoutTime_ALL" SG_ 846 SECCAN_Cam_OBJ_6 500;
BA_ "GenSigTimeoutTime_ALL" SG_ 846 ADAS_OBJ06_Class 500;
BA_ "InvalidValue" SG_ 846 ADAS_OBJ06_Class "7";
BA_ "GenSigStartValue" SG_ 846 ADAS_OBJ06_LgtDis 400;
BA_ "GenSigTimeoutTime_ALL" SG_ 846 ADAS_OBJ06_LgtDis 500;
BA_ "InvalidValue" SG_ 846 ADAS_OBJ06_LgtDis "3FFF";
BA_ "GenSigTimeoutTime_ALL" SG_ 846 ADAS_OBJ06_ID 500;
BA_ "InvalidValue" SG_ 846 ADAS_OBJ06_ID "FF";
BA_ "GenSigTimeoutTime_ALL" SG_ 846 ADAS_OBJ06_LatDis 500;
BA_ "GenSigTimeoutTime_ALL" SG_ 846 ADAS_OBJ06_Lane 500;
BA_ "InvalidValue" SG_ 846 ADAS_OBJ06_Lane "7";
BA_ "GenSigTimeoutTime_ALL" SG_ 849 CHKSM_ADAS_PA 500;
BA_ "GenSigTimeoutTime_ALL" SG_ 849 ALV_ADAS_PA 500;
BA_ "InvalidValue" SG_ 849 ALV_ADAS_PA "Fh";
BA_ "GenSigStartValue" SG_ 849 ADAS_PA_AutoOn_Feed 1;
BA_ "GenSigTimeoutTime_ALL" SG_ 849 ADAS_PA_AutoOn_Feed 500;
BA_ "GenSigTimeoutTime_ALL" SG_ 849 ADAS_PA_AlertFRI 500;
BA_ "GenSigTimeoutTime_ALL" SG_ 849 ADAS_PA_AlertFLI 500;
BA_ "GenSigTimeoutTime_ALL" SG_ 849 ADAS_PA_AlertFLO 500;
BA_ "GenSigTimeoutTime_ALL" SG_ 849 ADAS_PA_AlertRLO 500;
BA_ "GenSigTimeoutTime_ALL" SG_ 849 ADAS_PA_AlertRLI 500;
BA_ "GenSigTimeoutTime_ALL" SG_ 849 ADAS_PA_AlertFRO 500;
BA_ "GenSigTimeoutTime_ALL" SG_ 849 ADAS_PA_AlertRRO 500;
BA_ "GenSigTimeoutTime_ALL" SG_ 849 ADAS_PA_AlertRRI 500;
BA_ "GenSigTimeoutTime_ALL" SG_ 849 ADAS_PA_state 500;
BA_ "GenSigTimeoutTime_ALL" SG_ 850 CHKSM_ADAS_AHB_DOW 500;
BA_ "GenSigTimeoutTime_ALL" SG_ 850 ALV_ADAS_AHB_DOW 500;
BA_ "InvalidValue" SG_ 850 ALV_ADAS_AHB_DOW "Fh";
BA_ "GenSigTimeoutTime_ALL" SG_ 850 ADAS_AHB_sens_Feed 500;
BA_ "InvalidValue" SG_ 850 ADAS_AHB_sens_Feed "3h";
BA_ "GenSigTimeoutTime_ALL" SG_ 850 ADAS_AHB_Mode_Feed 500;
BA_ "GenSigTimeoutTime_ALL" SG_ 850 ADAS_AHB_check 500;
BA_ "InvalidValue" SG_ 850 ADAS_AHB_check "3h";
BA_ "GenSigTimeoutTime_ALL" SG_ 850 ADAS_AHB_state 500;
BA_ "InvalidValue" SG_ 850 ADAS_AHB_state "3h";
BA_ "GenSigTimeoutTime_ALL" SG_ 850 ADAS_DOW_WarnRight 500;
BA_ "InvalidValue" SG_ 850 ADAS_DOW_WarnRight "3h";
BA_ "GenSigTimeoutTime_ALL" SG_ 850 ADAS_DOW_SndWarn 500;
BA_ "InvalidValue" SG_ 850 ADAS_DOW_SndWarn "3h";
BA_ "GenSigTimeoutTime_ALL" SG_ 850 ADAS_DOW_state 500;
BA_ "InvalidValue" SG_ 850 ADAS_DOW_state "3h";
BA_ "GenSigTimeoutTime_ALL" SG_ 850 ADAS_DOW_check 500;
BA_ "InvalidValue" SG_ 850 ADAS_DOW_check "3h";
BA_ "GenSigTimeoutTime_ALL" SG_ 850 ADAS_DOW_WarnLeft 500;
BA_ "InvalidValue" SG_ 850 ADAS_DOW_WarnLeft "3h";
BA_ "GenSigStartValue" SG_ 850 ADAS_DOW_Mode_Feed 2;
BA_ "GenSigTimeoutTime_ALL" SG_ 850 ADAS_DOW_Mode_Feed 500;
BA_ "InvalidValue" SG_ 850 ADAS_DOW_Mode_Feed "3h";
BA_ "GenSigTimeoutTime_ALL" SG_ 850 ADAS_AHB_RBPos 500;
BA_ "InvalidValue" SG_ 850 ADAS_AHB_RBPos "7h";
BA_ "GenSigTimeoutTime_ALL" SG_ 850 ADAS_AHB_LBPos 500;
BA_ "InvalidValue" SG_ 850 ADAS_AHB_LBPos "7h";
BA_ "GenSigTimeoutTime_ALL" SG_ 851 CHKSM_ADAS_ACC 500;
BA_ "GenSigTimeoutTime_ALL" SG_ 851 ALV_ADAS_ACC 500;
BA_ "InvalidValue" SG_ 851 ALV_ADAS_ACC "Fh";
BA_ "GenSigTimeoutTime_ALL" SG_ 851 ADAS_ACC_ObjDetec 500;
BA_ "GenSigTimeoutTime_ALL" SG_ 851 ADAS_ISA_check 500;
BA_ "InvalidValue" SG_ 851 ADAS_ISA_check "3h";
BA_ "GenSigTimeoutTime_ALL" SG_ 851 ADAS_ISA_Mode_SW_Feed 500;
BA_ "GenSigTimeoutTime_ALL" SG_ 851 ADAS_TagSpeed_ICON_Feed 500;
BA_ "InvalidValue" SG_ 851 ADAS_TagSpeed_ICON_Feed "7h";
BA_ "GenSigTimeoutTime_ALL" SG_ 851 ADAS_ISA_PopUp_Feed 500;
BA_ "InvalidValue" SG_ 851 ADAS_ISA_PopUp_Feed "Fh";
BA_ "GenSigTimeoutTime_ALL" SG_ 851 ADAS_ISA_Btn_Feed 500;
BA_ "GenSigTimeoutTime_ALL" SG_ 851 ADAS_ACC_DistSet_upper_Feed 500;
BA_ "GenSigTimeoutTime_ALL" SG_ 851 ADAS_ACC_TimeGapSet 500;
BA_ "InvalidValue" SG_ 851 ADAS_ACC_TimeGapSet "7h";
BA_ "GenSigTimeoutTime_ALL" SG_ 851 ADAS_ACC_State 500;
BA_ "GenSigTimeoutTime_ALL" SG_ 851 ADAS_ACC_TagSpeed 500;
BA_ "InvalidValue" SG_ 851 ADAS_ACC_TagSpeed "FFh";
BA_ "GenSigTimeoutTime_ALL" SG_ 851 ADAS_ACC_PopUp_Feed 500;
BA_ "InvalidValue" SG_ 851 ADAS_ACC_PopUp_Feed "Fh";
BA_ "GenSigTimeoutTime_ALL" SG_ 851 ADAS_ACC_check 500;
BA_ "InvalidValue" SG_ 851 ADAS_ACC_check "3h";
BA_ "GenSigTimeoutTime_ALL" SG_ 851 ADAS_ISA_ICON_Feed 500;
BA_ "GenSigTimeoutTime_ALL" SG_ 851 ADAS_ACC_DistSet_lower_Feed 500;
BA_ "GenSigTimeoutTime_ALL" SG_ 851 ADAS_ACC_SpdSet_upper_Feed 500;
BA_ "GenSigTimeoutTime_ALL" SG_ 851 ADAS_ACC_SpdSet_lower_Feed 500;
BA_ "GenSigTimeoutTime_ALL" SG_ 851 ADAS_ACC_On_Feed 500;
BA_ "GenSigTimeoutTime_ALL" SG_ 851 ADAS_ACC_Set_Feed 500;
BA_ "GenSigTimeoutTime_ALL" SG_ 851 ADAS_ACC_CnlBtn_Feed 500;
BA_ "GenSigTimeoutTime_ALL" SG_ 851 ADAS_ACC_Res_Feed 500;
BA_ "GenSigTimeoutTime_ALL" SG_ 851 ADAS_ACC_ICON_Feed 500;
BA_ "InvalidValue" SG_ 851 ADAS_ACC_ICON_Feed "7h";
BA_ "GenSigTimeoutTime_ALL" SG_ 851 ADAS_ISA_Status 500;
BA_ "InvalidValue" SG_ 851 ADAS_ISA_Status "7h";
BA_ "GenSigSendType" SG_ 852 MHU_FCW_Mode 2;
BA_ "GenSigStartValue" SG_ 852 MHU_FCW_Mode 1;
BA_ "InvalidValue" SG_ 852 MHU_FCW_Mode "3h";
BA_ "GenSigSendType" SG_ 852 MHU_FCW_sens 2;
BA_ "GenSigStartValue" SG_ 852 MHU_FCW_sens 1;
BA_ "InvalidValue" SG_ 852 MHU_FCW_sens "3h";
BA_ "GenSigSendType" SG_ 852 MHU_AEB_Mode 2;
BA_ "GenSigStartValue" SG_ 852 MHU_AEB_Mode 1;
BA_ "InvalidValue" SG_ 852 MHU_AEB_Mode "3h";
BA_ "GenSigSendType" SG_ 852 MHU_RAEB_Mode 2;
BA_ "GenSigStartValue" SG_ 852 MHU_RAEB_Mode 1;
BA_ "InvalidValue" SG_ 852 MHU_RAEB_Mode "3h";
BA_ "GenSigSendType" SG_ 852 MHU_LA_sens 2;
BA_ "GenSigStartValue" SG_ 852 MHU_LA_sens 1;
BA_ "InvalidValue" SG_ 852 MHU_LA_sens "3h";
BA_ "GenSigSendType" SG_ 852 MHU_LA_AudWarning 2;
BA_ "InvalidValue" SG_ 852 MHU_LA_AudWarning "3h";
BA_ "GenSigSendType" SG_ 852 MHU_BSD_On 2;
BA_ "GenSigStartValue" SG_ 852 MHU_BSD_On 1;
BA_ "InvalidValue" SG_ 852 MHU_BSD_On "3h";
BA_ "GenSigSendType" SG_ 852 MHU_ALC_ON 2;
BA_ "GenSigStartValue" SG_ 852 MHU_ALC_ON 1;
BA_ "InvalidValue" SG_ 852 MHU_ALC_ON "3h";
BA_ "GenSigSendType" SG_ 852 MHU_BSD_AudWarning 2;
BA_ "InvalidValue" SG_ 852 MHU_BSD_AudWarning "3h";
BA_ "GenSigSendType" SG_ 852 MHU_RCTA_On 2;
BA_ "GenSigStartValue" SG_ 852 MHU_RCTA_On 1;
BA_ "InvalidValue" SG_ 852 MHU_RCTA_On "3h";
BA_ "GenSigSendType" SG_ 852 MHU_RCTA_sens 2;
BA_ "GenSigStartValue" SG_ 852 MHU_RCTA_sens 1;
BA_ "InvalidValue" SG_ 852 MHU_RCTA_sens "3h";
BA_ "GenSigSendType" SG_ 852 MHU_PA_On 2;
BA_ "GenSigStartValue" SG_ 852 MHU_PA_On 1;
BA_ "InvalidValue" SG_ 852 MHU_PA_On "3h";
BA_ "GenSigSendType" SG_ 852 MHU_AHB_On 2;
BA_ "InvalidValue" SG_ 852 MHU_AHB_On "3h";
BA_ "GenSigSendType" SG_ 852 MHU_IA_Mode 2;
BA_ "InvalidValue" SG_ 852 MHU_IA_Mode "3h";
BA_ "GenSigSendType" SG_ 852 MHU_TSR_Mode 2;
BA_ "GenSigStartValue" SG_ 852 MHU_TSR_Mode 1;
BA_ "InvalidValue" SG_ 852 MHU_TSR_Mode "3h";
BA_ "GenSigSendType" SG_ 852 MHU_DOW_Mode 2;
BA_ "GenSigStartValue" SG_ 852 MHU_DOW_Mode 2;
BA_ "InvalidValue" SG_ 852 MHU_DOW_Mode "3h";
BA_ "GenSigSendType" SG_ 852 MHU_AHB_sens 2;
BA_ "GenSigStartValue" SG_ 852 MHU_AHB_sens 1;
BA_ "InvalidValue" SG_ 852 MHU_AHB_sens "3h";
BA_ "GenSigSendType" SG_ 852 MHU_LA_Mode 2;
BA_ "GenSigStartValue" SG_ 852 MHU_LA_Mode 3;
BA_ "InvalidValue" SG_ 852 MHU_LA_Mode "3h";
BA_ "GenSigSendType" SG_ 852 MHU_SET_TSR_AudWarn 2;
BA_ "GenSigStartValue" SG_ 852 MHU_SET_TSR_AudWarn 1;
BA_ "InvalidValue" SG_ 852 MHU_SET_TSR_AudWarn "3h";
BA_ "GenSigSendType" SG_ 852 MHU_SET_TSR_SLAert 2;
BA_ "GenSigStartValue" SG_ 852 MHU_SET_TSR_SLAert 1;
BA_ "InvalidValue" SG_ 852 MHU_SET_TSR_SLAert "3h";
BA_ "GenSigTimeoutTime_ALL" SG_ 853 CHKSM_ADAS_CMP_CHECK 500;
BA_ "GenSigTimeoutTime_ALL" SG_ 853 ALV_ADAS_CMP_CHECK 500;
BA_ "InvalidValue" SG_ 853 ALV_ADAS_CMP_CHECK "Fh";
BA_ "GenSigTimeoutTime_ALL" SG_ 853 ADAS_PAUSS_FaultFLO 500;
BA_ "GenSigTimeoutTime_ALL" SG_ 853 ADAS_PAUSS_FaultFLI 500;
BA_ "GenSigTimeoutTime_ALL" SG_ 853 ADAS_PAUSS_check 500;
BA_ "InvalidValue" SG_ 853 ADAS_PAUSS_check "3h";
BA_ "GenSigTimeoutTime_ALL" SG_ 853 ADAS_PAUSS_FaultRLO 500;
BA_ "GenSigTimeoutTime_ALL" SG_ 853 ADAS_PAUSS_FaultFRI 500;
BA_ "GenSigTimeoutTime_ALL" SG_ 853 ADAS_FPA_check 500;
BA_ "InvalidValue" SG_ 853 ADAS_FPA_check "3h";
BA_ "GenSigTimeoutTime_ALL" SG_ 853 ADAS_PAUSS_FaultRLI 500;
BA_ "GenSigTimeoutTime_ALL" SG_ 853 ADAS_PAUSS_FaultRRO 500;
BA_ "GenSigTimeoutTime_ALL" SG_ 853 ADAS_PAUSS_FaultRRI 500;
BA_ "GenSigTimeoutTime_ALL" SG_ 853 ADAS_RPA_check 500;
BA_ "InvalidValue" SG_ 853 ADAS_RPA_check "3h";
BA_ "GenSigTimeoutTime_ALL" SG_ 853 ADAS_PAUSS_FaultFRO 500;
BA_ "GenSigTimeoutTime_ALL" SG_ 880 CRC_MHU_SBR_Status 1500;
BA_ "GenSigTimeoutTime_ALL" SG_ 880 ALV_MHU_SBR_Status 1500;
BA_ "InvalidValue" SG_ 880 ALV_MHU_SBR_Status "Fh";
BA_ "GenSigStartValue" SG_ 880 SBR_STAT_Chime 3;
BA_ "GenSigTimeoutTime_ALL" SG_ 880 SBR_STAT_Chime 1500;
BA_ "InvalidValue" SG_ 880 SBR_STAT_Chime "3h";
BA_ "GenSigStartValue" SG_ 880 SBR_STAT_Telltale 3;
BA_ "GenSigTimeoutTime_ALL" SG_ 880 SBR_STAT_Telltale 1500;
BA_ "InvalidValue" SG_ 880 SBR_STAT_Telltale "3h";
BA_ "GenSigTimeoutTime_ALL" SG_ 880 SBR_STAT_Active 1500;
BA_ "GenSigTimeoutTime_ALL" SG_ 885 Checksum_0x375 500;
BA_ "InvalidValue" SG_ 885 Checksum_0x375 "null";
BA_ "GenSigTimeoutTime_ALL" SG_ 885 Rolling_Counter_0x375 500;
BA_ "InvalidValue" SG_ 885 Rolling_Counter_0x375 "Fh";
BA_ "GenSigTimeoutTime_ALL" SG_ 885 BMS_PreChgRelay_ERR 500;
BA_ "InvalidValue" SG_ 885 BMS_PreChgRelay_ERR "null";
BA_ "GenSigTimeoutTime_ALL" SG_ 885 BMS_TotalNegRelay_ERR 500;
BA_ "InvalidValue" SG_ 885 BMS_TotalNegRelay_ERR "null";
BA_ "GenSigTimeoutTime_ALL" SG_ 885 BMS_MainPosRelay_ERR 500;
BA_ "InvalidValue" SG_ 885 BMS_MainPosRelay_ERR "null";
BA_ "GenSigTimeoutTime_ALL" SG_ 885 BMS_MainPosRelay_STS 500;
BA_ "InvalidValue" SG_ 885 BMS_MainPosRelay_STS "7h";
BA_ "GenSigTimeoutTime_ALL" SG_ 885 BMS_PreChgRelay_STS 500;
BA_ "InvalidValue" SG_ 885 BMS_PreChgRelay_STS "7h";
BA_ "GenSigTimeoutTime_ALL" SG_ 885 BMS_TotalNegRelay_STS 500;
BA_ "InvalidValue" SG_ 885 BMS_TotalNegRelay_STS "7h";
BA_ "GenSigTimeoutTime_ALL" SG_ 896 VIN_Byte1 5000;
BA_ "InvalidValue" SG_ 896 VIN_Byte1 "null";
BA_ "GenSigTimeoutTime_ALL" SG_ 896 VIN_Byte2 5000;
BA_ "InvalidValue" SG_ 896 VIN_Byte2 "null";
BA_ "GenSigTimeoutTime_ALL" SG_ 896 VIN_Byte3 5000;
BA_ "InvalidValue" SG_ 896 VIN_Byte3 "null";
BA_ "GenSigTimeoutTime_ALL" SG_ 896 VIN_Byte4 5000;
BA_ "InvalidValue" SG_ 896 VIN_Byte4 "null";
BA_ "GenSigTimeoutTime_ALL" SG_ 896 VIN_Byte5 5000;
BA_ "InvalidValue" SG_ 896 VIN_Byte5 "null";
BA_ "GenSigTimeoutTime_ALL" SG_ 896 VIN_Byte6 5000;
BA_ "InvalidValue" SG_ 896 VIN_Byte6 "null";
BA_ "GenSigTimeoutTime_ALL" SG_ 896 VIN_Byte7 5000;
BA_ "InvalidValue" SG_ 896 VIN_Byte7 "null";
BA_ "GenSigTimeoutTime_ALL" SG_ 897 CHKSM_ACM_SEAT_OCCUPATION 1000;
BA_ "InvalidValue" SG_ 897 CHKSM_ACM_SEAT_OCCUPATION "null";
BA_ "GenSigTimeoutTime_ALL" SG_ 897 ALV_ACM_SEAT_OCCUPATION 1000;
BA_ "InvalidValue" SG_ 897 ALV_ACM_SEAT_OCCUPATION "Fh";
BA_ "GenSigTimeoutTime_ALL" SG_ 897 ACM_Seat_Occupancy_Passenger 1000;
BA_ "InvalidValue" SG_ 897 ACM_Seat_Occupancy_Passenger "null";
BA_ "GenSigTimeoutTime_ALL" SG_ 897 ACM_Seat_Occupancy_2nd_Row_Dri 1000;
BA_ "InvalidValue" SG_ 897 ACM_Seat_Occupancy_2nd_Row_Dri "null";
BA_ "GenSigTimeoutTime_ALL" SG_ 897 ACM_Seat_Occupancy_2nd_Row_Pas 1000;
BA_ "InvalidValue" SG_ 897 ACM_Seat_Occupancy_2nd_Row_Pas "null";
BA_ "GenSigTimeoutTime_ALL" SG_ 897 ACM_Seat_Occupancy_2nd_Row_Mid 1000;
BA_ "InvalidValue" SG_ 897 ACM_Seat_Occupancy_2nd_Row_Mid "null";
BA_ "GenSigTimeoutTime_ALL" SG_ 897 ACM_Seat_Belt_Status_Passenger 1000;
BA_ "InvalidValue" SG_ 897 ACM_Seat_Belt_Status_Passenger "null";
BA_ "GenSigTimeoutTime_ALL" SG_ 897 ACM_Seat_Belt_Status_Driver 1000;
BA_ "InvalidValue" SG_ 897 ACM_Seat_Belt_Status_Driver "null";
BA_ "GenSigTimeoutTime_ALL" SG_ 897 ACM_Seat_Belt_Status_2nd_Row_Dri 1000;
BA_ "InvalidValue" SG_ 897 ACM_Seat_Belt_Status_2nd_Row_Dri "null";
BA_ "GenSigTimeoutTime_ALL" SG_ 897 ACM_Seat_Belt_Status_2nd_Row_Mid 1000;
BA_ "InvalidValue" SG_ 897 ACM_Seat_Belt_Status_2nd_Row_Mid "null";
BA_ "GenSigTimeoutTime_ALL" SG_ 897 ACM_Seat_Belt_Status_2nd_Row_Pas 1000;
BA_ "InvalidValue" SG_ 897 ACM_Seat_Belt_Status_2nd_Row_Pas "null";
BA_ "GenSigSendType" SG_ 905 VCU_IMMO_Sts 1;
BA_ "InvalidValue" SG_ 905 VCU_IMMO_Sts "";
BA_ "GenSigSendType" SG_ 905 SECCAN_VCU_IMMO_Sts 1;
BA_ "InvalidValue" SG_ 905 SECCAN_VCU_IMMO_Sts "";
BA_ "GenSigSendType" SG_ 915 MHU_SET_HudRotateLvl 2;
BA_ "InvalidValue" SG_ 915 MHU_SET_HudRotateLvl "Fh";
BA_ "GenSigSendType" SG_ 915 MHU_SET_HudHeightLvl 2;
BA_ "InvalidValue" SG_ 915 MHU_SET_HudHeightLvl "0h";
BA_ "GenSigSendType" SG_ 919 MHU_Immo_ADAS_Byte_0 2;
BA_ "GenSigSendType" SG_ 919 MHU_Immo_ADAS_Byte_1 2;
BA_ "GenSigSendType" SG_ 919 MHU_Immo_ADAS_Byte_2 2;
BA_ "GenSigSendType" SG_ 919 MHU_Immo_ADAS_Byte_3 2;
BA_ "GenSigSendType" SG_ 919 MHU_Immo_ADAS_Byte_4 2;
BA_ "GenSigSendType" SG_ 919 MHU_Immo_ADAS_Byte_5 2;
BA_ "GenSigSendType" SG_ 919 MHU_Immo_ADAS_Byte_6 2;
BA_ "GenSigSendType" SG_ 919 MHU_Immo_ADAS_Byte_7 2;
BA_ "GenSigSendType" SG_ 922 MHU_Immo_Byte_0 2;
BA_ "InvalidValue" SG_ 922 MHU_Immo_Byte_0 "null";
BA_ "GenSigSendType" SG_ 922 MHU_Immo_Byte_1 2;
BA_ "InvalidValue" SG_ 922 MHU_Immo_Byte_1 "null";
BA_ "GenSigSendType" SG_ 922 MHU_Immo_Byte_2 2;
BA_ "InvalidValue" SG_ 922 MHU_Immo_Byte_2 "null";
BA_ "GenSigSendType" SG_ 922 MHU_Immo_Byte_3 2;
BA_ "InvalidValue" SG_ 922 MHU_Immo_Byte_3 "null";
BA_ "GenSigSendType" SG_ 922 MHU_Immo_Byte_4 2;
BA_ "InvalidValue" SG_ 922 MHU_Immo_Byte_4 "null";
BA_ "GenSigSendType" SG_ 922 MHU_Immo_Byte_5 2;
BA_ "InvalidValue" SG_ 922 MHU_Immo_Byte_5 "null";
BA_ "GenSigSendType" SG_ 922 MHU_Immo_Byte_6 2;
BA_ "InvalidValue" SG_ 922 MHU_Immo_Byte_6 "null";
BA_ "GenSigSendType" SG_ 922 MHU_Immo_Byte_7 2;
BA_ "InvalidValue" SG_ 922 MHU_Immo_Byte_7 "null";
BA_ "GenSigSendType" SG_ 923 BCM_Immo_MHU_Byte_0 2;
BA_ "InvalidValue" SG_ 923 BCM_Immo_MHU_Byte_0 "null";
BA_ "GenSigSendType" SG_ 923 BCM_Immo_MHU_Byte_1 2;
BA_ "InvalidValue" SG_ 923 BCM_Immo_MHU_Byte_1 "null";
BA_ "GenSigSendType" SG_ 923 BCM_Immo_MHU_Byte_2 2;
BA_ "InvalidValue" SG_ 923 BCM_Immo_MHU_Byte_2 "null";
BA_ "GenSigSendType" SG_ 923 BCM_Immo_MHU_Byte_3 2;
BA_ "InvalidValue" SG_ 923 BCM_Immo_MHU_Byte_3 "null";
BA_ "GenSigSendType" SG_ 923 BCM_Immo_MHU_Byte_4 2;
BA_ "InvalidValue" SG_ 923 BCM_Immo_MHU_Byte_4 "null";
BA_ "GenSigSendType" SG_ 923 BCM_Immo_MHU_Byte_5 2;
BA_ "InvalidValue" SG_ 923 BCM_Immo_MHU_Byte_5 "null";
BA_ "GenSigSendType" SG_ 923 BCM_Immo_MHU_Byte_6 2;
BA_ "InvalidValue" SG_ 923 BCM_Immo_MHU_Byte_6 "null";
BA_ "GenSigSendType" SG_ 923 BCM_Immo_MHU_Byte_7 2;
BA_ "InvalidValue" SG_ 923 BCM_Immo_MHU_Byte_7 "null";
BA_ "GenSigTimeoutTime_ALL" SG_ 925 BCM_AHB_Override 500;
BA_ "InvalidValue" SG_ 925 BCM_AHB_Override "3h";
BA_ "GenSigSendType" SG_ 943 MHU_UTF8Character_Byte1 1;
BA_ "InvalidValue" SG_ 943 MHU_UTF8Character_Byte1 "FFh";
BA_ "GenSigSendType" SG_ 943 MHU_UTF8Character_Byte2 1;
BA_ "InvalidValue" SG_ 943 MHU_UTF8Character_Byte2 "FFh";
BA_ "GenSigSendType" SG_ 943 MHU_UTF8Character_Byte3 1;
BA_ "InvalidValue" SG_ 943 MHU_UTF8Character_Byte3 "FFh";
BA_ "GenSigSendType" SG_ 943 MHU_UTF8Character_Byte4 1;
BA_ "InvalidValue" SG_ 943 MHU_UTF8Character_Byte4 "FFh";
BA_ "GenSigSendType" SG_ 943 MHU_UTF8Character_Byte5 1;
BA_ "InvalidValue" SG_ 943 MHU_UTF8Character_Byte5 "FFh";
BA_ "GenSigSendType" SG_ 943 MHU_UTF8Character_Byte6 1;
BA_ "InvalidValue" SG_ 943 MHU_UTF8Character_Byte6 "FFh";
BA_ "GenSigSendType" SG_ 943 MHU_IPC_ID 1;
BA_ "InvalidValue" SG_ 943 MHU_IPC_ID "Fh";
BA_ "GenSigSendType" SG_ 943 MHU_TotalMessages 1;
BA_ "GenSigStartValue" SG_ 943 MHU_TotalMessages 1;
BA_ "InvalidValue" SG_ 943 MHU_TotalMessages "Fh";
BA_ "GenSigSendType" SG_ 943 MHU_MessageNumber 1;
BA_ "GenSigStartValue" SG_ 943 MHU_MessageNumber 1;
BA_ "InvalidValue" SG_ 943 MHU_MessageNumber "Fh";
BA_ "GenSigSendType" SG_ 964 MHU_Nav_State 1;
BA_ "InvalidValue" SG_ 964 MHU_Nav_State "7h";
BA_ "GenSigSendType" SG_ 964 MHU_NavSource 1;
BA_ "InvalidValue" SG_ 964 MHU_NavSource "7h";
BA_ "GenSigSendType" SG_ 964 MHU_Nav_DistanceToNextTurn 1;
BA_ "GenSigSendType" SG_ 964 MHU_Nav_DistanceToNextTurnUnits 1;
BA_ "GenSigSendType" SG_ 964 MHU_Nav_TBT_Icon 1;
BA_ "GenSigSendType" SG_ 964 MHU_Nav_ImageChannel_Ready 1;
BA_ "GenSigSendType" SG_ 964 MHU_Nav_Language 1;
BA_ "InvalidValue" SG_ 964 MHU_Nav_Language "FFh";
BA_ "GenSigSendType" SG_ 964 SECCAN_NAV_DISP 1;
BA_ "GenSigSendType" SG_ 965 MHU_NavGuidance_TotalMsg 1;
BA_ "GenSigSendType" SG_ 965 MHU_NavGuidance_MsgNum 1;
BA_ "GenSigSendType" SG_ 965 MHU_NavGuidance_UTF8_Byte1 1;
BA_ "GenSigSendType" SG_ 965 MHU_NavGuidance_UTF8_Byte2 1;
BA_ "GenSigSendType" SG_ 965 MHU_NavGuidance_UTF8_Byte3 1;
BA_ "GenSigSendType" SG_ 965 MHU_NavGuidance_UTF8_Byte4 1;
BA_ "GenSigSendType" SG_ 965 MHU_NavGuidance_UTF8_Byte5 1;
BA_ "GenSigSendType" SG_ 965 MHU_NavGuidance_UTF8_Byte6 1;
BA_ "GenSigSendType" SG_ 966 MHU_NavDist_MsgNum 1;
BA_ "GenSigSendType" SG_ 966 MHU_NavDist_TotalMsg 1;
BA_ "GenSigSendType" SG_ 966 MHU_NavDist_UTF8_Byte1 1;
BA_ "GenSigSendType" SG_ 966 MHU_NavDist_UTF8_Byte2 1;
BA_ "GenSigSendType" SG_ 966 MHU_NavDist_UTF8_Byte3 1;
BA_ "GenSigSendType" SG_ 966 MHU_NavDist_UTF8_Byte4 1;
BA_ "GenSigSendType" SG_ 966 MHU_NavDist_UTF8_Byte5 1;
BA_ "GenSigSendType" SG_ 966 MHU_NavDist_UTF8_Byte6 1;
BA_ "GenSigTimeoutTime_ALL" SG_ 992 CRC_VCU_HVsystem_status 200;
BA_ "GenSigTimeoutTime_ALL" SG_ 992 CRC_VCU_HVsystem_status 200;
BA_ "InvalidValue" SG_ 992 CRC_VCU_HVsystem_status "null";
BA_ "GenSigTimeoutTime_ALL" SG_ 992 ALIV_VCU_HVsystem_status 200;
BA_ "GenSigTimeoutTime_ALL" SG_ 992 ALIV_VCU_HVsystem_status 200;
BA_ "InvalidValue" SG_ 992 ALIV_VCU_HVsystem_status "Fh";
BA_ "GenSigTimeoutTime_ALL" SG_ 992 VCU_RunningRange 200;
BA_ "GenSigTimeoutTime_ALL" SG_ 992 VCU_RunningRange 200;
BA_ "InvalidValue" SG_ 992 VCU_RunningRange "null";
BA_ "GenSigTimeoutTime_ALL" SG_ 992 VCU_RunningRange_chrg_estSts 200;
BA_ "GenSigTimeoutTime_ALL" SG_ 992 VCU_RunningRange_chrg_estSts 200;
BA_ "InvalidValue" SG_ 992 VCU_RunningRange_chrg_estSts "null";
BA_ "GenSigTimeoutTime_ALL" SG_ 992 VCU_RunningRange_charged 200;
BA_ "GenSigTimeoutTime_ALL" SG_ 992 VCU_RunningRange_charged 200;
BA_ "InvalidValue" SG_ 992 VCU_RunningRange_charged "null";
BA_ "GenSigTimeoutTime_ALL" SG_ 992 VCU_HVbatSoc_charged 200;
BA_ "GenSigTimeoutTime_ALL" SG_ 992 VCU_HVbatSoc_charged 200;
BA_ "InvalidValue" SG_ 992 VCU_HVbatSoc_charged "null";
BA_ "GenSigTimeoutTime_ALL" SG_ 992 VCU_HVbatSoc_charged_estStatus 200;
BA_ "GenSigTimeoutTime_ALL" SG_ 992 VCU_HVbatSoc_charged_estStatus 200;
BA_ "InvalidValue" SG_ 992 VCU_HVbatSoc_charged_estStatus "null";
BA_ "GenSigTimeoutTime_ALL" SG_ 993 CRC_VCU_HMI_Info 500;
BA_ "GenSigTimeoutTime_ALL" SG_ 993 CRC_VCU_HMI_Info 500;
BA_ "InvalidValue" SG_ 993 CRC_VCU_HMI_Info "null";
BA_ "GenSigTimeoutTime_ALL" SG_ 993 ALIV_VCU_HMI_Info 500;
BA_ "GenSigTimeoutTime_ALL" SG_ 993 ALIV_VCU_HMI_Info 500;
BA_ "InvalidValue" SG_ 993 ALIV_VCU_HMI_Info "Fh";
BA_ "GenSigStartValue" SG_ 993 VCU_MHU_Ack_ChgSche_stt 3;
BA_ "GenSigTimeoutTime_ALL" SG_ 993 VCU_MHU_Ack_ChgSche_stt 500;
BA_ "InvalidValue" SG_ 993 VCU_MHU_Ack_ChgSche_stt "3h";
BA_ "GenSigStartValue" SG_ 993 VCU_MHU_Ack_TargetSOC 100;
BA_ "GenSigTimeoutTime_ALL" SG_ 993 VCU_MHU_Ack_TargetSOC 500;
BA_ "GenSigTimeoutTime_ALL" SG_ 993 VCU_MHU_Ack_TargetSOC 500;
BA_ "InvalidValue" SG_ 993 VCU_MHU_Ack_TargetSOC "7Fh";
BA_ "GenSigTimeoutTime_ALL" SG_ 993 VCU_ValetMode_sts 500;
BA_ "InvalidValue" SG_ 993 VCU_ValetMode_sts "FFh";
BA_ "GenSigTimeoutTime_ALL" SG_ 993 VCU_ValetMode_MaxSpeedSts 500;
BA_ "InvalidValue" SG_ 993 VCU_ValetMode_MaxSpeedSts "FFh";
BA_ "GenSigTimeoutTime_ALL" SG_ 993 SECCAN_VCU_HMI_Info 500;
BA_ "InvalidValue" SG_ 993 SECCAN_VCU_HMI_Info "null";
BA_ "GenSigSendType" SG_ 1015 CHSKM_MFS_Control_Button 4;
BA_ "GenSigTimeoutTime_ALL" SG_ 1015 CHSKM_MFS_Control_Button 5000;
BA_ "InvalidValue" SG_ 1015 CHSKM_MFS_Control_Button "null";
BA_ "GenSigSendType" SG_ 1015 ALV_MFS_Control_Button 4;
BA_ "GenSigTimeoutTime_ALL" SG_ 1015 ALV_MFS_Control_Button 5000;
BA_ "InvalidValue" SG_ 1015 ALV_MFS_Control_Button "Fh";
BA_ "GenSigSendType" SG_ 1015 MFS_VoiceRecognitionOn_Off 4;
BA_ "GenSigTimeoutTime_ALL" SG_ 1015 MFS_VoiceRecognitionOn_Off 5000;
BA_ "InvalidValue" SG_ 1015 MFS_VoiceRecognitionOn_Off "null";
BA_ "GenSigSendType" SG_ 1015 MFS_ISAControl 4;
BA_ "GenSigTimeoutTime_ALL" SG_ 1015 MFS_ISAControl 5000;
BA_ "InvalidValue" SG_ 1015 MFS_ISAControl "null";
BA_ "GenSigSendType" SG_ 1015 MFS_CruiseSpeedIncrease 4;
BA_ "GenSigTimeoutTime_ALL" SG_ 1015 MFS_CruiseSpeedIncrease 5000;
BA_ "InvalidValue" SG_ 1015 MFS_CruiseSpeedIncrease "null";
BA_ "GenSigSendType" SG_ 1015 MFS_TelephoneCall_EndCall 4;
BA_ "GenSigTimeoutTime_ALL" SG_ 1015 MFS_TelephoneCall_EndCall 5000;
BA_ "InvalidValue" SG_ 1015 MFS_TelephoneCall_EndCall "null";
BA_ "GenSigSendType" SG_ 1015 MFS_LKAControl 4;
BA_ "GenSigTimeoutTime_ALL" SG_ 1015 MFS_LKAControl 5000;
BA_ "InvalidValue" SG_ 1015 MFS_LKAControl "null";
BA_ "GenSigSendType" SG_ 1015 MFS_CruiseGapIncrease 4;
BA_ "GenSigTimeoutTime_ALL" SG_ 1015 MFS_CruiseGapIncrease 5000;
BA_ "InvalidValue" SG_ 1015 MFS_CruiseGapIncrease "null";
BA_ "GenSigSendType" SG_ 1015 MFS_CruiseOn_Off 4;
BA_ "GenSigTimeoutTime_ALL" SG_ 1015 MFS_CruiseOn_Off 5000;
BA_ "InvalidValue" SG_ 1015 MFS_CruiseOn_Off "null";
BA_ "GenSigSendType" SG_ 1015 MFS_CruiseGapDecrease 4;
BA_ "GenSigTimeoutTime_ALL" SG_ 1015 MFS_CruiseGapDecrease 5000;
BA_ "InvalidValue" SG_ 1015 MFS_CruiseGapDecrease "null";
BA_ "GenSigSendType" SG_ 1015 MFS_CAN_RESControl 4;
BA_ "GenSigTimeoutTime_ALL" SG_ 1015 MFS_CAN_RESControl 5000;
BA_ "InvalidValue" SG_ 1015 MFS_CAN_RESControl "3h";
BA_ "GenSigSendType" SG_ 1015 MFS_CruiseSpeedDecrease 4;
BA_ "GenSigTimeoutTime_ALL" SG_ 1015 MFS_CruiseSpeedDecrease 5000;
BA_ "InvalidValue" SG_ 1015 MFS_CruiseSpeedDecrease "null";
BA_ "GenSigSendType" SG_ 1015 MFS_M2Control 4;
BA_ "GenSigTimeoutTime_ALL" SG_ 1015 MFS_M2Control 5000;
BA_ "InvalidValue" SG_ 1015 MFS_M2Control "null";
BA_ "GenSigSendType" SG_ 1015 MFS_SourseControl 4;
BA_ "GenSigTimeoutTime_ALL" SG_ 1015 MFS_SourseControl 5000;
BA_ "InvalidValue" SG_ 1015 MFS_SourseControl "null";
BA_ "GenSigSendType" SG_ 1015 MFS_UpControl 4;
BA_ "GenSigTimeoutTime_ALL" SG_ 1015 MFS_UpControl 5000;
BA_ "InvalidValue" SG_ 1015 MFS_UpControl "null";
BA_ "GenSigSendType" SG_ 1015 MFS_DownControl 4;
BA_ "GenSigTimeoutTime_ALL" SG_ 1015 MFS_DownControl 5000;
BA_ "InvalidValue" SG_ 1015 MFS_DownControl "null";
BA_ "GenSigSendType" SG_ 1015 MFS_LeftControl 4;
BA_ "GenSigTimeoutTime_ALL" SG_ 1015 MFS_LeftControl 5000;
BA_ "InvalidValue" SG_ 1015 MFS_LeftControl "null";
BA_ "GenSigSendType" SG_ 1015 MFS_Failure 4;
BA_ "GenSigTimeoutTime_ALL" SG_ 1015 MFS_Failure 5000;
BA_ "InvalidValue" SG_ 1015 MFS_Failure "null";
BA_ "GenSigSendType" SG_ 1015 MFS_RightControl 4;
BA_ "GenSigTimeoutTime_ALL" SG_ 1015 MFS_RightControl 5000;
BA_ "InvalidValue" SG_ 1015 MFS_RightControl "null";
BA_ "GenSigSendType" SG_ 1015 MFS_OK_Control 4;
BA_ "GenSigTimeoutTime_ALL" SG_ 1015 MFS_OK_Control 5000;
BA_ "InvalidValue" SG_ 1015 MFS_OK_Control "null";
BA_ "GenSigTimeoutTime_ALL" SG_ 1020 CRC_XGW_FOTA_StsConfirm 2500;
BA_ "GenSigTimeoutTime_ALL" SG_ 1020 ALIV_XGW_FOTA_StsConfirm 2500;
BA_ "InvalidValue" SG_ 1020 ALIV_XGW_FOTA_StsConfirm "Fh";
BA_ "GenSigTimeoutTime_ALL" SG_ 1020 XGW_FOTA_StateConfirm 2500;
BA_ "GenSigTimeoutTime_ALL" SG_ 1020 XGW_FOTA_Error_Code 2500;
BA_ "GenSigSendType" SG_ 1025 MHU_SET_SunroofGlassLevel 2;
BA_ "GenSigStartValue" SG_ 1025 MHU_SET_SunroofGlassLevel 255;
BA_ "InvalidValue" SG_ 1025 MHU_SET_SunroofGlassLevel "7Fh";
BA_ "GenSigSendType" SG_ 1025 MHU_SET_BonnetState 2;
BA_ "InvalidValue" SG_ 1025 MHU_SET_BonnetState "3h";
BA_ "GenSigSendType" SG_ 1025 MHU_SET_TrunkState 2;
BA_ "InvalidValue" SG_ 1025 MHU_SET_TrunkState "3h";
BA_ "GenSigSendType" SG_ 1025 MHU_SET_SunroofShaderLevel 2;
BA_ "GenSigStartValue" SG_ 1025 MHU_SET_SunroofShaderLevel 255;
BA_ "InvalidValue" SG_ 1025 MHU_SET_SunroofShaderLevel "7Fh";
BA_ "GenSigSendType" SG_ 1025 MHU_SET_DoorSpeedLock 2;
BA_ "GenSigStartValue" SG_ 1025 MHU_SET_DoorSpeedLock 6;
BA_ "InvalidValue" SG_ 1025 MHU_SET_DoorSpeedLock "6h";
BA_ "GenSigSendType" SG_ 1025 MHU_SET_WelcomeTriggerCondition 2;
BA_ "GenSigStartValue" SG_ 1025 MHU_SET_WelcomeTriggerCondition 3;
BA_ "InvalidValue" SG_ 1025 MHU_SET_WelcomeTriggerCondition "3h";
BA_ "GenSigSendType" SG_ 1025 MHU_SET_AutoSunroof 2;
BA_ "GenSigStartValue" SG_ 1025 MHU_SET_AutoSunroof 3;
BA_ "InvalidValue" SG_ 1025 MHU_SET_AutoSunroof "3h";
BA_ "GenSigSendType" SG_ 1025 MHU_SET_RemoteDoorUnlock 2;
BA_ "GenSigStartValue" SG_ 1025 MHU_SET_RemoteDoorUnlock 3;
BA_ "InvalidValue" SG_ 1025 MHU_SET_RemoteDoorUnlock "3h";
BA_ "GenSigSendType" SG_ 1025 MHU_SET_RemoteLockFeedback 2;
BA_ "GenSigStartValue" SG_ 1025 MHU_SET_RemoteLockFeedback 4;
BA_ "InvalidValue" SG_ 1025 MHU_SET_RemoteLockFeedback "4h";
BA_ "GenSigSendType" SG_ 1025 MHU_SET_FootkickSensor 2;
BA_ "GenSigStartValue" SG_ 1025 MHU_SET_FootkickSensor 3;
BA_ "InvalidValue" SG_ 1025 MHU_SET_FootkickSensor "3h";
BA_ "GenSigSendType" SG_ 1025 MHU_SET_AutoUnlockDoor 2;
BA_ "GenSigStartValue" SG_ 1025 MHU_SET_AutoUnlockDoor 3;
BA_ "InvalidValue" SG_ 1025 MHU_SET_AutoUnlockDoor "3h";
BA_ "GenSigSendType" SG_ 1025 MHU_SET_RemoteUnlockFeedback 2;
BA_ "GenSigStartValue" SG_ 1025 MHU_SET_RemoteUnlockFeedback 4;
BA_ "InvalidValue" SG_ 1025 MHU_SET_RemoteUnlockFeedback "4h";
BA_ "GenSigSendType" SG_ 1025 MHU_SET_Childlock 2;
BA_ "InvalidValue" SG_ 1025 MHU_SET_Childlock "null";
BA_ "GenSigSendType" SG_ 1025 MHU_SET_SunroofInitialize 2;
BA_ "InvalidValue" SG_ 1025 MHU_SET_SunroofInitialize "7h";
BA_ "GenSigSendType" SG_ 1026 MHU_SET_DayTimeRunningLight 2;
BA_ "GenSigStartValue" SG_ 1026 MHU_SET_DayTimeRunningLight 1;
BA_ "InvalidValue" SG_ 1026 MHU_SET_DayTimeRunningLight "3h";
BA_ "GenSigSendType" SG_ 1026 MHU_SET_RearFogLight 2;
BA_ "GenSigStartValue" SG_ 1026 MHU_SET_RearFogLight 3;
BA_ "InvalidValue" SG_ 1026 MHU_SET_RearFogLight "3h";
BA_ "GenSigSendType" SG_ 1026 MHU_SET_FrontFogLight 2;
BA_ "GenSigStartValue" SG_ 1026 MHU_SET_FrontFogLight 3;
BA_ "InvalidValue" SG_ 1026 MHU_SET_FrontFogLight "3h";
BA_ "GenSigSendType" SG_ 1026 MHU_SET_WelcomeDimmingHeadlight 2;
BA_ "GenSigStartValue" SG_ 1026 MHU_SET_WelcomeDimmingHeadlight 3;
BA_ "InvalidValue" SG_ 1026 MHU_SET_WelcomeDimmingHeadlight "3h";
BA_ "GenSigSendType" SG_ 1026 MHU_SET_AmbientLightBrighness 2;
BA_ "InvalidValue" SG_ 1026 MHU_SET_AmbientLightBrighness "7Fh";
BA_ "GenSigSendType" SG_ 1026 MHU_SET_FootwellLightMode 2;
BA_ "GenSigStartValue" SG_ 1026 MHU_SET_FootwellLightMode 3;
BA_ "InvalidValue" SG_ 1026 MHU_SET_FootwellLightMode "3h";
BA_ "GenSigSendType" SG_ 1026 MHU_SET_ExteriorLight 2;
BA_ "GenSigStartValue" SG_ 1026 MHU_SET_ExteriorLight 4;
BA_ "InvalidValue" SG_ 1026 MHU_SET_ExteriorLight "4h";
BA_ "GenSigSendType" SG_ 1026 MHU_SET_TRWarningSignals 2;
BA_ "InvalidValue" SG_ 1026 MHU_SET_TRWarningSignals "3h";
BA_ "GenSigSendType" SG_ 1026 MHU_SET_FrontDomeLamp 2;
BA_ "GenSigStartValue" SG_ 1026 MHU_SET_FrontDomeLamp 3;
BA_ "InvalidValue" SG_ 1026 MHU_SET_FrontDomeLamp "3h";
BA_ "GenSigSendType" SG_ 1026 MHU_SET_SwitchLightBrightness 2;
BA_ "GenSigStartValue" SG_ 1026 MHU_SET_SwitchLightBrightness 80;
BA_ "InvalidValue" SG_ 1026 MHU_SET_SwitchLightBrightness "4h";
BA_ "GenSigSendType" SG_ 1026 MHU_SET_FollowMeHome 2;
BA_ "InvalidValue" SG_ 1026 MHU_SET_FollowMeHome "5h";
BA_ "GenSigSendType" SG_ 1026 MHU_SET_ADB_AHB 2;
BA_ "InvalidValue" SG_ 1026 MHU_SET_ADB_AHB "3h";
BA_ "GenSigSendType" SG_ 1026 MHU_SET_WelcomeAnimation 2;
BA_ "InvalidValue" SG_ 1026 MHU_SET_WelcomeAnimation "null";
BA_ "GenSigSendType" SG_ 1026 MHU_SET_ChargingAnimation 2;
BA_ "GenSigStartValue" SG_ 1026 MHU_SET_ChargingAnimation 1;
BA_ "InvalidValue" SG_ 1026 MHU_SET_ChargingAnimation "null";
BA_ "GenSigSendType" SG_ 1026 MHU_SET_Auto_Leveling 2;
BA_ "GenSigStartValue" SG_ 1026 MHU_SET_Auto_Leveling 3;
BA_ "InvalidValue" SG_ 1026 MHU_SET_Auto_Leveling "3h";
BA_ "GenSigTimeoutTime_ALL" SG_ 1027 CHKSM_MHU_EVSetting 500;
BA_ "InvalidValue" SG_ 1027 CHKSM_MHU_EVSetting "null";
BA_ "GenSigTimeoutTime_ALL" SG_ 1027 ALV_MHU_EVSetting 500;
BA_ "InvalidValue" SG_ 1027 ALV_MHU_EVSetting "Fh";
BA_ "GenSigTimeoutTime_ALL" SG_ 1027 MHU_VCU_CreepDisable_stt 500;
BA_ "InvalidValue" SG_ 1027 MHU_VCU_CreepDisable_stt "null";
BA_ "GenSigTimeoutTime_ALL" SG_ 1027 MHU_BrakeRegenMode 500;
BA_ "InvalidValue" SG_ 1027 MHU_BrakeRegenMode "3h";
BA_ "GenSigStartValue" SG_ 1027 MHU_ChargeSetTargetSOC 90;
BA_ "GenSigTimeoutTime_ALL" SG_ 1027 MHU_ChargeSetTargetSOC 500;
BA_ "InvalidValue" SG_ 1027 MHU_ChargeSetTargetSOC "7Fh";
BA_ "GenSigStartValue" SG_ 1027 MHU_ChargeScheduleSet 2;
BA_ "GenSigTimeoutTime_ALL" SG_ 1027 MHU_ChargeScheduleSet 500;
BA_ "InvalidValue" SG_ 1027 MHU_ChargeScheduleSet "3h";
BA_ "GenSigStartValue" SG_ 1027 MHU_ChargingRequest 3;
BA_ "GenSigTimeoutTime_ALL" SG_ 1027 MHU_ChargingRequest 500;
BA_ "InvalidValue" SG_ 1027 MHU_ChargingRequest "null";
BA_ "GenSigTimeoutTime_ALL" SG_ 1027 MHU_ChgPort_Open_req 500;
BA_ "InvalidValue" SG_ 1027 MHU_ChgPort_Open_req "3h";
BA_ "GenSigStartValue" SG_ 1027 MHU_SET_DrivingModeSwitch 3;
BA_ "GenSigTimeoutTime_ALL" SG_ 1027 MHU_SET_DrivingModeSwitch 500;
BA_ "InvalidValue" SG_ 1027 MHU_SET_DrivingModeSwitch "3h";
BA_ "GenSigStartValue" SG_ 1027 MHU_ValetMode_Activation 2;
BA_ "GenSigTimeoutTime_ALL" SG_ 1027 MHU_ValetMode_Activation 500;
BA_ "InvalidValue" SG_ 1027 MHU_ValetMode_Activation "FFh";
BA_ "GenSigStartValue" SG_ 1027 MHU_ValetMode_MaxSpeed 255;
BA_ "GenSigTimeoutTime_ALL" SG_ 1027 MHU_ValetMode_MaxSpeed 500;
BA_ "InvalidValue" SG_ 1027 MHU_ValetMode_MaxSpeed "FFh";
BA_ "GenSigTimeoutTime_ALL" SG_ 1027 MHU_ChargingCurrentLimit 500;
BA_ "InvalidValue" SG_ 1027 MHU_ChargingCurrentLimit "3Fh";
BA_ "GenSigSendType" SG_ 1028 MHU_SET_LeftMirrorPosX 2;
BA_ "GenSigStartValue" SG_ 1028 MHU_SET_LeftMirrorPosX 15;
BA_ "InvalidValue" SG_ 1028 MHU_SET_LeftMirrorPosX "FFh";
BA_ "GenSigSendType" SG_ 1028 MHU_SET_LeftMirrorPosY 2;
BA_ "GenSigStartValue" SG_ 1028 MHU_SET_LeftMirrorPosY 15;
BA_ "InvalidValue" SG_ 1028 MHU_SET_LeftMirrorPosY "FFh";
BA_ "GenSigSendType" SG_ 1028 MHU_SET_RightMirrorPosX 2;
BA_ "GenSigStartValue" SG_ 1028 MHU_SET_RightMirrorPosX 15;
BA_ "InvalidValue" SG_ 1028 MHU_SET_RightMirrorPosX "FFh";
BA_ "GenSigSendType" SG_ 1028 MHU_SET_RightMirrorPosY 2;
BA_ "GenSigStartValue" SG_ 1028 MHU_SET_RightMirrorPosY 15;
BA_ "InvalidValue" SG_ 1028 MHU_SET_RightMirrorPosY "FFh";
BA_ "GenSigSendType" SG_ 1028 MHU_SET_MirrorAdjustLeft 2;
BA_ "InvalidValue" SG_ 1028 MHU_SET_MirrorAdjustLeft "3h";
BA_ "GenSigSendType" SG_ 1028 MHU_SET_MirrorAdjustRight 2;
BA_ "InvalidValue" SG_ 1028 MHU_SET_MirrorAdjustRight "3h";
BA_ "GenSigSendType" SG_ 1028 MHU_SET_MirrorManual 2;
BA_ "GenSigStartValue" SG_ 1028 MHU_SET_MirrorManual 3;
BA_ "InvalidValue" SG_ 1028 MHU_SET_MirrorManual "3h";
BA_ "GenSigSendType" SG_ 1028 SECCAN_MirrorAdj 2;
BA_ "InvalidValue" SG_ 1028 SECCAN_MirrorAdj "null";
BA_ "GenSigSendType" SG_ 1029 MHU_SET_CCUF_AirCondition 2;
BA_ "InvalidValue" SG_ 1029 MHU_SET_CCUF_AirCondition "3h";
BA_ "GenSigSendType" SG_ 1029 MHU_SET_CCUF_AutoAC 2;
BA_ "InvalidValue" SG_ 1029 MHU_SET_CCUF_AutoAC "3h";
BA_ "GenSigSendType" SG_ 1029 MHU_SET_CCUF_MaxAc 2;
BA_ "InvalidValue" SG_ 1029 MHU_SET_CCUF_MaxAc "3h";
BA_ "GenSigSendType" SG_ 1029 MHU_SET_CCUF_FanSpeed 2;
BA_ "GenSigStartValue" SG_ 1029 MHU_SET_CCUF_FanSpeed 3;
BA_ "InvalidValue" SG_ 1029 MHU_SET_CCUF_FanSpeed "7h";
BA_ "GenSigSendType" SG_ 1029 MHU_SET_CCUF_Recirculation 2;
BA_ "GenSigStartValue" SG_ 1029 MHU_SET_CCUF_Recirculation 1;
BA_ "InvalidValue" SG_ 1029 MHU_SET_CCUF_Recirculation "3h";
BA_ "GenSigSendType" SG_ 1029 MHU_SET_CCUF_Ion 2;
BA_ "InvalidValue" SG_ 1029 MHU_SET_CCUF_Ion "3h";
BA_ "GenSigSendType" SG_ 1029 MHU_SET_CCUF_FlapPosition 2;
BA_ "InvalidValue" SG_ 1029 MHU_SET_CCUF_FlapPosition "4h";
BA_ "GenSigSendType" SG_ 1029 MHU_SET_CCUF_SyncClimateZone 2;
BA_ "InvalidValue" SG_ 1029 MHU_SET_CCUF_SyncClimateZone "3h";
BA_ "GenSigSendType" SG_ 1029 MHU_SET_CCUF_TempDriver 2;
BA_ "GenSigStartValue" SG_ 1029 MHU_SET_CCUF_TempDriver 40;
BA_ "InvalidValue" SG_ 1029 MHU_SET_CCUF_TempDriver "FFh";
BA_ "GenSigSendType" SG_ 1029 MHU_SET_CCUF_TempPassenger 2;
BA_ "GenSigStartValue" SG_ 1029 MHU_SET_CCUF_TempPassenger 40;
BA_ "InvalidValue" SG_ 1029 MHU_SET_CCUF_TempPassenger "FFh";
BA_ "GenSigSendType" SG_ 1029 MHU_SET_CCUF_FrontDefrost 2;
BA_ "InvalidValue" SG_ 1029 MHU_SET_CCUF_FrontDefrost "3h";
BA_ "GenSigSendType" SG_ 1030 MHU_SET_SeatHeatingFrontL 2;
BA_ "InvalidValue" SG_ 1030 MHU_SET_SeatHeatingFrontL "4h";
BA_ "GenSigSendType" SG_ 1030 MHU_SET_SeatHeatingFrontR 2;
BA_ "InvalidValue" SG_ 1030 MHU_SET_SeatHeatingFrontR "4h";
BA_ "GenSigSendType" SG_ 1030 MHU_SET_SeatHeatingReartL 2;
BA_ "InvalidValue" SG_ 1030 MHU_SET_SeatHeatingReartL "4h";
BA_ "GenSigSendType" SG_ 1030 MHU_SET_SeatHeatingRearR 2;
BA_ "InvalidValue" SG_ 1030 MHU_SET_SeatHeatingRearR "4h";
BA_ "GenSigSendType" SG_ 1030 MHU_SET_SeatCoolingFrontL 2;
BA_ "InvalidValue" SG_ 1030 MHU_SET_SeatCoolingFrontL "4h";
BA_ "GenSigSendType" SG_ 1030 MHU_SET_SeatCoolingFrontR 2;
BA_ "InvalidValue" SG_ 1030 MHU_SET_SeatCoolingFrontR "4h";
BA_ "GenSigSendType" SG_ 1030 MHU_SET_SeatCoolingRearL 2;
BA_ "InvalidValue" SG_ 1030 MHU_SET_SeatCoolingRearL "4h";
BA_ "GenSigSendType" SG_ 1030 MHU_SET_SeatCoolingRearR 2;
BA_ "InvalidValue" SG_ 1030 MHU_SET_SeatCoolingRearR "4h";
BA_ "GenSigSendType" SG_ 1032 MHU_SET_MirrorAuto 2;
BA_ "GenSigStartValue" SG_ 1032 MHU_SET_MirrorAuto 3;
BA_ "InvalidValue" SG_ 1032 MHU_SET_MirrorAuto "3h";
BA_ "GenSigSendType" SG_ 1032 MHU_SET_MirrorAutoUnfold 2;
BA_ "GenSigStartValue" SG_ 1032 MHU_SET_MirrorAutoUnfold 3;
BA_ "InvalidValue" SG_ 1032 MHU_SET_MirrorAutoUnfold "3h";
BA_ "GenSigSendType" SG_ 1032 MHU_SET_WLC 2;
BA_ "GenSigStartValue" SG_ 1032 MHU_SET_WLC 3;
BA_ "InvalidValue" SG_ 1032 MHU_SET_WLC "3h";
BA_ "GenSigSendType" SG_ 1032 MHU_SET_AutoRearWiper 2;
BA_ "GenSigStartValue" SG_ 1032 MHU_SET_AutoRearWiper 3;
BA_ "InvalidValue" SG_ 1032 MHU_SET_AutoRearWiper "3h";
BA_ "GenSigSendType" SG_ 1032 MHU_SET_RearHeatedWindow 2;
BA_ "InvalidValue" SG_ 1032 MHU_SET_RearHeatedWindow "3h";
BA_ "GenSigSendType" SG_ 1032 MHU_TPMSReset 2;
BA_ "InvalidValue" SG_ 1032 MHU_TPMSReset "3h";
BA_ "GenSigSendType" SG_ 1032 MHU_SET_MirrorDefaultSetting 2;
BA_ "GenSigStartValue" SG_ 1032 MHU_SET_MirrorDefaultSetting 3;
BA_ "InvalidValue" SG_ 1032 MHU_SET_MirrorDefaultSetting "3h";
BA_ "GenSigSendType" SG_ 1032 MHU_SET_MirrorReverseLink 2;
BA_ "GenSigStartValue" SG_ 1032 MHU_SET_MirrorReverseLink 3;
BA_ "InvalidValue" SG_ 1032 MHU_SET_MirrorReverseLink "3h";
BA_ "GenSigSendType" SG_ 1032 MHU_SET_AntiTheftMode 2;
BA_ "GenSigStartValue" SG_ 1032 MHU_SET_AntiTheftMode 3;
BA_ "InvalidValue" SG_ 1032 MHU_SET_AntiTheftMode "3h";
BA_ "GenSigSendType" SG_ 1032 MHU_SET_WLCReminder 2;
BA_ "GenSigStartValue" SG_ 1032 MHU_SET_WLCReminder 1;
BA_ "InvalidValue" SG_ 1032 MHU_SET_WLCReminder "3h";
BA_ "GenSigSendType" SG_ 1032 MHU_SET_ClimateKeepOn 2;
BA_ "InvalidValue" SG_ 1032 MHU_SET_ClimateKeepOn "null";
BA_ "GenSigSendType" SG_ 1032 MHU_SET_WLC2 2;
BA_ "GenSigStartValue" SG_ 1032 MHU_SET_WLC2 1;
BA_ "InvalidValue" SG_ 1032 MHU_SET_WLC2 "3h";
BA_ "GenSigSendType" SG_ 1032 MHU_SET_WLC2Reminder 2;
BA_ "GenSigStartValue" SG_ 1032 MHU_SET_WLC2Reminder 1;
BA_ "InvalidValue" SG_ 1032 MHU_SET_WLC2Reminder "3h";
BA_ "GenSigSendType" SG_ 1032 MHU_IntrusionAlertStatus 2;
BA_ "GenSigStartValue" SG_ 1032 MHU_IntrusionAlertStatus 3;
BA_ "InvalidValue" SG_ 1032 MHU_IntrusionAlertStatus "3h";
BA_ "GenSigSendType" SG_ 1033 CHSKM_ADAS_WarnMsg 3;
BA_ "GenSigTimeoutTime_ALL" SG_ 1033 CHSKM_ADAS_WarnMsg 5000;
BA_ "GenSigSendType" SG_ 1033 ALV_ADAS_WarnMsg 3;
BA_ "GenSigTimeoutTime_ALL" SG_ 1033 ALV_ADAS_WarnMsg 5000;
BA_ "InvalidValue" SG_ 1033 ALV_ADAS_WarnMsg "Fh";
BA_ "GenSigSendType" SG_ 1033 ADAS_Warning_Flag_1 4;
BA_ "GenSigTimeoutTime_ALL" SG_ 1033 ADAS_Warning_Flag_1 5000;
BA_ "GenSigSendType" SG_ 1033 ADAS_Warning_Flag_2 4;
BA_ "GenSigTimeoutTime_ALL" SG_ 1033 ADAS_Warning_Flag_2 5000;
BA_ "GenSigSendType" SG_ 1033 ADAS_Warning_Flag_3 4;
BA_ "GenSigTimeoutTime_ALL" SG_ 1033 ADAS_Warning_Flag_3 5000;
BA_ "GenSigSendType" SG_ 1033 ADAS_Warning_Flag_4 4;
BA_ "GenSigTimeoutTime_ALL" SG_ 1033 ADAS_Warning_Flag_4 5000;
BA_ "GenSigSendType" SG_ 1033 ADAS_Warning_Flag_5 4;
BA_ "GenSigTimeoutTime_ALL" SG_ 1033 ADAS_Warning_Flag_5 5000;
BA_ "GenSigSendType" SG_ 1033 ADAS_Warning_Flag_6 4;
BA_ "GenSigTimeoutTime_ALL" SG_ 1033 ADAS_Warning_Flag_6 5000;
BA_ "GenSigSendType" SG_ 1033 ADAS_Warning_Flag_7 4;
BA_ "GenSigTimeoutTime_ALL" SG_ 1033 ADAS_Warning_Flag_7 5000;
BA_ "GenSigSendType" SG_ 1033 ADAS_Warning_Flag_8 4;
BA_ "GenSigTimeoutTime_ALL" SG_ 1033 ADAS_Warning_Flag_8 5000;
BA_ "GenSigSendType" SG_ 1033 ADAS_Warning_Flag_9 4;
BA_ "GenSigTimeoutTime_ALL" SG_ 1033 ADAS_Warning_Flag_9 5000;
BA_ "GenSigSendType" SG_ 1033 ADAS_Warning_Flag_10 4;
BA_ "GenSigTimeoutTime_ALL" SG_ 1033 ADAS_Warning_Flag_10 5000;
BA_ "GenSigSendType" SG_ 1033 ADAS_Warning_Flag_11 4;
BA_ "GenSigTimeoutTime_ALL" SG_ 1033 ADAS_Warning_Flag_11 5000;
BA_ "GenSigSendType" SG_ 1033 ADAS_Warning_Flag_12 4;
BA_ "GenSigTimeoutTime_ALL" SG_ 1033 ADAS_Warning_Flag_12 5000;
BA_ "GenSigSendType" SG_ 1033 ADAS_Warning_Flag_13 4;
BA_ "GenSigTimeoutTime_ALL" SG_ 1033 ADAS_Warning_Flag_13 5000;
BA_ "GenSigSendType" SG_ 1033 ADAS_Warning_Flag_14 4;
BA_ "GenSigTimeoutTime_ALL" SG_ 1033 ADAS_Warning_Flag_14 5000;
BA_ "GenSigSendType" SG_ 1033 ADAS_Warning_Flag_15 4;
BA_ "GenSigTimeoutTime_ALL" SG_ 1033 ADAS_Warning_Flag_15 5000;
BA_ "GenSigSendType" SG_ 1033 ADAS_Warning_Flag_16 4;
BA_ "GenSigTimeoutTime_ALL" SG_ 1033 ADAS_Warning_Flag_16 5000;
BA_ "GenSigSendType" SG_ 1033 ADAS_Warning_Flag_17 4;
BA_ "GenSigTimeoutTime_ALL" SG_ 1033 ADAS_Warning_Flag_17 5000;
BA_ "GenSigSendType" SG_ 1033 ADAS_Warning_Flag_18 4;
BA_ "GenSigTimeoutTime_ALL" SG_ 1033 ADAS_Warning_Flag_18 5000;
BA_ "GenSigSendType" SG_ 1033 ADAS_Warning_Flag_19 4;
BA_ "GenSigTimeoutTime_ALL" SG_ 1033 ADAS_Warning_Flag_19 5000;
BA_ "GenSigSendType" SG_ 1033 ADAS_Warning_Flag_20 4;
BA_ "GenSigTimeoutTime_ALL" SG_ 1033 ADAS_Warning_Flag_20 5000;
BA_ "GenSigSendType" SG_ 1033 ADAS_Warning_Flag_21 4;
BA_ "GenSigTimeoutTime_ALL" SG_ 1033 ADAS_Warning_Flag_21 5000;
BA_ "GenSigSendType" SG_ 1033 ADAS_Warning_Flag_22 4;
BA_ "GenSigTimeoutTime_ALL" SG_ 1033 ADAS_Warning_Flag_22 5000;
BA_ "GenSigSendType" SG_ 1033 ADAS_Warning_Flag_23 4;
BA_ "GenSigTimeoutTime_ALL" SG_ 1033 ADAS_Warning_Flag_23 5000;
BA_ "GenSigSendType" SG_ 1033 ADAS_Warning_Flag_24 4;
BA_ "GenSigTimeoutTime_ALL" SG_ 1033 ADAS_Warning_Flag_24 5000;
BA_ "GenSigSendType" SG_ 1033 ADAS_Warning_Flag_25 4;
BA_ "GenSigTimeoutTime_ALL" SG_ 1033 ADAS_Warning_Flag_25 5000;
BA_ "GenSigSendType" SG_ 1033 ADAS_Warning_Flag_26 4;
BA_ "GenSigTimeoutTime_ALL" SG_ 1033 ADAS_Warning_Flag_26 5000;
BA_ "GenSigSendType" SG_ 1033 ADAS_Warning_Flag_27 4;
BA_ "GenSigTimeoutTime_ALL" SG_ 1033 ADAS_Warning_Flag_27 5000;
BA_ "GenSigSendType" SG_ 1033 ADAS_Warning_Flag_28 4;
BA_ "GenSigTimeoutTime_ALL" SG_ 1033 ADAS_Warning_Flag_28 5000;
BA_ "GenSigSendType" SG_ 1033 ADAS_Warning_Flag_29 4;
BA_ "GenSigTimeoutTime_ALL" SG_ 1033 ADAS_Warning_Flag_29 5000;
BA_ "GenSigSendType" SG_ 1033 ADAS_Warning_Flag_30 4;
BA_ "GenSigTimeoutTime_ALL" SG_ 1033 ADAS_Warning_Flag_30 5000;
BA_ "GenSigSendType" SG_ 1033 ADAS_Warning_Flag_31 4;
BA_ "GenSigTimeoutTime_ALL" SG_ 1033 ADAS_Warning_Flag_31 5000;
BA_ "GenSigSendType" SG_ 1033 ADAS_Warning_Flag_32 4;
BA_ "GenSigTimeoutTime_ALL" SG_ 1033 ADAS_Warning_Flag_32 5000;
BA_ "GenSigSendType" SG_ 1033 ADAS_Warning_Flag_33 4;
BA_ "GenSigTimeoutTime_ALL" SG_ 1033 ADAS_Warning_Flag_33 5000;
BA_ "GenSigSendType" SG_ 1033 ADAS_Warning_Flag_34 4;
BA_ "GenSigTimeoutTime_ALL" SG_ 1033 ADAS_Warning_Flag_34 5000;
BA_ "GenSigSendType" SG_ 1033 ADAS_Warning_Flag_35 4;
BA_ "GenSigTimeoutTime_ALL" SG_ 1033 ADAS_Warning_Flag_35 5000;
BA_ "GenSigSendType" SG_ 1033 ADAS_Warning_Flag_36 4;
BA_ "GenSigTimeoutTime_ALL" SG_ 1033 ADAS_Warning_Flag_36 5000;
BA_ "GenSigSendType" SG_ 1033 ADAS_Warning_Flag_37 4;
BA_ "GenSigTimeoutTime_ALL" SG_ 1033 ADAS_Warning_Flag_37 5000;
BA_ "GenSigSendType" SG_ 1033 ADAS_Warning_Flag_38 4;
BA_ "GenSigTimeoutTime_ALL" SG_ 1033 ADAS_Warning_Flag_38 5000;
BA_ "GenSigSendType" SG_ 1033 ADAS_Warning_Flag_39 4;
BA_ "GenSigTimeoutTime_ALL" SG_ 1033 ADAS_Warning_Flag_39 5000;
BA_ "GenSigSendType" SG_ 1033 ADAS_Warning_Flag_40 4;
BA_ "GenSigTimeoutTime_ALL" SG_ 1033 ADAS_Warning_Flag_40 5000;
BA_ "GenSigSendType" SG_ 1033 ADAS_Warning_Flag_41 4;
BA_ "GenSigTimeoutTime_ALL" SG_ 1033 ADAS_Warning_Flag_41 5000;
BA_ "GenSigSendType" SG_ 1033 ADAS_Warning_Flag_42 4;
BA_ "GenSigTimeoutTime_ALL" SG_ 1033 ADAS_Warning_Flag_42 5000;
BA_ "GenSigSendType" SG_ 1033 ADAS_Warning_Flag_43 4;
BA_ "GenSigTimeoutTime_ALL" SG_ 1033 ADAS_Warning_Flag_43 5000;
BA_ "GenSigSendType" SG_ 1033 ADAS_Warning_Flag_44 4;
BA_ "GenSigTimeoutTime_ALL" SG_ 1033 ADAS_Warning_Flag_44 5000;
BA_ "GenSigSendType" SG_ 1033 ADAS_Warning_Flag_45 4;
BA_ "GenSigTimeoutTime_ALL" SG_ 1033 ADAS_Warning_Flag_45 5000;
BA_ "GenSigSendType" SG_ 1033 ADAS_Warning_Flag_46 4;
BA_ "GenSigTimeoutTime_ALL" SG_ 1033 ADAS_Warning_Flag_46 5000;
BA_ "GenSigSendType" SG_ 1033 ADAS_Warning_Flag_47 4;
BA_ "GenSigTimeoutTime_ALL" SG_ 1033 ADAS_Warning_Flag_47 5000;
BA_ "GenSigSendType" SG_ 1033 ADAS_Warning_Flag_48 4;
BA_ "GenSigTimeoutTime_ALL" SG_ 1033 ADAS_Warning_Flag_48 5000;
BA_ "GenSigSendType" SG_ 1033 ADAS_Warning_Flag_49 4;
BA_ "GenSigTimeoutTime_ALL" SG_ 1033 ADAS_Warning_Flag_49 5000;
BA_ "GenSigSendType" SG_ 1033 ADAS_Warning_Flag_50 4;
BA_ "GenSigTimeoutTime_ALL" SG_ 1033 ADAS_Warning_Flag_50 5000;
BA_ "GenSigSendType" SG_ 1033 ADAS_Warning_Flag_51 4;
BA_ "GenSigTimeoutTime_ALL" SG_ 1033 ADAS_Warning_Flag_51 5000;
BA_ "GenSigSendType" SG_ 1033 ADAS_Warning_Flag_52 4;
BA_ "GenSigTimeoutTime_ALL" SG_ 1033 ADAS_Warning_Flag_52 5000;
BA_ "GenSigSendType" SG_ 1034 MHU_SET_HudUIContent 2;
BA_ "InvalidValue" SG_ 1034 MHU_SET_HudUIContent "7h";
BA_ "GenSigSendType" SG_ 1034 MHU_SET_HudUIColor 2;
BA_ "GenSigSendType" SG_ 1034 MHU_SET_HudScreenOnOFF 2;
BA_ "GenSigStartValue" SG_ 1034 MHU_SET_HudScreenOnOFF 1;
BA_ "InvalidValue" SG_ 1034 MHU_SET_HudScreenOnOFF "3h";
BA_ "GenSigSendType" SG_ 1034 MHU_SET_UserBrightnessLvl 2;
BA_ "InvalidValue" SG_ 1034 MHU_SET_UserBrightnessLvl "Fh";
BA_ "GenSigSendType" SG_ 1034 MHU_SET_HudWorkingMode 2;
BA_ "InvalidValue" SG_ 1034 MHU_SET_HudWorkingMode "3h";
BA_ "GenSigSendType" SG_ 1034 MHU_SET_HudUISize 2;
BA_ "GenSigSendType" SG_ 1034 MHU_SET_UIContentMediaInfo 2;
BA_ "GenSigSendType" SG_ 1034 MHU_SET_UIContentCallInfo 2;
BA_ "GenSigSendType" SG_ 1034 MHU_SET_UIContentPoweRegen 2;
BA_ "GenSigSendType" SG_ 1035 MHU_SET_AvasSound 2;
BA_ "GenSigStartValue" SG_ 1035 MHU_SET_AvasSound 1;
BA_ "InvalidValue" SG_ 1035 MHU_SET_AvasSound "4h";
BA_ "GenSigTimeoutTime_ALL" SG_ 1036 CHSKM_MHU_SEAT_CONTROL 1000;
BA_ "InvalidValue" SG_ 1036 CHSKM_MHU_SEAT_CONTROL "null";
BA_ "GenSigTimeoutTime_ALL" SG_ 1036 ALV_MHU_SEAT_CONTROL 1000;
BA_ "InvalidValue" SG_ 1036 ALV_MHU_SEAT_CONTROL "Fh";
BA_ "GenSigTimeoutTime_ALL" SG_ 1036 MHU_DrvSeat_Control_Status 1000;
BA_ "InvalidValue" SG_ 1036 MHU_DrvSeat_Control_Status "7h";
BA_ "GenSigTimeoutTime_ALL" SG_ 1036 MHU_ExpDrvReclinerPos 1000;
BA_ "InvalidValue" SG_ 1036 MHU_ExpDrvReclinerPos "7Fh";
BA_ "GenSigTimeoutTime_ALL" SG_ 1036 MHU_ExpDrvTiltPos 1000;
BA_ "InvalidValue" SG_ 1036 MHU_ExpDrvTiltPos "1Fh";
BA_ "GenSigTimeoutTime_ALL" SG_ 1036 MHU_ExpDrvTrackPos 1000;
BA_ "InvalidValue" SG_ 1036 MHU_ExpDrvTrackPos "FFh";
BA_ "GenSigTimeoutTime_ALL" SG_ 1036 MHU_ExpDrvHeightPos 1000;
BA_ "InvalidValue" SG_ 1036 MHU_ExpDrvHeightPos "3Fh";
BA_ "GenSigTimeoutTime_ALL" SG_ 1037 CHKSM_MHU_DIGIT_SPEED 1500;
BA_ "GenSigTimeoutTime_ALL" SG_ 1037 ALV_MHU_DIGIT_SPEED 1500;
BA_ "InvalidValue" SG_ 1037 ALV_MHU_DIGIT_SPEED "Fh";
BA_ "GenSigTimeoutTime_ALL" SG_ 1037 MHU_DigitSpeed 1500;
BA_ "InvalidValue" SG_ 1037 MHU_DigitSpeed "1FFh";
BA_ "GenSigTimeoutTime_ALL" SG_ 1038 AveragePwrConsumpTripA 5000;
BA_ "GenSigTimeoutTime_ALL" SG_ 1038 AverageFuelConsumpTripA 5000;
BA_ "GenSigTimeoutTime_ALL" SG_ 1038 AvarageSpeedTripA 5000;
BA_ "InvalidValue" SG_ 1038 AvarageSpeedTripA "1FFh";
BA_ "GenSigTimeoutTime_ALL" SG_ 1038 TripA 5000;
BA_ "InvalidValue" SG_ 1038 TripA "1FFFFh";
BA_ "GenSigTimeoutTime_ALL" SG_ 1039 AveragePwrConsumpTripB 5000;
BA_ "GenSigTimeoutTime_ALL" SG_ 1039 AverageFuelConsumpTripB 5000;
BA_ "GenSigTimeoutTime_ALL" SG_ 1039 AvarageSpeedTripB 5000;
BA_ "InvalidValue" SG_ 1039 AvarageSpeedTripB "1FFh";
BA_ "GenSigTimeoutTime_ALL" SG_ 1039 TripB 5000;
BA_ "InvalidValue" SG_ 1039 TripB "1FFFFh";
BA_ "GenSigTimeoutTime_ALL" SG_ 1040 AveragePwrConsumpTripAuto 5000;
BA_ "GenSigTimeoutTime_ALL" SG_ 1040 AverageFuelConsumpTripAuto 5000;
BA_ "GenSigTimeoutTime_ALL" SG_ 1040 AvarageSpeedTripAuto 5000;
BA_ "InvalidValue" SG_ 1040 AvarageSpeedTripAuto "1FFh";
BA_ "GenSigTimeoutTime_ALL" SG_ 1040 TripAuto 5000;
BA_ "InvalidValue" SG_ 1040 TripAuto "1FFFFh";
BA_ "GenSigStartValue" SG_ 1046 BCM_STAT_LeftMirrorPosX 15;
BA_ "GenSigTimeoutTime_ALL" SG_ 1046 BCM_STAT_LeftMirrorPosX 500;
BA_ "GenSigTimeoutTime_ALL" SG_ 1046 BCM_STAT_LeftMirrorPosX 500;
BA_ "InvalidValue" SG_ 1046 BCM_STAT_LeftMirrorPosX "FFh";
BA_ "GenSigStartValue" SG_ 1046 BCM_STAT_LeftMirrorPosY 15;
BA_ "GenSigTimeoutTime_ALL" SG_ 1046 BCM_STAT_LeftMirrorPosY 500;
BA_ "GenSigTimeoutTime_ALL" SG_ 1046 BCM_STAT_LeftMirrorPosY 500;
BA_ "InvalidValue" SG_ 1046 BCM_STAT_LeftMirrorPosY "FFh";
BA_ "GenSigStartValue" SG_ 1046 BCM_STAT_RightMirrorPosX 15;
BA_ "GenSigTimeoutTime_ALL" SG_ 1046 BCM_STAT_RightMirrorPosX 500;
BA_ "GenSigTimeoutTime_ALL" SG_ 1046 BCM_STAT_RightMirrorPosX 500;
BA_ "InvalidValue" SG_ 1046 BCM_STAT_RightMirrorPosX "FFh";
BA_ "GenSigStartValue" SG_ 1046 BCM_STAT_RightMirrorPosY 15;
BA_ "GenSigTimeoutTime_ALL" SG_ 1046 BCM_STAT_RightMirrorPosY 500;
BA_ "GenSigTimeoutTime_ALL" SG_ 1046 BCM_STAT_RightMirrorPosY 500;
BA_ "InvalidValue" SG_ 1046 BCM_STAT_RightMirrorPosY "FFh";
BA_ "GenSigTimeoutTime_ALL" SG_ 1046 BCM_STAT_Mirror 500;
BA_ "GenSigTimeoutTime_ALL" SG_ 1046 BCM_STAT_Mirror 500;
BA_ "InvalidValue" SG_ 1046 BCM_STAT_Mirror "3h";
BA_ "GenSigTimeoutTime_ALL" SG_ 1046 BCM_STAT_MirrorAdjustLeft 500;
BA_ "GenSigTimeoutTime_ALL" SG_ 1046 BCM_STAT_MirrorAdjustLeft 500;
BA_ "InvalidValue" SG_ 1046 BCM_STAT_MirrorAdjustLeft "3h";
BA_ "GenSigTimeoutTime_ALL" SG_ 1046 BCM_STAT_MirrorAdjustRight 500;
BA_ "GenSigTimeoutTime_ALL" SG_ 1046 BCM_STAT_MirrorAdjustRight 500;
BA_ "InvalidValue" SG_ 1046 BCM_STAT_MirrorAdjustRight "3h";
BA_ "GenSigSendType" SG_ 1049 SHVU_STAT_SeatHeatingFrontL 3;
BA_ "InvalidValue" SG_ 1049 SHVU_STAT_SeatHeatingFrontL "4h";
BA_ "GenSigSendType" SG_ 1049 SHVU_STAT_SeatHeatingFrontR 3;
BA_ "InvalidValue" SG_ 1049 SHVU_STAT_SeatHeatingFrontR "4h";
BA_ "GenSigSendType" SG_ 1049 SHVU_STAT_SeatCoolingFrontL 3;
BA_ "InvalidValue" SG_ 1049 SHVU_STAT_SeatCoolingFrontL "4h";
BA_ "GenSigSendType" SG_ 1049 SHVU_STAT_SeatCoolingFrontR 3;
BA_ "InvalidValue" SG_ 1049 SHVU_STAT_SeatCoolingFrontR "4h";
BA_ "GenSigSendType" SG_ 1049 SHVU_STAT_FrontSeatVentSts 3;
BA_ "InvalidValue" SG_ 1049 SHVU_STAT_FrontSeatVentSts "3h";
BA_ "GenSigSendType" SG_ 1050 SHVU_STAT_SeatCoolingRearL 3;
BA_ "InvalidValue" SG_ 1050 SHVU_STAT_SeatCoolingRearL "4h";
BA_ "GenSigSendType" SG_ 1050 SHVU_STAT_SeatCoolingRearR 3;
BA_ "InvalidValue" SG_ 1050 SHVU_STAT_SeatCoolingRearR "4h";
BA_ "GenSigSendType" SG_ 1050 SHVU_STAT_SeatHeatingReartL 3;
BA_ "InvalidValue" SG_ 1050 SHVU_STAT_SeatHeatingReartL "4h";
BA_ "GenSigSendType" SG_ 1050 SHVU_STAT_SeatHeatingRearR 3;
BA_ "InvalidValue" SG_ 1050 SHVU_STAT_SeatHeatingRearR "4h";
BA_ "GenSigSendType" SG_ 1050 SHVU_STAT_RearSeatVentSts 3;
BA_ "InvalidValue" SG_ 1050 SHVU_STAT_RearSeatVentSts "3h";
BA_ "GenSigTimeoutTime_ALL" SG_ 1052 CHKSM_PSM_SEAT_POSITION 5000;
BA_ "GenSigTimeoutTime_ALL" SG_ 1052 AVL_PSM_SEAT_POSITION 5000;
BA_ "InvalidValue" SG_ 1052 AVL_PSM_SEAT_POSITION "Fh";
BA_ "GenSigTimeoutTime_ALL" SG_ 1052 PSM_Seat_track_pos_Dri 5000;
BA_ "InvalidValue" SG_ 1052 PSM_Seat_track_pos_Dri "3h";
BA_ "GenSigTimeoutTime_ALL" SG_ 1052 PSM_Seat_track_posPas 5000;
BA_ "InvalidValue" SG_ 1052 PSM_Seat_track_posPas "3h";
BA_ "GenSigStartValue" SG_ 1053 BCM_STAT_AutoRearWiper 1;
BA_ "GenSigTimeoutTime_ALL" SG_ 1053 BCM_STAT_AutoRearWiper 500;
BA_ "InvalidValue" SG_ 1053 BCM_STAT_AutoRearWiper "3h";
BA_ "GenSigStartValue" SG_ 1053 BCM_STAT_MirrorFoldSetting 3;
BA_ "GenSigTimeoutTime_ALL" SG_ 1053 BCM_STAT_MirrorFoldSetting 500;
BA_ "InvalidValue" SG_ 1053 BCM_STAT_MirrorFoldSetting "3h";
BA_ "GenSigTimeoutTime_ALL" SG_ 1053 BCM_STAT_IMMO_KeyfobID2 500;
BA_ "GenSigTimeoutTime_ALL" SG_ 1053 BCM_STAT_IMMO_KeyfobID2 500;
BA_ "GenSigTimeoutTime_ALL" SG_ 1053 BCM_STAT_MirrorAutoUnfold 500;
BA_ "InvalidValue" SG_ 1053 BCM_STAT_MirrorAutoUnfold "3h";
BA_ "GenSigStartValue" SG_ 1053 BCM_STAT_MirrorReverseLink 1;
BA_ "GenSigTimeoutTime_ALL" SG_ 1053 BCM_STAT_MirrorReverseLink 500;
BA_ "InvalidValue" SG_ 1053 BCM_STAT_MirrorReverseLink "3h";
BA_ "GenSigTimeoutTime_ALL" SG_ 1053 BCM_STAT_MirrorDefaultSTATting 500;
BA_ "InvalidValue" SG_ 1053 BCM_STAT_MirrorDefaultSTATting "3h";
BA_ "GenSigTimeoutTime_ALL" SG_ 1053 BCM_STAT_WelcomeTriggerCondition 500;
BA_ "InvalidValue" SG_ 1053 BCM_STAT_WelcomeTriggerCondition "3h";
BA_ "GenSigStartValue" SG_ 1053 BCM_STAT_FrontDomeLamp 1;
BA_ "GenSigTimeoutTime_ALL" SG_ 1053 BCM_STAT_FrontDomeLamp 500;
BA_ "InvalidValue" SG_ 1053 BCM_STAT_FrontDomeLamp "3h";
BA_ "GenSigTimeoutTime_ALL" SG_ 1053 BCM_STAT_FollowMeHome 500;
BA_ "InvalidValue" SG_ 1053 BCM_STAT_FollowMeHome "5h";
BA_ "GenSigTimeoutTime_ALL" SG_ 1053 BCM_STAT_ExteriorLight 500;
BA_ "InvalidValue" SG_ 1053 BCM_STAT_ExteriorLight "4h";
BA_ "GenSigStartValue" SG_ 1053 BCM_STAT_RemoteLockFeedback 7;
BA_ "GenSigTimeoutTime_ALL" SG_ 1053 BCM_STAT_RemoteLockFeedback 500;
BA_ "InvalidValue" SG_ 1053 BCM_STAT_RemoteLockFeedback "7h";
BA_ "GenSigStartValue" SG_ 1053 BCM_STAT_RemoteDoorUnlock 3;
BA_ "GenSigTimeoutTime_ALL" SG_ 1053 BCM_STAT_RemoteDoorUnlock 500;
BA_ "InvalidValue" SG_ 1053 BCM_STAT_RemoteDoorUnlock "3h";
BA_ "GenSigStartValue" SG_ 1053 BCM_STAT_AutoDoorUnlock 3;
BA_ "GenSigTimeoutTime_ALL" SG_ 1053 BCM_STAT_AutoDoorUnlock 500;
BA_ "InvalidValue" SG_ 1053 BCM_STAT_AutoDoorUnlock "3h";
BA_ "GenSigStartValue" SG_ 1053 BCM_STAT_AmbientLightBrighness 80;
BA_ "GenSigTimeoutTime_ALL" SG_ 1053 BCM_STAT_AmbientLightBrighness 500;
BA_ "InvalidValue" SG_ 1053 BCM_STAT_AmbientLightBrighness "7Fh";
BA_ "GenSigStartValue" SG_ 1053 BCM_STAT_WiperServiceMode 3;
BA_ "GenSigTimeoutTime_ALL" SG_ 1053 BCM_STAT_WiperServiceMode 500;
BA_ "InvalidValue" SG_ 1053 BCM_STAT_WiperServiceMode "3h";
BA_ "GenSigStartValue" SG_ 1053 BCM_STAT_IMMO_KeyfobID 3;
BA_ "GenSigTimeoutTime_ALL" SG_ 1053 BCM_STAT_IMMO_KeyfobID 500;
BA_ "InvalidValue" SG_ 1053 BCM_STAT_IMMO_KeyfobID "3h";
BA_ "GenSigTimeoutTime_ALL" SG_ 1053 BCM_STAT_RearHeatedWindowMirror 500;
BA_ "InvalidValue" SG_ 1053 BCM_STAT_RearHeatedWindowMirror "3h";
BA_ "GenSigStartValue" SG_ 1053 BCM_STAT_AntiTheftMode 3;
BA_ "GenSigTimeoutTime_ALL" SG_ 1053 BCM_STAT_AntiTheftMode 500;
BA_ "InvalidValue" SG_ 1053 BCM_STAT_AntiTheftMode "4h";
BA_ "GenSigTimeoutTime_ALL" SG_ 1053 BCM_STAT_ClimateKeepOnSts 500;
BA_ "InvalidValue" SG_ 1053 BCM_STAT_ClimateKeepOnSts "null";
BA_ "GenSigTimeoutTime_ALL" SG_ 1053 BCM_STAT_FKSfeedback 500;
BA_ "InvalidValue" SG_ 1053 BCM_STAT_FKSfeedback "3h";
BA_ "GenSigTimeoutTime_ALL" SG_ 1053 SECCAN_CmftCnfrm 500;
BA_ "GenSigTimeoutTime_ALL" SG_ 1053 SECCAN_CmftCnfrm 500;
BA_ "InvalidValue" SG_ 1053 SECCAN_CmftCnfrm "null";
VAL_ 784 CCUR_STAT_IonButton 0 "OFF" 1 "ON" 2 "Reserved" 3 "Signal invalid";
VAL_ 784 CCUR_STAT_Defrost 0 "OFF" 1 "ON" 2 "Reserved" 3 "Signal invalid";
VAL_ 784 CCUR_STAT_Auto 0 "OFF" 1 "ON" 2 "Reserved" 3 "Signal invalid";
VAL_ 784 CCUR_STAT_Aircondition 0 "OFF" 1 "ON" 2 "Reserved" 3 "Signal invalid";
VAL_ 784 CCUR_STAT_FlapPos 0 "OFF" 1 "Vent" 2 "Vent/Foot" 3 "Foot" 4 "Foot/Defrost" 5 "Defrost" 6 "Default" 7 "Signal invalid";
VAL_ 784 CCUR_STAT_FanSpeed 0 "OFF" 1 "Level 1" 2 "Level 2" 3 "Level 3" 4 "Level 4" 5 "Level 5" 6 "Level 6" 7 "Reserved" 8 "Reserved" 9 "Reserved" 10 "Reserved" 11 "Reserved" 12 "Reserved" 13 "Reserved" 14 "Reserved" 15 "Signal invalid";
VAL_ 784 CCUR_STAT_PTC_Heater 0 "OFF" 1 "Stage 1" 2 "Stage 2" 3 "Stage 3" 4 "Reserved" 5 "Reserved" 6 "Reserved" 7 "Signal invalid";
VAL_ 784 CCUR_STAT_OnOff 0 "OFF" 1 "ON" 2 "Reserved" 3 "Signal invalid";
VAL_ 784 CCUR_STAT_MaxAc 0 "OFF" 1 "ON" 2 "Reserved" 3 "Signal invalid";
VAL_ 784 CCUR_STAT_SyncClimateZone 0 "OFF" 1 "ON" 2 "Reserved" 3 "Signal invalid";
VAL_ 784 CCUR_STAT_RecircFlap 0 "Inside" 1 "Outside" 2 "Auto" 3 "Signal invalid";
VAL_ 787 POD_statusOBC 0 "OBC_OFF" 1 "OBC_STANDBY" 2 "OBC_ON_NORMAL" 3 "OBC_ON_VOLTAGE" 4 "OBC_DEGRADED" 5 "OBC_FAULT_SHUTDOWN" 6 "OBC_EMERGENCY_SHUTDOWN" 7 "OBC_STS_SNA";
VAL_ 803 POD_phaseACInput 0 "Not Used" 1 "AC 1 phase input" 2 "Not used" 3 "AC 3 phase input";
VAL_ 804 Steering_HeatingControl 0 "Disable" 1 "Enable";
VAL_ 805 Steering_HeatingControlFdbk 0 "Disable" 1 "Enable" 2 "Error";
VAL_ 806 POD_statusDCDC 0 "DCDC_OFF" 1 "DCDC_STANDBY" 2 "DCDC_ON" 3 "DCDC_RESERVED" 4 "DCDC_DEGRADED" 5 "DCDC_FAULT_SHUTDOWN" 6 "DCDC_EMERGENCY_SHUTDOWN" 7 "DCDC_STS_SNA";
VAL_ 816 ST_FLLV_FUTA_SPAR 0 "No active" 1 "Active" 2 "Reserved" 3 "Signal invalid";
VAL_ 827 Camera_R1_Line_Type 0 "No display" 1 "solid line" 2 "dashed line" 3 "Roadside";
VAL_ 827 Camera_L1_Line_Type 0 "off" 1 "Gray ICON" 2 "Green ICON" 3 "reserved";
VAL_ 833 ADAS_OBJ01_Class 0 "Unknown" 1 "Car" 2 "Truck" 3 "Motorbike" 4 "bicycle" 5 "Pedestrian" 6 "truck or car" 7 "reserved";
VAL_ 833 ADAS_OBJ01_Lane 0 "Undefined" 1 "Left lane" 2 "Host lane" 3 "Right lane";
VAL_ 835 ADAS_OBJ02_Class 0 "Unknown" 1 "Car" 2 "Truck" 3 "Motorbike" 4 "bicycle" 5 "Pedestrian" 6 "truck or car" 7 "reserved";
VAL_ 835 ADAS_OBJ02_Lane 0 "Undefined" 1 "Left lane" 2 "Host lane" 3 "Right lane";
VAL_ 842 ADAS_OBJ03_Class 0 "Unknown" 1 "Car" 2 "Truck" 3 "Motorbike" 4 "bicycle" 5 "Pedestrian" 6 "truck or car" 7 "reserved";
VAL_ 842 ADAS_OBJ03_Lane 0 "Undefined" 1 "Left lane" 2 "Host lane" 3 "Right lane";
VAL_ 844 ADAS_OBJ04_Class 0 "Unknown" 1 "Car" 2 "Truck" 3 "Motorbike" 4 "bicycle" 5 "Pedestrian" 6 "truck or car" 7 "reserved";
VAL_ 844 ADAS_OBJ04_Lane 0 "Undefined" 1 "Left lane" 2 "Host lane" 3 "Right lane";
VAL_ 845 ADAS_OBJ05_Class 0 "Unknown" 1 "Car" 2 "Truck" 3 "Motorbike" 4 "bicycle" 5 "Pedestrian" 6 "truck or car" 7 "reserved";
VAL_ 845 ADAS_OBJ05_Lane 0 "Undefined" 1 "Left lane" 2 "Host lane" 3 "Right lane";
VAL_ 846 ADAS_OBJ06_Class 0 "Unknown" 1 "Car" 2 "Truck" 3 "Motorbike" 4 "bicycle" 5 "Pedestrian" 6 "truck or car" 7 "reserved";
VAL_ 846 ADAS_OBJ06_Lane 0 "Undefined" 1 "Left lane" 2 "Host lane" 3 "Right lane";
VAL_ 849 ADAS_PA_AutoOn_Feed 0 "Off" 1 "On";
VAL_ 849 ADAS_PA_AlertFRI 0 "Off" 1 "1st warning" 2 "2nd warning" 3 "3rd warning" 4 "4th warning" 5 "5th warning" 6 "Reserved" 7 "Error";
VAL_ 849 ADAS_PA_AlertFLI 0 "Off" 1 "1st warning" 2 "2nd warning" 3 "3rd warning" 4 "4th warning" 5 "5th warning" 6 "Reserved" 7 "Error";
VAL_ 849 ADAS_PA_AlertFLO 0 "Off" 1 "1st warning" 2 "2nd warning" 3 "3rd warning" 4 "4th warning" 5 "5th warning" 6 "Reserved" 7 "Error";
VAL_ 849 ADAS_PA_AlertRLO 0 "Off" 1 "1st warning" 2 "2nd warning" 3 "3rd warning" 4 "4th warning" 5 "5th warning" 6 "Reserved" 7 "Error";
VAL_ 849 ADAS_PA_AlertRLI 0 "Off" 1 "1st warning" 2 "2nd warning" 3 "3rd warning" 4 "4th warning" 5 "5th warning" 6 "Reserved" 7 "Error";
VAL_ 849 ADAS_PA_AlertFRO 0 "Off" 1 "1st warning" 2 "2nd warning" 3 "3rd warning" 4 "4th warning" 5 "5th warning" 6 "Reserved" 7 "Error";
VAL_ 849 ADAS_PA_AlertRRO 0 "Off" 1 "1st warning" 2 "2nd warning" 3 "3rd warning" 4 "4th warning" 5 "5th warning" 6 "Reserved" 7 "Error";
VAL_ 849 ADAS_PA_AlertRRI 0 "Off" 1 "1st warning" 2 "2nd warning" 3 "3rd warning" 4 "4th warning" 5 "5th warning" 6 "Reserved" 7 "Error";
VAL_ 849 ADAS_PA_state 0 "OFF State" 1 "Stand by state" 2 "Active state" 3 "Failed state";
VAL_ 850 ADAS_AHB_sens_Feed 0 "Early" 1 "Normal" 2 "Late" 3 "reserved";
VAL_ 850 ADAS_AHB_Mode_Feed 0 "Off" 1 "On";
VAL_ 850 ADAS_AHB_check 0 "Available" 1 "Temporarily not available" 2 "Permanently not available";
VAL_ 850 ADAS_AHB_state 0 "OFF State" 1 "HighBeam Passive or Inactive" 2 "HighBeam Active" 3 "Fault";
VAL_ 850 ADAS_DOW_WarnRight 0 "No warning" 1 "Warning Level 1" 2 "Warning Level 2" 3 "Reserved";
VAL_ 850 ADAS_DOW_SndWarn 0 "Sound Warning disable" 1 "Left Sound Warning enable" 2 "Right Sound Warning enable" 3 "Left and Right Sound Warning enable";
VAL_ 850 ADAS_DOW_state 0 "OFF State" 1 "Stand by state" 2 "Armed state" 3 "Warning stage" 4 "Malfunction stage";
VAL_ 850 ADAS_DOW_check 0 "Available" 1 "Temporarily not available" 2 "Permanently not available";
VAL_ 850 ADAS_DOW_WarnLeft 0 "No warning" 1 "Warning Level 1" 2 "Warning Level 2" 3 "Reserved";
VAL_ 850 ADAS_DOW_Mode_Feed 0 "Off" 1 "Warning Only" 2 "Warning/Door Lock both" 3 "Reserved";
VAL_ 850 ADAS_AHB_RBPos 0 "Off or low beam" 1 "high beam" 2 "Reserved" 3 "Reserved" 4 "Reserved" 5 "Reserved" 6 "Reserved" 7 "Reserved";
VAL_ 850 ADAS_AHB_LBPos 0 "Off or low beam" 1 "high beam" 2 "Reserved" 3 "Reserved" 4 "Reserved" 5 "Reserved" 6 "Reserved" 7 "Reserved";
VAL_ 851 ADAS_ACC_ObjDetec 0 "Lead Object Not detected" 1 "Lead Object detected";
VAL_ 851 ADAS_ISA_check 0 "Available" 1 "Temporarily not available" 2 "Permanently not available";
VAL_ 851 ADAS_ISA_Mode_SW_Feed 0 "Off" 1 "On";
VAL_ 851 ADAS_TagSpeed_ICON_Feed 0 "Off" 1 "Gray ICON" 2 "Green ICON" 3 "White ICON" 4 "Yellow ICON" 5 "Red ICON";
VAL_ 851 ADAS_ISA_PopUp_Feed 0 "-" 1 "Accelerating to match speed limit" 2 "Decelerating to match speed limit" 3 "Press steering wheel button to match speed limit" 4 "Intelligent Speed Assist Unavailable" 5 "Reserved" 6 "Reserved" 7 "Reserved" 8 "Reserved" 9 "Reserved" 10 "Reserved" 11 "Reserved" 12 "Reserved" 13 "Reserved" 14 "Reserved" 15 "Invalid";
VAL_ 851 ADAS_ISA_Btn_Feed 0 "Off" 1 "On";
VAL_ 851 ADAS_ACC_DistSet_upper_Feed 0 "-" 1 "Up_Feed";
VAL_ 851 ADAS_ACC_TimeGapSet 0 "No time gap" 1 "1st level distance" 2 "2nd level distance" 3 "3rd level distance" 4 "4th level distance" 5 "Reserved" 6 "Reserved";
VAL_ 851 ADAS_ACC_State 0 "OFF State or Passive" 1 "Stand by state" 2 "Active" 3 "Override" 4 "Brake Only" 5 "Standstill Active" 6 "Standstill Wait" 7 "Fault";
VAL_ 851 ADAS_ACC_PopUp_Feed 0 "-" 1 "None (Feature On)" 2 "None (Feature Off)" 3 "Press gas pedal to re-engage the function" 4 "Speed Assist is unavailable Conditions not met" 5 "Resume not available Please activate Speed Assist button" 6 "Speed Assist is unavailable See Fault Details for more ingo" 7 "Speed Assist will off below 20kph. Issue with vehicle sensors" 8 "Take over driving now!" 9 "Take over driving now!Speed Assist Off";
VAL_ 851 ADAS_ACC_check 0 "Available" 1 "Temporarily not available" 2 "Permanently not available";
VAL_ 851 ADAS_ISA_ICON_Feed 0 "Off" 1 "Gray ICON" 2 "Green ICON" 3 "White ICON" 4 "Yellow ICON" 5 "Red ICON";
VAL_ 851 ADAS_ACC_DistSet_lower_Feed 0 "-" 1 "Down_Feed";
VAL_ 851 ADAS_ACC_SpdSet_upper_Feed 0 "-" 1 "Up_Feed";
VAL_ 851 ADAS_ACC_SpdSet_lower_Feed 0 "-" 1 "Down_Feed";
VAL_ 851 ADAS_ACC_On_Feed 0 "Off" 1 "On";
VAL_ 851 ADAS_ACC_Set_Feed 0 "-" 1 "Set_Feed";
VAL_ 851 ADAS_ACC_CnlBtn_Feed 0 "-" 1 "Cancel_Feed";
VAL_ 851 ADAS_ACC_Res_Feed 0 "-" 1 "Res_Feed";
VAL_ 851 ADAS_ACC_ICON_Feed 0 "Off" 1 "Gray ICON" 2 "Green ICON" 3 "White ICON" 4 "Yellow ICON" 5 "Red ICON";
VAL_ 851 ADAS_ISA_Status 0 "OFF State" 1 "Stand by state" 2 "Active(Auto) state" 3 "Reserved" 4 "Reserved";
VAL_ 852 MHU_FCW_Mode 0 "OFF" 1 "ON" 2 "Reserve" 3 "Signal invalid";
VAL_ 852 MHU_FCW_sens 0 "Early" 1 "Normal" 2 "Late" 3 "Signal invalid";
VAL_ 852 MHU_AEB_Mode 0 "OFF" 1 "ON" 2 "Reserved" 3 "Signal invalid";
VAL_ 852 MHU_RAEB_Mode 0 "OFF" 1 "ON" 2 "Reserved" 3 "Signal invalid";
VAL_ 852 MHU_LA_sens 0 "Early" 1 "Normal" 2 "Late" 3 "Signal invalid";
VAL_ 852 MHU_LA_AudWarning 0 "OFF" 1 "ON" 2 "Reserved" 3 "Signal invalid";
VAL_ 852 MHU_BSD_On 0 "OFF" 1 "ON" 2 "Reserved" 3 "Signal invalid";
VAL_ 852 MHU_ALC_ON 0 "OFF" 1 "ON" 2 "Reserved" 3 "Reserved";
VAL_ 852 MHU_BSD_AudWarning 0 "OFF" 1 "ON" 2 "Reserved" 3 "Signal invalid";
VAL_ 852 MHU_RCTA_On 0 "OFF" 1 "ON" 2 "Reserved" 3 "Signal invalid";
VAL_ 852 MHU_RCTA_sens 0 "Early" 1 "Normal" 2 "Late" 3 "Signal invalid";
VAL_ 852 MHU_PA_On 0 "OFF" 1 "ON" 2 "Reserved" 3 "Signal invalid";
VAL_ 852 MHU_AHB_On 0 "OFF" 1 "ON" 2 "Reserved" 3 "Signal invalid";
VAL_ 852 MHU_IA_Mode 0 "OFF" 1 "ON" 2 "Reserved" 3 "Signal invalid";
VAL_ 852 MHU_TSR_Mode 0 "OFF" 1 "ON" 2 "Reserve" 3 "Signal invalid";
VAL_ 852 MHU_DOW_Mode 0 "OFF" 1 "Warning Only" 2 "Warning/Door Lock both" 3 "Signal invalid";
VAL_ 852 MHU_AHB_sens 0 "Early" 1 "Normal" 2 "Late" 3 "Signal invalid";
VAL_ 852 MHU_LA_Mode 0 "OFF" 1 "Warning only" 2 "Warning & Steer" 3 "ELK" 4 "Signal Invalid";
VAL_ 852 MHU_SET_TSR_AudWarn 0 "OFF" 1 "ON" 2 "Reserved" 3 "Signal invalid";
VAL_ 852 MHU_SET_TSR_SLAert 0 "OFF" 1 "Speed Limit" 2 "Speed Limit + 5" 3 "Speed Limit + 10";
VAL_ 853 ADAS_PAUSS_FaultFLO 0 "No fault" 1 "Fault";
VAL_ 853 ADAS_PAUSS_FaultFLI 0 "No fault" 1 "Fault";
VAL_ 853 ADAS_PAUSS_check 0 "Available" 1 "Temporarily not available" 2 "Permanently not available";
VAL_ 853 ADAS_PAUSS_FaultRLO 0 "No fault" 1 "Fault";
VAL_ 853 ADAS_PAUSS_FaultFRI 0 "No fault" 1 "Fault";
VAL_ 853 ADAS_FPA_check 0 "Available" 1 "Temporarily not available" 2 "Permanently not available";
VAL_ 853 ADAS_PAUSS_FaultRLI 0 "No fault" 1 "Fault";
VAL_ 853 ADAS_PAUSS_FaultRRO 0 "No fault" 1 "Fault";
VAL_ 853 ADAS_PAUSS_FaultRRI 0 "No fault" 1 "Fault";
VAL_ 853 ADAS_RPA_check 0 "Available" 1 "Temporarily not available" 2 "Permanently not available";
VAL_ 853 ADAS_PAUSS_FaultFRO 0 "No fault" 1 "Fault";
VAL_ 880 SBR_STAT_Chime 0 "Off" 1 "Durable" 2 "Blinking 3Hz" 3 "SNA";
VAL_ 880 SBR_STAT_Telltale 0 "No chime" 1 "1 Hz" 2 "3 Hz" 3 "SNA";
VAL_ 880 SBR_STAT_Active 0 "Not active" 1 "Active";
VAL_ 885 BMS_PreChgRelay_ERR 0 "error" 1 "normal";
VAL_ 885 BMS_TotalNegRelay_ERR 0 "Error" 1 "normal";
VAL_ 885 BMS_MainPosRelay_ERR 0 "Error" 1 "normal";
VAL_ 885 BMS_MainPosRelay_STS 0 "reserved" 1 "open" 2 "closed" 3 "stuck closed" 4 "stuck open";
VAL_ 885 BMS_PreChgRelay_STS 0 "reserved" 1 "open" 2 "closed" 3 "stuck closed" 4 "stuck open";
VAL_ 885 BMS_TotalNegRelay_STS 0 "reserved" 1 "open" 2 "closed" 3 "stuck closed" 4 "stuck open";
VAL_ 897 ACM_Seat_Occupancy_Passenger 0 "Seat_Not_Occupied" 1 "Seat Occupied" 2 "Not_Available" 3 "Failure";
VAL_ 897 ACM_Seat_Occupancy_2nd_Row_Dri 0 "Seat_Not_Occupied" 1 "Seat Occupied" 2 "Not_Available" 3 "Failure";
VAL_ 897 ACM_Seat_Occupancy_2nd_Row_Pas 0 "Seat_Not_Occupied" 1 "Seat Occupied" 2 "Not_Available" 3 "Failure";
VAL_ 897 ACM_Seat_Occupancy_2nd_Row_Mid 0 "Seat_Not_Occupied" 1 "Seat Occupied" 2 "Not_Available" 3 "Failure";
VAL_ 897 ACM_Seat_Belt_Status_Passenger 0 "Not_buckled" 1 "Buckled" 2 "Not_Available" 3 "Failure";
VAL_ 897 ACM_Seat_Belt_Status_Driver 0 "Not_buckled" 1 "Buckled" 2 "Not_Available" 3 "Failure";
VAL_ 897 ACM_Seat_Belt_Status_2nd_Row_Dri 0 "Not_buckled" 1 "Buckled" 2 "Not_Available" 3 "Failure";
VAL_ 897 ACM_Seat_Belt_Status_2nd_Row_Mid 0 "Not_buckled" 1 "Buckled" 2 "Not_Available" 3 "Failure";
VAL_ 897 ACM_Seat_Belt_Status_2nd_Row_Pas 0 "Not_buckled" 1 "Buckled" 2 "Not_Available" 3 "Failure";
VAL_ 905 VCU_IMMO_Sts 0 "init" 1 "pass" 2 "failed";
VAL_ 915 MHU_SET_HudRotateLvl 0 "Invalid" 1 "Level 1" 2 "Level 2" 3 "Level 3" 4 "Level 4" 5 "Level 5" 6 "Level 6" 7 "Level 7" 8 "Reserved" 9 "Reserved" 10 "Reserved" 11 "Reserved" 12 "Reserved" 13 "Reserved" 14 "Reserved" 15 "Reserved";
VAL_ 915 MHU_SET_HudHeightLvl 0 "Invalid" 1 "Level 1" 2 "Level 2" 3 "Level 3" 4 "Level 4" 5 "Level 5" 6 "Level 6" 7 "Level 7" 8 "Level 8" 9 "Level 9" 10 "Level 10" 11 "Level 11" 12 "Level 12" 13 "Level 13" 14 "Level 14" 15 "Level 15" 16 "Level 16" 17 "Level 17" 18 "Level 18" 19 "Level 19" 20 "Level 20" 21 "Level 21" 22 "Reserved";
VAL_ 925 BCM_AHB_Override 0 "not used" 1 "Automatic High Beam request" 2 "AHB  Inhibit by Driver" 3 "invalid";
VAL_ 943 MHU_IPC_ID 0 "Media OFF" 1 "Telephone Name / Number" 2 "Reserved" 3 "USB - Songname, Album, Artist" 4 "BT - Songname, Album, Artist" 5 "IPOD - Songname, Album, Artist" 6 "Radio frequency AM" 7 "Radio frequency FM" 8 "Radio station" 9 "USB Video" 10 "USB Picture" 11 "Android Auto" 12 "Apple Carplay" 13 "Device not connected" 14 "Loading" 15 "Invalid";
VAL_ 964 MHU_Nav_State 0 "Disable" 1 "ON" 2 "Ready to drive" 3 "Arrived at the destination - Finish" 4 "Locating  Location position not avaliable" 5 "Rerouting" 6 "On the way" 7 "Signal Invalid";
VAL_ 964 MHU_NavSource 0 "Here Map (Default embedded map)" 1 "Vietmap" 2 "Apple Map" 3 "Google map " 4 "Reserved" 5 "Reserved" 6 "Reserved" 7 "Signal Invalid";
VAL_ 964 MHU_Nav_DistanceToNextTurnUnits 0 "km" 1 "miles" 2 "m" 3 "yards" 4 "ft" 5 "Reserved" 6 "Reserved" 7 "Reserved";
VAL_ 964 MHU_Nav_ImageChannel_Ready 0 "Disable" 1 "Enable" 2 "Power Off" 3 "Signal Invalid";
VAL_ 964 MHU_Nav_Language 0 "Vietnamese" 1 "English" 2 "Chinese (Simplified)" 3 "Traditional Chinese" 4 "French" 5 "German" 6 "Italian" 7 "Japanese" 8 "Korean" 9 "Spanish (Spain)" 10 "Spanish (Latin)" 11 "Portuguese (Portugal)" 12 "Portuguese (Brazil)" 13 "Arabic" 14 "Catalan" 15 "Croatian" 16 "Czech" 17 "Danish" 18 "Dutch" 19 "Finnish" 20 "Greek" 21 "Hebrew" 22 "Hindi" 23 "Hungarian" 24 "Indonesian" 25 "Malay" 26 "Norwegian" 27 "Polish" 28 "Romanian" 29 "Russian" 30 "Slovak" 31 "Swedish" 32 "Turkish" 33 "Thai" 254 "Raw language" 255 "Signal invalid";
VAL_ 992 VCU_RunningRange_chrg_estSts 0 "Not ready" 1 "Processing" 2 "Estimated" 3 "Failed";
VAL_ 992 VCU_HVbatSoc_charged_estStatus 0 "Not ready" 1 "Processing" 2 "Estimated" 3 "Failed";
VAL_ 993 VCU_MHU_Ack_ChgSche_stt 0 "Charging Schedule Enable" 1 "Charging Schedule Disable" 2 "Reserved" 3 "Signal Invalid";
VAL_ 993 VCU_ValetMode_sts 0 "Inactive" 1 "Active" 255 "Invalid";
VAL_ 1015 MFS_VoiceRecognitionOn_Off 0 "Button not Pressed" 1 "Short Press" 2 "Long Press" 3 "Reserved" 4 "Signal invalid";
VAL_ 1015 MFS_ISAControl 0 "Button not Pressed" 1 "Short Press" 2 "Long Press" 3 "Reserved";
VAL_ 1015 MFS_CruiseSpeedIncrease 0 "Button not Pressed" 1 "Short Press" 2 "Long Press" 3 "Reserved" 4 "Signal invalid";
VAL_ 1015 MFS_TelephoneCall_EndCall 0 "Button not Pressed" 1 "Short Press" 2 "Long Press" 3 "Reserved" 4 "Signal invalid";
VAL_ 1015 MFS_LKAControl 0 "Button not Pressed" 1 "Short Press" 2 "Long Press" 3 "Reserved";
VAL_ 1015 MFS_CruiseGapIncrease 0 "Button not Pressed" 1 "Short Press" 2 "Long Press" 3 "Reserved" 4 "Signal invalid";
VAL_ 1015 MFS_CruiseOn_Off 0 "Button not Pressed" 1 "Short Press" 2 "Long Press" 3 "Reserved" 4 "Signal invalid";
VAL_ 1015 MFS_CruiseGapDecrease 0 "Button not Pressed" 1 "Short Press" 2 "Long Press" 3 "Reserved" 4 "Signal invalid";
VAL_ 1015 MFS_CAN_RESControl 0 "Button not Pressed" 1 "Short Press" 2 "Long Press" 3 "Reserved";
VAL_ 1015 MFS_CruiseSpeedDecrease 0 "Button not Pressed" 1 "Short Press" 2 "Long Press" 3 "Reserved" 4 "Signal invalid";
VAL_ 1015 MFS_M2Control 0 "Button not Pressed" 1 "Short Press" 2 "Long Press" 3 "Reserved";
VAL_ 1015 MFS_SourseControl 0 "Button not Pressed" 1 "Short Press" 2 "Long Press" 3 "Reserved" 4 "Signal invalid";
VAL_ 1015 MFS_UpControl 0 "Button not Pressed" 1 "Short Press" 2 "Long Press" 3 "Reserved" 4 "Signal invalid";
VAL_ 1015 MFS_DownControl 0 "Button not Pressed" 1 "Short Press" 2 "Long Press" 3 "Reserved" 4 "Signal invalid";
VAL_ 1015 MFS_LeftControl 0 "Button not Pressed" 1 "Short Press" 2 "Long Press" 3 "Reserved" 4 "Signal invalid";
VAL_ 1015 MFS_Failure 0 "No Error" 1 "Error";
VAL_ 1015 MFS_RightControl 0 "Button not Pressed" 1 "Short Press" 2 "Long Press" 3 "Reserved" 4 "Signal invalid";
VAL_ 1015 MFS_OK_Control 0 "Button not Pressed" 1 "Short Press" 2 "Long Press" 3 "Reserved" 4 "Signal invalid";
VAL_ 1020 XGW_FOTA_StateConfirm 0 "INIT" 1 "NORMAL" 2 "FOTA FLASHING" 3 "FOTA-SUSPENDED" 4 "FAIL-SAFE-ERROR" 5 "SHUTDOWN" 6 "REMOTE DIAGNOSTICS" 7 "Invalid";
VAL_ 1025 MHU_SET_SunroofGlassLevel 0 "Closed" 127 "Vent" 150 "Stop" 255 "No Request";
VAL_ 1025 MHU_SET_BonnetState 0 "Not pressed" 1 "Pressed" 2 "Reserved" 3 "Signal invalid";
VAL_ 1025 MHU_SET_TrunkState 0 "Not pressed" 1 "Pressed" 2 "Reserved" 3 "Signal invalid";
VAL_ 1025 MHU_SET_SunroofShaderLevel 0 "Closed" 150 "Stop" 255 "No Request";
VAL_ 1025 MHU_SET_DoorSpeedLock 0 "OFF" 1 "5KMH" 2 "10KMH" 3 "15KMH" 4 "20KMH" 5 "25KMH" 6 "Signal invalid";
VAL_ 1025 MHU_SET_WelcomeTriggerCondition 0 "Vehicle unLock" 1 "Driver walk toward" 2 "OFF" 3 "Signal invalid";
VAL_ 1025 MHU_SET_AutoSunroof 0 "OFF" 1 "ON" 2 "AUTO" 3 "Signal invalid";
VAL_ 1025 MHU_SET_RemoteDoorUnlock 0 "Driver door" 1 "All doors" 2 "Reserved" 3 "Signal invalid";
VAL_ 1025 MHU_SET_RemoteLockFeedback 0 "Light" 1 "Horn" 2 "Light/Horn" 3 "OFF" 4 "Signal Invalid";
VAL_ 1025 MHU_SET_FootkickSensor 0 "OFF" 1 "ON" 2 "Reserved" 3 "Signal invalid";
VAL_ 1025 MHU_SET_AutoUnlockDoor 0 "OFF" 1 "On" 2 "Reserved" 3 "Signal Invalid";
VAL_ 1025 MHU_SET_RemoteUnlockFeedback 0 "Blinking" 1 "Dimming" 2 "Low Beam ON" 3 "OFF" 4 "Signal Invalid";
VAL_ 1025 MHU_SET_Childlock 0 "OFF" 1 "ON" 2 "Reserved" 3 "Signal invalid";
VAL_ 1025 MHU_SET_SunroofInitialize 0 "Inactive - Default" 1 "Initialisation" 2 "Manual Open Sunroof" 3 "Manual Close Sunroof" 4 "Manual Open Sunshade" 5 "Manuel Close Sunshade" 6 "Reserved" 7 "Signal invalid";
VAL_ 1026 MHU_SET_DayTimeRunningLight 0 "OFF" 1 "ON" 2 "Reserved" 3 "Signal invalid";
VAL_ 1026 MHU_SET_RearFogLight 0 "OFF" 1 "ON" 2 "Reserved" 3 "Signal invalid";
VAL_ 1026 MHU_SET_FrontFogLight 0 "OFF" 1 "ON" 2 "Reserved" 3 "Signal invalid";
VAL_ 1026 MHU_SET_WelcomeDimmingHeadlight 0 "OFF" 1 "ON" 2 "Reserved" 3 "Signal invalid";
VAL_ 1026 MHU_SET_FootwellLightMode 0 "OFF" 1 "ON" 2 "AUTO" 3 "Signal invalid";
VAL_ 1026 MHU_SET_ExteriorLight 0 "OFF" 1 "Parking" 2 "ON" 3 "AUTO" 4 "Signal invalid";
VAL_ 1026 MHU_SET_TRWarningSignals 0 "Off BCM warning signals" 1 "On BCM warning signals" 2 "Reserved" 3 "Signal Invalid";
VAL_ 1026 MHU_SET_FrontDomeLamp 0 "OFF" 1 "ON" 2 "AUTO" 3 "Signal invalid";
VAL_ 1026 MHU_SET_FollowMeHome 0 "OFF" 1 "30 secs" 2 "60 secs" 3 "90 secs" 4 "120 secs" 5 "Signal invalid";
VAL_ 1026 MHU_SET_ADB_AHB 0 "OFF" 1 "ON" 2 "Reserved" 3 "Signal Invalid";
VAL_ 1026 MHU_SET_WelcomeAnimation 0 "OFF" 1 "Light dance" 2 "Vegas blink" 3 "Pulse and blink" 4 "Reserved" 5 "Signal invalid";
VAL_ 1026 MHU_SET_ChargingAnimation 0 "OFF" 1 "ON" 2 "Reserved" 3 "Signal invalid";
VAL_ 1026 MHU_SET_Auto_Leveling 0 "OFF" 1 "ON" 2 "Reserved" 3 "Signal Invalid";
VAL_ 1027 MHU_VCU_CreepDisable_stt 0 "No request" 1 "Creep Disable request";
VAL_ 1027 MHU_BrakeRegenMode 0 "HIGH" 1 "MID" 2 "LOW" 3 "Signal Invalid";
VAL_ 1027 MHU_ChargeScheduleSet 0 "disable" 1 "Enable" 2 "No effect" 3 "Invalid";
VAL_ 1027 MHU_ChargingRequest 0 "Stop charging" 1 "Start charging" 2 "Pause charging" 3 "No effect";
VAL_ 1027 MHU_ChgPort_Open_req 0 "No request" 1 "Requesting" 2 "Reserved" 3 "Signal invalid";
VAL_ 1027 MHU_SET_DrivingModeSwitch 0 "NORMAL" 1 "ECO" 2 "SPORT" 3 "Signal invalid";
VAL_ 1027 MHU_ValetMode_Activation 0 "Inactive" 1 "Active" 2 "No effect" 255 "Invalid";
VAL_ 1028 MHU_SET_MirrorAdjustLeft 0 "OFF" 1 "ON" 2 "Reserved" 3 "Signal invalid";
VAL_ 1028 MHU_SET_MirrorAdjustRight 0 "OFF" 1 "ON" 2 "Reserved" 3 "Signal invalid";
VAL_ 1028 MHU_SET_MirrorManual 0 "Fold" 1 "Unfold" 2 "Reserved" 3 "Signal invalid";
VAL_ 1029 MHU_SET_CCUF_AirCondition 0 "Not pressed" 1 "Pressed" 2 "Reserved" 3 "Signal invalid";
VAL_ 1029 MHU_SET_CCUF_AutoAC 0 "Not pressed" 1 "Pressed" 2 "Reserved" 3 "Signal invalid";
VAL_ 1029 MHU_SET_CCUF_MaxAc 0 "Not pressed" 1 "Pressed" 2 "Reserved" 3 "Signal invalid";
VAL_ 1029 MHU_SET_CCUF_FanSpeed 0 "OFF" 1 "Level1" 2 "Level2" 3 "Level3" 4 "Level4" 5 "Level5" 6 "Level6" 7 "Signal invalid";
VAL_ 1029 MHU_SET_CCUF_Recirculation 0 "Inside" 1 "Outside" 2 "Auto" 3 "Signal invalid";
VAL_ 1029 MHU_SET_CCUF_Ion 0 "Not pressed" 1 "Pressed" 2 "Reserved" 3 "Signal invalid";
VAL_ 1029 MHU_SET_CCUF_FlapPosition 0 "OFF" 1 "Face" 2 "Face and Feet" 3 "Feet" 4 "Feet and Defrost" 5 "Defrost" 6 "Default" 7 "Signal Invalid";
VAL_ 1029 MHU_SET_CCUF_SyncClimateZone 0 "Not pressed" 1 "Pressed" 2 "Reserved" 3 "Signal invalid";
VAL_ 1029 MHU_SET_CCUF_FrontDefrost 0 "Not pressed" 1 "Pressed" 2 "Reserved" 3 "Signal invalid";
VAL_ 1030 MHU_SET_SeatHeatingFrontL 0 "OFF" 1 "Level1" 2 "Level2" 3 "Level3" 4 "Signal invalid";
VAL_ 1030 MHU_SET_SeatHeatingFrontR 0 "OFF" 1 "Level1" 2 "Level2" 3 "Level3" 4 "Signal invalid";
VAL_ 1030 MHU_SET_SeatHeatingReartL 0 "OFF" 1 "Level1" 2 "Level2" 3 "Level3" 4 "Signal invalid";
VAL_ 1030 MHU_SET_SeatHeatingRearR 0 "OFF" 1 "Level1" 2 "Level2" 3 "Level3" 4 "Signal invalid";
VAL_ 1030 MHU_SET_SeatCoolingFrontL 0 "OFF" 1 "Level1" 2 "Level2" 3 "Level3" 4 "Signal invalid";
VAL_ 1030 MHU_SET_SeatCoolingFrontR 0 "OFF" 1 "Level1" 2 "Level2" 3 "Level3" 4 "Signal invalid";
VAL_ 1030 MHU_SET_SeatCoolingRearL 0 "OFF" 1 "Level1" 2 "Level2" 3 "Level3" 4 "Signal invalid";
VAL_ 1030 MHU_SET_SeatCoolingRearR 0 "OFF" 1 "Level1" 2 "Level2" 3 "Level3" 4 "Signal invalid";
VAL_ 1032 MHU_SET_MirrorAuto 0 "OFF" 1 "ON" 2 "Reserved" 3 "Signal invalid";
VAL_ 1032 MHU_SET_MirrorAutoUnfold 0 "Vehicle Unlock" 1 "Driver walk toward" 2 "OFF" 3 "Signal invalid";
VAL_ 1032 MHU_SET_WLC 0 "OFF" 1 "ON" 2 "Reserved" 3 "Signal invalid";
VAL_ 1032 MHU_SET_AutoRearWiper 0 "OFF" 1 "ON" 2 "Reserved" 3 "Signal invalid";
VAL_ 1032 MHU_SET_RearHeatedWindow 0 "Not pressed" 1 "Pressed" 2 "Reserved" 3 "Signal invalid";
VAL_ 1032 MHU_TPMSReset 0 "Noreset" 1 "Reset" 2 "Reserved" 3 "Signal invalid";
VAL_ 1032 MHU_SET_MirrorDefaultSetting 0 "Not pressed" 1 "Pressed" 2 "Reserved" 3 "Signal invalid";
VAL_ 1032 MHU_SET_MirrorReverseLink 0 "OFF" 1 "ON" 2 "Reserved" 3 "Signal invalid";
VAL_ 1032 MHU_SET_AntiTheftMode 0 "OFF" 1 "Light Only" 2 "Horn Only" 3 "Light and Horn";
VAL_ 1032 MHU_SET_WLCReminder 0 "OFF" 1 "ON" 2 "Reserved" 3 "Signal invalid";
VAL_ 1032 MHU_SET_ClimateKeepOn 0 "OFF" 1 "PET" 2 "CAMP" 3 "REMOTE CONTROL";
VAL_ 1032 MHU_SET_WLC2 0 "OFF" 1 "ON" 2 "Reserved" 3 "Signal invalid";
VAL_ 1032 MHU_SET_WLC2Reminder 0 "OFF" 1 "ON" 2 "Reserved" 3 "Signal invalid";
VAL_ 1032 MHU_IntrusionAlertStatus 0 "OFF" 1 "ON" 2 "Stop Alarm" 3 "Signal invalid";
VAL_ 1033 ADAS_Warning_Flag_1 0 "No Error" 1 "Error";
VAL_ 1033 ADAS_Warning_Flag_2 0 "No Error" 1 "Error";
VAL_ 1033 ADAS_Warning_Flag_3 0 "No Error" 1 "Error";
VAL_ 1033 ADAS_Warning_Flag_4 0 "No Error" 1 "Error";
VAL_ 1033 ADAS_Warning_Flag_5 0 "No Error" 1 "Error";
VAL_ 1033 ADAS_Warning_Flag_6 0 "No Error" 1 "Error";
VAL_ 1033 ADAS_Warning_Flag_7 0 "No Error" 1 "Error";
VAL_ 1033 ADAS_Warning_Flag_8 0 "No Error" 1 "Error";
VAL_ 1033 ADAS_Warning_Flag_9 0 "No Error" 1 "Error";
VAL_ 1033 ADAS_Warning_Flag_10 0 "No Error" 1 "Error";
VAL_ 1033 ADAS_Warning_Flag_11 0 "No Error" 1 "Error";
VAL_ 1033 ADAS_Warning_Flag_12 0 "No Error" 1 "Error";
VAL_ 1033 ADAS_Warning_Flag_13 0 "No Error" 1 "Error";
VAL_ 1033 ADAS_Warning_Flag_14 0 "No Error" 1 "Error";
VAL_ 1033 ADAS_Warning_Flag_15 0 "No Error" 1 "Error";
VAL_ 1033 ADAS_Warning_Flag_16 0 "No Error" 1 "Error";
VAL_ 1033 ADAS_Warning_Flag_17 0 "No Error" 1 "Error";
VAL_ 1033 ADAS_Warning_Flag_18 0 "No Error" 1 "Error";
VAL_ 1033 ADAS_Warning_Flag_19 0 "No Error" 1 "Error";
VAL_ 1033 ADAS_Warning_Flag_20 0 "No Error" 1 "Error";
VAL_ 1033 ADAS_Warning_Flag_21 0 "No Error" 1 "Error";
VAL_ 1033 ADAS_Warning_Flag_22 0 "No Error" 1 "Error";
VAL_ 1033 ADAS_Warning_Flag_23 0 "No Error" 1 "Error";
VAL_ 1033 ADAS_Warning_Flag_24 0 "No Error" 1 "Error";
VAL_ 1033 ADAS_Warning_Flag_25 0 "No Error" 1 "Error";
VAL_ 1033 ADAS_Warning_Flag_26 0 "No Error" 1 "Error";
VAL_ 1033 ADAS_Warning_Flag_27 0 "No Error" 1 "Error";
VAL_ 1033 ADAS_Warning_Flag_28 0 "No Error" 1 "Error";
VAL_ 1033 ADAS_Warning_Flag_29 0 "No Error" 1 "Error";
VAL_ 1033 ADAS_Warning_Flag_30 0 "No Error" 1 "Error";
VAL_ 1033 ADAS_Warning_Flag_31 0 "No Error" 1 "Error";
VAL_ 1033 ADAS_Warning_Flag_32 0 "No Error" 1 "Error";
VAL_ 1033 ADAS_Warning_Flag_33 0 "No Error" 1 "Error";
VAL_ 1033 ADAS_Warning_Flag_34 0 "No Error" 1 "Error";
VAL_ 1033 ADAS_Warning_Flag_35 0 "No Error" 1 "Error";
VAL_ 1033 ADAS_Warning_Flag_36 0 "No Error" 1 "Error";
VAL_ 1033 ADAS_Warning_Flag_37 0 "No Error" 1 "Error";
VAL_ 1033 ADAS_Warning_Flag_38 0 "No Error" 1 "Error";
VAL_ 1033 ADAS_Warning_Flag_39 0 "No Error" 1 "Error";
VAL_ 1033 ADAS_Warning_Flag_40 0 "No Error" 1 "Error";
VAL_ 1033 ADAS_Warning_Flag_41 0 "No Error" 1 "Error";
VAL_ 1033 ADAS_Warning_Flag_42 0 "No Error" 1 "Error";
VAL_ 1033 ADAS_Warning_Flag_43 0 "No Error" 1 "Error";
VAL_ 1033 ADAS_Warning_Flag_44 0 "No Error" 1 "Error";
VAL_ 1033 ADAS_Warning_Flag_45 0 "No Error" 1 "Error";
VAL_ 1033 ADAS_Warning_Flag_46 0 "No Error" 1 "Error";
VAL_ 1033 ADAS_Warning_Flag_47 0 "No Error" 1 "Error";
VAL_ 1033 ADAS_Warning_Flag_48 0 "No Error" 1 "Error";
VAL_ 1033 ADAS_Warning_Flag_49 0 "No Error" 1 "Error";
VAL_ 1033 ADAS_Warning_Flag_50 0 "No Error" 1 "Error";
VAL_ 1033 ADAS_Warning_Flag_51 0 "No Error" 1 "Error";
VAL_ 1034 MHU_SET_HudUIContent 0 "Default (Only speed)" 1 "+ADAS" 2 "+Navigation" 3 "+ADAS + Navigation" 4 "+ Power-Regen gauge" 5 "+ Power-Regen gauge + ADAS" 6 "+ Power-Regen gauge + Navigation" 7 "+ Power-Regen + ADAS + Navigation";
VAL_ 1034 MHU_SET_HudUIColor 0 "White (Default)" 1 "Green" 2 "Orange";
VAL_ 1034 MHU_SET_HudScreenOnOFF 0 "OFF" 1 "ON" 2 "Reserved" 3 "Signal invalid";
VAL_ 1034 MHU_SET_UserBrightnessLvl 0 "No action" 1 "Level 1" 2 "Level 2" 3 "Level 3" 4 "Level 4" 5 "Level 5" 6 "Level 6" 7 "Level 7" 8 "Level 8 " 9 "Level 9" 10 "Level 10" 11 "Level 11" 12 "Level 12" 13 "Level 13" 14 "Level 14" 15 "Level 15" 16 "Level 16" 17 "Level 17" 18 "Level 18" 19 "Level 19" 20 "Level 20" 21 "Level 21 " 22 "Reserved" 23 "Reserved" 24 "Reserved" 25 "Reserved" 26 "Reserved" 27 "Reserved" 28 "Reserved" 29 "Reserved" 30 "Reserved" 31 "Reserved";
VAL_ 1034 MHU_SET_HudWorkingMode 0 "Working Mode" 1 "Position adjustment Mode" 2 "EOL Mode" 3 "Engineering mode";
VAL_ 1034 MHU_SET_HudUISize 0 "Small" 1 "Mid" 2 "Large" 3 "Reserved";
VAL_ 1034 MHU_SET_UIContentMediaInfo 0 "OFF" 1 "ON";
VAL_ 1034 MHU_SET_UIContentCallInfo 0 "OFF" 1 "ON";
VAL_ 1034 MHU_SET_UIContentPoweRegen 0 "OFF" 1 "ON";
VAL_ 1035 MHU_SET_AvasSound 0 "Enhanced" 1 "Normal" 2 "Minimized" 3 "OFF";
VAL_ 1036 MHU_DrvSeat_Control_Status 0 "Idle" 1 "Request seat moving" 2 "Reserved" 3 "Invalid value";
VAL_ 1046 BCM_STAT_Mirror 0 "Fold" 1 "Unfold" 2 "Reserved" 3 "Signal Invalid";
VAL_ 1046 BCM_STAT_MirrorAdjustLeft 0 "OFF" 1 "ON" 2 "Reserved" 3 "Signal invalid";
VAL_ 1046 BCM_STAT_MirrorAdjustRight 0 "OFF" 1 "ON" 2 "Reserved" 3 "Signal invalid";
VAL_ 1049 SHVU_STAT_SeatHeatingFrontL 0 "OFF" 1 "Level1" 2 "Level2" 3 "Level3" 4 "Signal invalid";
VAL_ 1049 SHVU_STAT_SeatHeatingFrontR 0 "OFF" 1 "Level1" 2 "Level2" 3 "Level3" 4 "Signal invalid";
VAL_ 1049 SHVU_STAT_SeatCoolingFrontL 0 "OFF" 1 "Level1" 2 "Level2" 3 "Level3" 4 "Signal invalid";
VAL_ 1049 SHVU_STAT_SeatCoolingFrontR 0 "OFF" 1 "Level1" 2 "Level2" 3 "Level3" 4 "Signal invalid";
VAL_ 1049 SHVU_STAT_FrontSeatVentSts 0 "Normal Operation" 1 "Failure" 2 "Reserved" 3 "Signal invalid";
VAL_ 1050 SHVU_STAT_SeatCoolingRearL 0 "OFF" 1 "Level1" 2 "Level2" 3 "Level3" 4 "Signal invalid";
VAL_ 1050 SHVU_STAT_SeatCoolingRearR 0 "OFF" 1 "Level1" 2 "Level2" 3 "Level3" 4 "Signal invalid";
VAL_ 1050 SHVU_STAT_SeatHeatingReartL 0 "OFF" 1 "Level1" 2 "Level2" 3 "Level3" 4 "Signal invalid";
VAL_ 1050 SHVU_STAT_SeatHeatingRearR 0 "OFF" 1 "Level1" 2 "Level2" 3 "Level3" 4 "Signal invalid";
VAL_ 1050 SHVU_STAT_RearSeatVentSts 0 "Normal Operation" 1 "Failure" 2 "Reserved" 3 "Signal invalid";
VAL_ 1052 PSM_Seat_track_pos_Dri 0 "Front position" 1 "Not Front position" 2 "Failure" 3 "Invalid Value";
VAL_ 1052 PSM_Seat_track_posPas 0 "Front position" 1 "Not Front position" 2 "Failure" 3 "Invalid Value";
VAL_ 1053 BCM_STAT_AutoRearWiper 0 "OFF" 1 "ON" 2 "Reserved" 3 "Signal invalid";
VAL_ 1053 BCM_STAT_MirrorFoldSetting 0 "Auto Fold OFF" 1 "Auto Fold ON" 2 "Reserved" 3 "Signal invalid";
VAL_ 1053 BCM_STAT_IMMO_KeyfobID2 0 "No trigger from MHU" 1 "Fob1" 2 "Fob2" 3 "key illegal" 4 "No key found" 5 "Searching" 6 "Reserved" 7 "Signal invalid";
VAL_ 1053 BCM_STAT_MirrorAutoUnfold 0 "Vehicle Unlock" 1 "Driver walk toward" 2 "OFF" 3 "Signal invalid";
VAL_ 1053 BCM_STAT_MirrorReverseLink 0 "OFF" 1 "ON" 2 "Reserved" 3 "Signal invalid";
VAL_ 1053 BCM_STAT_MirrorDefaultSTATting 0 "Not pressed" 1 "Pressed" 2 "Reserved" 3 "Signal invalid";
VAL_ 1053 BCM_STAT_WelcomeTriggerCondition 0 "Vehicle unLock" 1 "Driver walk toward" 2 "OFF" 3 "Signal invalid";
VAL_ 1053 BCM_STAT_FrontDomeLamp 0 "OFF" 1 "ON" 2 "AUTO" 3 "Signal invalid";
VAL_ 1053 BCM_STAT_FollowMeHome 0 "OFF" 1 "30 secs" 2 "60 secs" 3 "90 secs" 4 "120 secs" 5 "Signal invalid";
VAL_ 1053 BCM_STAT_ExteriorLight 0 "OFF" 1 "Parking" 2 "ON" 3 "AUTO" 4 "Signal invalid";
VAL_ 1053 BCM_STAT_RemoteLockFeedback 0 "OFF" 1 "Lights and Horn" 2 "Lights Only" 3 "Horn Only" 4 "Reserved" 5 "Reserved" 6 "Reserved" 7 "Signal invalid";
VAL_ 1053 BCM_STAT_RemoteDoorUnlock 0 "Reserved" 1 "Driver door" 2 "All doors" 3 "Signal invalid";
VAL_ 1053 BCM_STAT_AutoDoorUnlock 0 "OFF" 1 "ON" 2 "Reserved" 3 "Signal invalid";
VAL_ 1053 BCM_STAT_WiperServiceMode 0 "OFF" 1 "ON" 2 "Reserved" 3 "Signal Invalid";
VAL_ 1053 BCM_STAT_IMMO_KeyfobID 0 "No Key Found" 1 "ID1" 2 "ID2" 3 "Signal Invalid";
VAL_ 1053 BCM_STAT_RearHeatedWindowMirror 0 "OFF" 1 "ON" 2 "Reserved" 3 "Signal invalid";
VAL_ 1053 BCM_STAT_AntiTheftMode 0 "OFF" 1 "Light Only" 2 "Horn Only" 3 "Light and Horn" 4 "Signal invalid";
VAL_ 1053 BCM_STAT_ClimateKeepOnSts 0 "OFF" 1 "PET" 2 "CAMP" 3 "REMOTE CONTROL";
VAL_ 1053 BCM_STAT_FKSfeedback 0 "OFF" 1 "ON" 2 "Reserved" 3 "Signal Invalid";
